VERSION ""

NS_ :

BS_:

BU_: WCM VPM VLM VKM UVM TIM TEST_TOOL_2 TEST_TOOL_1 TCP TCM TCCM3 TCCM STC SRR_SRR SRR_SLR SRR_RR SRR_RF SRR_LR_CR SRR_LF SIB SDM SCL SBZA_R SBZA_L SBM SADS RadioLow RSC RDCM PTM PDR PA NVM MTCM_R MTCM_L MSM_RR MSM_P MSM_LR MSM_D MSB2 MSB1 MRCM_R MRCM_L MFC LRR_HC LRR LIB1 IPC ICS_Info ICCM HVAC_FP_R HVAC_FP_F HUD_CAN HDLM FCM_LC FCM EPS EOCM_HCP2 EOCM_HCP1 EOCM ELM ECP_X1 ECP_MC ECP_E ECM EBCM DMS DEFC DCM CSM CMMb CMMa CGM BSM_MH BSM BCM ARS ARB APA AOS AMP ALC AHS AHL_AFL AGC

BO_ 1242 CGM_CAN5_PDU34: 8 CGM
 SG_ RRSCDS_Massg : 0|2@0+ (1,0) [0|2] "" CSM,RadioLow
 SG_ RRSCDS_LmbrUDnFdRr : 3|3@0+ (1,0) [0|5] "" CSM,RadioLow
 SG_ RRSCDS_MassgTyp : 7|4@0+ (1,0) [0|15] "" CSM,RadioLow
 SG_ RRSCDS_BkCshBlstInOt : 10|3@0+ (1,0) [0|5] "" CSM,RadioLow
 SG_ RRSCDS_HdrstFwdRrwd : 12|2@0+ (1,0) [0|3] "" CSM,RadioLow
 SG_ RRSCDS_LmbrFwdRr : 14|2@0+ (1,0) [0|3] "" CSM,RadioLow
 SG_ RRSCDS_HdrstFdRrUDn : 17|3@0+ (1,0) [0|5] "" CSM,RadioLow
 SG_ RRSCDS_UprShldrFdRr : 19|2@0+ (1,0) [0|3] "" CSM,RadioLow
 SG_ RRSCDS_CshBlstrInOut : 21|2@0+ (1,0) [0|3] "" CSM,RadioLow
 SG_ RRSCDS_HdrstWngInOt : 23|2@0+ (1,0) [0|3] "" CSM,RadioLow
 SG_ RRSCDS_HdrstUpDn : 25|2@0+ (1,0) [0|3] "" CSM,RadioLow
 SG_ RRSCDS_LmbrUpDwn : 27|2@0+ (1,0) [0|3] "" CSM,RadioLow
 SG_ RRSCDS_MassgIntsty : 30|3@0+ (1,0) [0|7] "" CSM,RadioLow
 SG_ EDADS_ShftIndSt : 32|2@0+ (1,0) [0|2] "" CSM,IPC
 SG_ RRSCDS_CshLgAdjFdRr : 34|2@0+ (1,0) [0|3] "" CSM,RadioLow
 SG_ RRSCDS_HdrstTltFwdRr : 36|2@0+ (1,0) [0|3] "" CSM,RadioLow
 SG_ RRSCDS_BkBlstrInOut : 38|2@0+ (1,0) [0|3] "" CSM,RadioLow
 SG_ RRSCDS_DispReq : 39|1@0+ (1,0) [0|1] "" CSM,RadioLow
 SG_ EDADS_RcmndtFwdGr : 42|4@0+ (1,0) [0|15] "" CSM,IPC
 SG_ EDADS_CrntFwdMsdGr : 46|4@0+ (1,0) [0|15] "" CSM,IPC
 SG_ CnvtblTpWndMtnReq : 50|3@0+ (1,0) [0|4] "" CSM
 SG_ CnvtblTpStat : 53|3@0+ (1,0) [0|5] "" AMP,CSM,IPC,RadioLow,VKM
 SG_ EDADS_EcoDrvShftIO : 54|1@0+ (1,0) [0|1] "" CSM,IPC
 SG_ DrvDrAjrStat : 56|1@0+ (1,0) [0|1] "" AMP,CSM,IPC,RadioLow,TCP,VKM
 SG_ DrvDrAjrStat_Inv : 57|1@0+ (1,0) [0|1] "" CSM,IPC,TCP,VKM
 SG_ FCAACCGapSeltn : 60|3@0+ (1,0) [0|4] "" CSM,IPC
 SG_ EsyExtCstCurSetVal : 63|3@0+ (1,0) [0|7] "" CSM,RadioLow

BO_ 1243 CGM_CAN5_PDU35: 8 CGM
 SG_ RFSCDS_LmbrUDnFdRr : 1|3@0+ (1,0) [0|5] "" CSM,RadioLow
 SG_ RFSCDS_UprShldrFdRr : 3|2@0+ (1,0) [0|3] "" CSM,RadioLow
 SG_ RFSCDS_MassgTyp : 7|4@0+ (1,0) [0|15] "" CSM,RadioLow
 SG_ RFSCDS_HdrstWngInOt : 9|2@0+ (1,0) [0|3] "" CSM,RadioLow
 SG_ RFSCDS_DispReq : 10|1@0+ (1,0) [0|1] "" CSM,RadioLow
 SG_ RFSCDS_BkBlstrInOut : 12|2@0+ (1,0) [0|3] "" CSM,RadioLow
 SG_ RFSCDS_HdrstFwdRrwd : 14|2@0+ (1,0) [0|3] "" CSM,RadioLow
 SG_ RFSCDS_LmbrFwdRr : 17|2@0+ (1,0) [0|3] "" CSM,RadioLow
 SG_ RFSCDS_HdrstTltFwdRr : 19|2@0+ (1,0) [0|3] "" CSM,RadioLow
 SG_ RFSCDS_HdrstUpDn : 21|2@0+ (1,0) [0|3] "" CSM,RadioLow
 SG_ RFSCDS_Massg : 23|2@0+ (1,0) [0|2] "" CSM,RadioLow
 SG_ RFSCDS_MassgIntsty : 26|3@0+ (1,0) [0|7] "" CSM,RadioLow
 SG_ RFSCDS_CshLgAdjFdRr : 28|2@0+ (1,0) [0|3] "" CSM,RadioLow
 SG_ RFSCDS_BkCshBlstInOt : 31|3@0+ (1,0) [0|5] "" CSM,RadioLow
 SG_ RPARS_LtCntr : 32|4@0+ (1,0) [0|14] "" CSM,IPC,RadioLow
 SG_ RFSCDS_LmbrUpDwn : 34|2@0+ (1,0) [0|3] "" CSM,RadioLow
 SG_ RFSCDS_HdrstFdRrUDn : 37|3@0+ (1,0) [0|5] "" CSM,RadioLow
 SG_ RFSCDS_CshBlstrInOut : 39|2@0+ (1,0) [0|3] "" CSM,RadioLow
 SG_ RPARS_RtCntr : 40|4@0+ (1,0) [0|14] "" CSM,IPC,RadioLow
 SG_ RPARS_Rt : 44|4@0+ (1,0) [0|14] "" CSM,IPC,RadioLow
 SG_ MemCmd : 48|4@0+ (1,0) [0|15] "" CSM,IPC
 SG_ RPARS_Lt : 52|4@0+ (1,0) [0|14] "" CSM,IPC,RadioLow
 SG_ CoDrvDrAjrStat : 56|1@0+ (1,0) [0|1] "" AMP,CSM,IPC,RadioLow,TCP,VKM
 SG_ CoDrvDrAjrStat_Inv : 57|1@0+ (1,0) [0|1] "" CSM,TCP,VKM
 SG_ AutMemRclCstCurSetVal : 60|3@0+ (1,0) [0|6] "" CSM,RadioLow

BO_ 1244 CGM_CAN5_PDU36: 8 CGM
 SG_ LRSCDS_BkBlstrInOut : 0|2@0+ (1,0) [0|3] "" CSM,RadioLow
 SG_ LRSCDS_UprShldrFdRr : 2|2@0+ (1,0) [0|3] "" CSM,RadioLow
 SG_ LRSCDS_CshBlstrInOut : 4|2@0+ (1,0) [0|3] "" CSM,RadioLow
 SG_ LRSCDS_HdrstFdRrUDn : 7|3@0+ (1,0) [0|5] "" CSM,RadioLow
 SG_ LRSCDS_HdrstTltFwdRr : 9|2@0+ (1,0) [0|3] "" CSM,RadioLow
 SG_ LRSCDS_HdrstUpDn : 11|2@0+ (1,0) [0|3] "" CSM,RadioLow
 SG_ LRSCDS_LmbrUpDwn : 13|2@0+ (1,0) [0|3] "" CSM,RadioLow
 SG_ LRSCDS_DispReq : 14|1@0+ (1,0) [0|1] "" CSM,RadioLow
 SG_ LRSCDS_MassgIntsty : 18|3@0+ (1,0) [0|7] "" CSM,RadioLow
 SG_ LRSCDS_HdrstWngInOt : 20|2@0+ (1,0) [0|3] "" CSM,RadioLow
 SG_ LRSCDS_LmbrUDnFdRr : 23|3@0+ (1,0) [0|5] "" CSM,RadioLow
 SG_ LRSCDS_CshLgAdjFdRr : 25|2@0+ (1,0) [0|3] "" CSM,RadioLow
 SG_ LRSCDS_HdrstFwdRrwd : 27|2@0+ (1,0) [0|3] "" CSM,RadioLow
 SG_ LRSCDS_LmbrFwdRr : 29|2@0+ (1,0) [0|3] "" CSM,RadioLow
 SG_ LRSCDS_Massg : 31|2@0+ (1,0) [0|2] "" CSM,RadioLow
 SG_ SAP_SecAxlOpMdAuth : 32|4@0+ (1,0) [0|9] "" CSM,IPC,TCP
 SG_ LRSCDS_BkCshBlstInOt : 35|3@0+ (1,0) [0|5] "" CSM,RadioLow
 SG_ LRSCDS_MassgTyp : 39|4@0+ (1,0) [0|15] "" CSM,RadioLow
 SG_ SAP_SecAxl4WDAWDEstTrqAuth : 40|10@0+ (10,0) [0|10230] "Nm" CSM
 SG_ SAP_SecAxl4WDAWDStatAuth : 42|2@0+ (1,0) [0|3] "" CSM
 SG_ SAP_SecAxlOpMdAuth_Inv : 43|1@0+ (1,0) [0|1] "" CSM
 SG_ SAP_SecAxl4WDAWDEstTrqAuth_Inv : 44|1@0+ (1,0) [0|1] "" CSM
 SG_ AdpLghtRspTypCstCurSetVal : 58|3@0+ (1,0) [0|7] "" CSM,RadioLow
 SG_ HSP_HptcStPrsntAuth : 59|1@0+ (1,0) [0|1] "" CSM
 SG_ HSP_DrvAlrtTypCstCurrSetValAuth : 62|3@0+ (1,0) [0|2] "" CSM,RadioLow

BO_ 1245 CGM_CAN5_PDU37: 8 CGM
 SG_ LFSCDS_LmbrUDnFdRr : 0|3@0+ (1,0) [0|5] "" CSM,RadioLow
 SG_ LFSCDS_DispReq : 1|1@0+ (1,0) [0|1] "" CSM,RadioLow
 SG_ LFSCDS_UprShldrFdRr : 3|2@0+ (1,0) [0|3] "" CSM,RadioLow
 SG_ LFSCDS_LmbrUpDwn : 5|2@0+ (1,0) [0|3] "" CSM,RadioLow
 SG_ LFSCDS_Massg : 7|2@0+ (1,0) [0|2] "" CSM,RadioLow
 SG_ LFSCDS_BkBlstrInOut : 9|2@0+ (1,0) [0|3] "" CSM,RadioLow
 SG_ LFSCDS_HdrstTltFwdRr : 11|2@0+ (1,0) [0|3] "" CSM,RadioLow
 SG_ LFSCDS_LmbrFwdRr : 13|2@0+ (1,0) [0|3] "" CSM,RadioLow
 SG_ LFSCDS_MassgTyp : 18|4@0+ (1,0) [0|15] "" CSM,RadioLow
 SG_ LFSCDS_HdrstFdRrUDn : 21|3@0+ (1,0) [0|5] "" CSM,RadioLow
 SG_ LFSCDS_CshBlstrInOut : 23|2@0+ (1,0) [0|3] "" CSM,RadioLow
 SG_ LFSCDS_HdrstUpDn : 25|2@0+ (1,0) [0|3] "" CSM,RadioLow
 SG_ LFSCDS_HdrstWngInOt : 27|2@0+ (1,0) [0|3] "" CSM,RadioLow
 SG_ LFSCDS_BkCshBlstInOt : 30|3@0+ (1,0) [0|5] "" CSM,RadioLow
 SG_ SDGPARS_CntrLtSd : 32|4@0+ (1,0) [0|14] "" IPC
 SG_ LFSCDS_MassgIntsty : 35|3@0+ (1,0) [0|7] "" CSM,RadioLow
 SG_ LFSCDS_CshLgAdjFdRr : 37|2@0+ (1,0) [0|3] "" CSM,RadioLow
 SG_ LFSCDS_HdrstFwdRrwd : 39|2@0+ (1,0) [0|3] "" CSM,RadioLow
 SG_ SDGPARS_FrtLtSd : 40|4@0+ (1,0) [0|14] "" IPC
 SG_ SDGPARS_RrRtSd : 44|4@0+ (1,0) [0|14] "" IPC
 SG_ SDGPARS_RrLtSd : 48|4@0+ (1,0) [0|14] "" IPC
 SG_ SDGPARS_CntrRtSd : 52|4@0+ (1,0) [0|14] "" IPC
 SG_ AutoHldEnbld : 56|1@0+ (1,0) [0|1] "" IPC
 SG_ SDGPARS_FrtRtSd : 60|4@0+ (1,0) [0|14] "" IPC

BO_ 1246 CGM_CAN5_PDU38: 8 CGM
 SG_ PCOSN_NtfnSecRowCntrStBltSts : 1|2@0+ (1,0) [0|3] "" TCP
 SG_ PCOSN_NtfnSecRowLtStBltSts : 3|2@0+ (1,0) [0|3] "" TCP
 SG_ PCOSN_NtfnThrdRowCntrStBltSts : 5|2@0+ (1,0) [0|3] "" TCP
 SG_ PCOSN_NtfnImpDeltVelTxSts : 7|2@0+ (1,0) [0|2] "" TCP
 SG_ PCOSN_NtfnImpMaxLongDeltVel : 9|8@0- (1,0) [-128|127] "kph" TCP
 SG_ PCOSN_NtfnSecRowCntrStOccpSts : 11|2@0+ (1,0) [0|3] "" TCP
 SG_ PCOSN_NtfnSecRowLtStOccpSts : 13|2@0+ (1,0) [0|3] "" TCP
 SG_ PCOSN_NtfnSecRowRtStBltSts : 15|2@0+ (1,0) [0|3] "" TCP
 SG_ PCOSN_NtfnThrdRowCntrStOccpSts : 17|2@0+ (1,0) [0|3] "" TCP
 SG_ PCOSN_NtfnImpMaxLatDeltVel : 31|8@0- (1,0) [-128|127] "kph" TCP
 SG_ PCOSN_NtfnEvntSyncCnt : 39|8@0+ (1,0) [0|255] "" TCP
 SG_ PCOSN_NtfnThrdRowRtStOccpSts : 40|2@0+ (1,0) [0|3] "" TCP
 SG_ PCOSN_NtfnFrstPsngrStBltSts : 42|2@0+ (1,0) [0|3] "" TCP
 SG_ PCOSN_NtfnFrstPsngrStOccpSts : 45|3@0+ (1,0) [0|3] "" TCP
 SG_ PCOSN_NtfnSecRowRtStOccpSts : 47|2@0+ (1,0) [0|3] "" TCP
 SG_ PCOSN_NtfnThrdRowLtStOccpSts : 48|2@0+ (1,0) [0|3] "" TCP
 SG_ PCOSN_NtfnThrdRowRtStBltSts : 50|2@0+ (1,0) [0|3] "" TCP
 SG_ PCOSN_NtfnDrvrStBltSts : 52|2@0+ (1,0) [0|3] "" TCP
 SG_ PCOSN_NtfnThrdRowLtStBltSts : 54|2@0+ (1,0) [0|3] "" TCP
 SG_ TDAP_DrvrStMemIdfrAuth : 58|3@0+ (1,0) [0|7] "" CSM,IPC
 SG_ TDAP_DrvrIdfrAuth : 61|3@0+ (1,0) [0|7] "" CSM,IPC,TCP,WCM
 SG_ TDAP_TeenDrvrActvAuth : 62|1@0+ (1,0) [0|1] "" CSM,IPC,PDR,RadioLow

BO_ 1247 CGM_CAN5_PDU39: 8 CGM
 SG_ RRSMP_Type5 : 3|4@0+ (1,0) [0|15] "" CSM,RadioLow
 SG_ RRSMP_Type14 : 7|4@0+ (1,0) [0|15] "" CSM,RadioLow
 SG_ RRSMP_Type2 : 8|4@0+ (1,0) [0|15] "" CSM,RadioLow
 SG_ RRSMP_Type10 : 12|4@0+ (1,0) [0|15] "" CSM,RadioLow
 SG_ RRSMP_MaxDispVal : 15|3@0+ (1,0) [0|7] "" CSM,RadioLow
 SG_ RRSMP_Type3 : 16|4@0+ (1,0) [0|15] "" CSM,RadioLow
 SG_ RRSMP_Type1 : 20|4@0+ (1,0) [0|15] "" CSM,RadioLow
 SG_ RRSMP_Type11 : 24|4@0+ (1,0) [0|15] "" CSM,RadioLow
 SG_ RRSMP_Type9 : 28|4@0+ (1,0) [0|15] "" CSM,RadioLow
 SG_ RRSMP_Type7 : 32|4@0+ (1,0) [0|15] "" CSM,RadioLow
 SG_ RRSMP_Type15 : 36|4@0+ (1,0) [0|15] "" CSM,RadioLow
 SG_ RRSMP_Type13 : 40|4@0+ (1,0) [0|15] "" CSM,RadioLow
 SG_ RRSMP_Type8 : 44|4@0+ (1,0) [0|15] "" CSM,RadioLow
 SG_ RRSMP_Type12 : 48|4@0+ (1,0) [0|15] "" CSM,RadioLow
 SG_ RRSMP_Type4 : 52|4@0+ (1,0) [0|15] "" CSM,RadioLow
 SG_ AutoHgBmActReq : 56|1@0+ (1,0) [0|1] "" CSM
 SG_ RRSMP_Type6 : 60|4@0+ (1,0) [0|15] "" CSM,RadioLow

BO_ 1248 CGM_CAN5_PDU40: 8 CGM
 SG_ RFSMP_Type7 : 3|4@0+ (1,0) [0|15] "" CSM,RadioLow
 SG_ RFSMP_Type12 : 7|4@0+ (1,0) [0|15] "" CSM,RadioLow
 SG_ RFSMP_Type14 : 11|4@0+ (1,0) [0|15] "" CSM,RadioLow
 SG_ RFSMP_Type3 : 15|4@0+ (1,0) [0|15] "" CSM,RadioLow
 SG_ RFSMP_Type13 : 19|4@0+ (1,0) [0|15] "" CSM,RadioLow
 SG_ RFSMP_Type4 : 23|4@0+ (1,0) [0|15] "" CSM,RadioLow
 SG_ RFSMP_Type5 : 24|4@0+ (1,0) [0|15] "" CSM,RadioLow
 SG_ RFSMP_MaxDispVal : 27|3@0+ (1,0) [0|7] "" CSM,RadioLow
 SG_ RFSMP_Type6 : 31|4@0+ (1,0) [0|15] "" CSM,RadioLow
 SG_ RFSMP_Type10 : 32|4@0+ (1,0) [0|15] "" CSM,RadioLow
 SG_ RFSMP_Type11 : 36|4@0+ (1,0) [0|15] "" CSM,RadioLow
 SG_ RFSMP_Type9 : 40|4@0+ (1,0) [0|15] "" CSM,RadioLow
 SG_ RFSMP_Type15 : 44|4@0+ (1,0) [0|15] "" CSM,RadioLow
 SG_ RFSMP_Type1 : 48|4@0+ (1,0) [0|15] "" CSM,RadioLow
 SG_ RFSMP_Type8 : 52|4@0+ (1,0) [0|15] "" CSM,RadioLow
 SG_ AutMemRclCstStAvl : 56|1@0+ (1,0) [0|1] "" CSM,RadioLow
 SG_ RFSMP_Type2 : 60|4@0+ (1,0) [0|15] "" CSM,RadioLow

BO_ 1249 CGM_CAN5_PDU41: 8 CGM
 SG_ LRSMP_Type6 : 3|4@0+ (1,0) [0|15] "" CSM,RadioLow
 SG_ LRSMP_Type15 : 7|4@0+ (1,0) [0|15] "" CSM,RadioLow
 SG_ LRSMP_Type13 : 11|4@0+ (1,0) [0|15] "" CSM,RadioLow
 SG_ LRSMP_Type2 : 15|4@0+ (1,0) [0|15] "" CSM,RadioLow
 SG_ LRSMP_Type5 : 16|4@0+ (1,0) [0|15] "" CSM,RadioLow
 SG_ LRSMP_MaxDispVal : 19|3@0+ (1,0) [0|7] "" CSM,RadioLow
 SG_ LRSMP_Type11 : 23|4@0+ (1,0) [0|15] "" CSM,RadioLow
 SG_ LRSMP_Type10 : 24|4@0+ (1,0) [0|15] "" CSM,RadioLow
 SG_ LRSMP_Type3 : 28|4@0+ (1,0) [0|15] "" CSM,RadioLow
 SG_ LRSMP_Type7 : 32|4@0+ (1,0) [0|15] "" CSM,RadioLow
 SG_ LRSMP_Type9 : 36|4@0+ (1,0) [0|15] "" CSM,RadioLow
 SG_ LRSMP_Type12 : 40|4@0+ (1,0) [0|15] "" CSM,RadioLow
 SG_ LRSMP_Type14 : 44|4@0+ (1,0) [0|15] "" CSM,RadioLow
 SG_ LRSMP_Type8 : 48|4@0+ (1,0) [0|15] "" CSM,RadioLow
 SG_ LRSMP_Type4 : 52|4@0+ (1,0) [0|15] "" CSM,RadioLow
 SG_ AdpLghtRspTypCstStAvl : 56|1@0+ (1,0) [0|1] "" CSM,RadioLow
 SG_ LRSMP_Type1 : 60|4@0+ (1,0) [0|15] "" CSM,RadioLow

BO_ 1250 CGM_CAN5_PDU42: 8 CGM
 SG_ LFSMP_Type1 : 3|4@0+ (1,0) [0|15] "" CSM,RadioLow
 SG_ LFSMP_Type10 : 7|4@0+ (1,0) [0|15] "" CSM,RadioLow
 SG_ LFSMP_Type2 : 11|4@0+ (1,0) [0|15] "" CSM,RadioLow
 SG_ LFSMP_Type9 : 15|4@0+ (1,0) [0|15] "" CSM,RadioLow
 SG_ LFSMP_Type11 : 19|4@0+ (1,0) [0|15] "" CSM,RadioLow
 SG_ LFSMP_Type13 : 23|4@0+ (1,0) [0|15] "" CSM,RadioLow
 SG_ LFSMP_Type4 : 27|4@0+ (1,0) [0|15] "" CSM,RadioLow
 SG_ LFSMP_Type12 : 31|4@0+ (1,0) [0|15] "" CSM,RadioLow
 SG_ LFSMP_Type14 : 35|4@0+ (1,0) [0|15] "" CSM,RadioLow
 SG_ LFSMP_Type5 : 39|4@0+ (1,0) [0|15] "" CSM,RadioLow
 SG_ LFSMP_Type6 : 43|4@0+ (1,0) [0|15] "" CSM,RadioLow
 SG_ LFSMP_Type3 : 47|4@0+ (1,0) [0|15] "" CSM,RadioLow
 SG_ LFSMP_Type8 : 51|4@0+ (1,0) [0|15] "" CSM,RadioLow
 SG_ LFSMP_Type7 : 55|4@0+ (1,0) [0|15] "" CSM,RadioLow
 SG_ ACCBRP_ACCActvAuth : 56|1@0+ (1,0) [0|1] "" IPC
 SG_ LFSMP_Type15 : 60|4@0+ (1,0) [0|15] "" CSM,RadioLow
 SG_ LFSMP_MaxDispVal : 63|3@0+ (1,0) [0|7] "" CSM,RadioLow

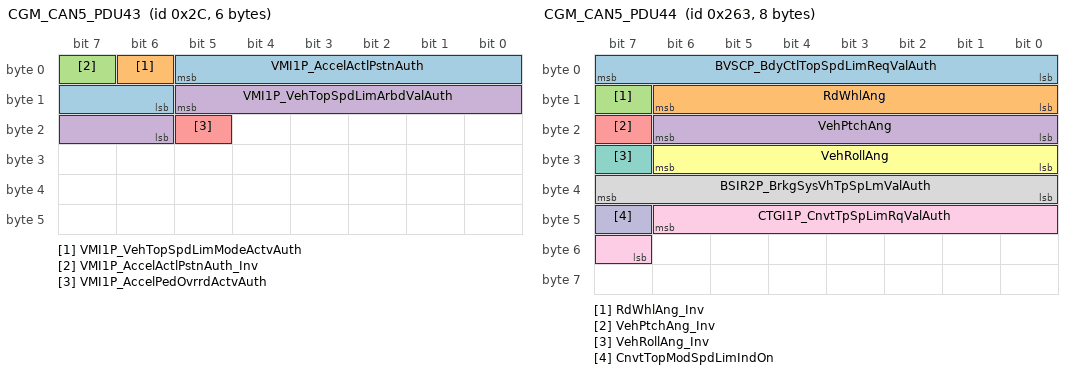
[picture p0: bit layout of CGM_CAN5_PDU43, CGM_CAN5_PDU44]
BO_ 44 CGM_CAN5_PDU43: 6 CGM
 SG_ VMI1P_AccelActlPstnAuth : 5|8@0+ (0.392157,0) [0|100] "%" AMP,CSM,PDR,TCP
 SG_ VMI1P_VehTopSpdLimModeActvAuth : 6|1@0+ (1,0) [0|1] "" CSM,IPC
 SG_ VMI1P_AccelActlPstnAuth_Inv : 7|1@0+ (1,0) [0|1] "" AMP,CSM,PDR
 SG_ VMI1P_VehTopSpdLimArbdValAuth : 13|8@0+ (2,0) [0|510] "km / h" CSM,IPC
 SG_ VMI1P_AccelPedOvrrdActvAuth : 21|1@0+ (1,0) [0|1] "" CSM,IPC

BO_ 611 CGM_CAN5_PDU44: 8 CGM
 SG_ BVSCP_BdyCtlTopSpdLimReqValAuth : 7|8@0+ (1,0) [0|255] "kph" IPC
 SG_ RdWhlAng : 14|7@0- (0.703125,0) [-45|44.2969] "deg" CSM,IPC
 SG_ RdWhlAng_Inv : 15|1@0+ (1,0) [0|1] "" CSM,IPC
 SG_ VehPtchAng : 22|7@0- (0.703125,0) [-45|44.2969] "deg" CSM,IPC
 SG_ VehPtchAng_Inv : 23|1@0+ (1,0) [0|1] "" IPC
 SG_ VehRollAng : 30|7@0- (0.703125,0) [-45|44.2969] "deg" CSM,IPC
 SG_ VehRollAng_Inv : 31|1@0+ (1,0) [0|1] "" IPC
 SG_ BSIR2P_BrkgSysVhTpSpLmValAuth : 39|8@0+ (2,0) [0|510] "kph" IPC
 SG_ CTGI1P_CnvtTpSpLimRqValAuth : 46|8@0+ (2,0) [0|510] "kph" IPC
 SG_ CnvtTopModSpdLimIndOn : 47|1@0+ (1,0) [0|1] "" IPC

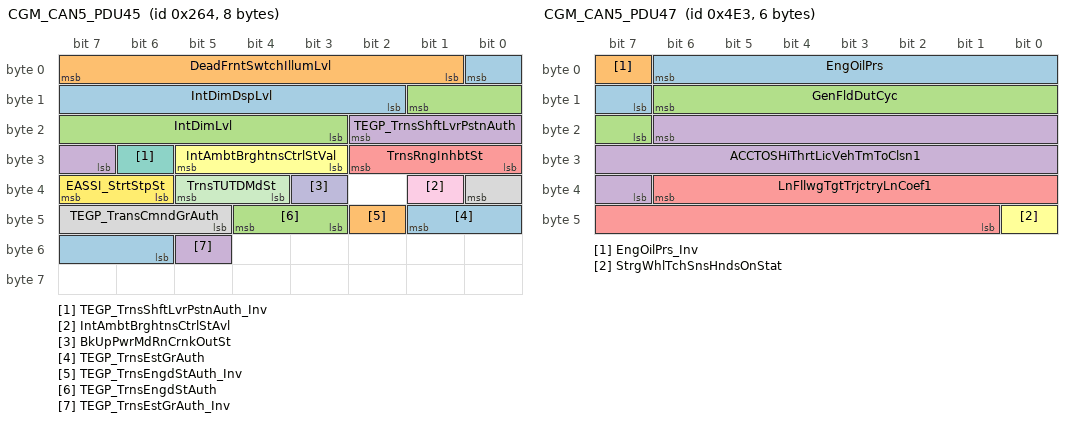
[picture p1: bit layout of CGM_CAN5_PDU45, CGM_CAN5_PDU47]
BO_ 612 CGM_CAN5_PDU45: 8 CGM
 SG_ IntDimDspLvl : 0|7@0+ (1,0) [0|127] "%" CSM,HUD_CAN,HVAC_FP_F,HVAC_FP_R,IPC,MFC,RadioLow
 SG_ DeadFrntSwtchIllumLvl : 7|7@0+ (1,0) [0|127] "%" CSM,HVAC_FP_F,HVAC_FP_R,MFC,RadioLow
 SG_ IntDimLvl : 9|7@0+ (1,0) [0|127] "%" CSM,HVAC_FP_F,HVAC_FP_R,IPC,MFC,RadioLow
 SG_ TEGP_TrnsShftLvrPstnAuth : 18|4@0+ (1,0) [0|14] "" CSM,IPC,RadioLow,TCP
 SG_ TrnsRngInhbtSt : 26|3@0+ (1,0) [0|4] "" CSM
 SG_ IntAmbtBrghtnsCtrlStVal : 29|3@0+ (1,0) [0|7] "" CSM,RadioLow
 SG_ TEGP_TrnsShftLvrPstnAuth_Inv : 30|1@0+ (1,0) [0|1] "" CSM,IPC,RadioLow,TCP
 SG_ TEGP_TransCmndGrAuth : 32|4@0+ (1,0) [0|15] "" AMP,CSM,IPC,TCP
 SG_ IntAmbtBrghtnsCtrlStAvl : 33|1@0+ (1,0) [0|1] "" CSM,RadioLow
 SG_ BkUpPwrMdRnCrnkOutSt : 35|1@0+ (1,0) [0|1] "" AGC,AMP,CSM,HVAC_FP_F,HVAC_FP_R,ICS_Info,IPC,PDR,MFC,RSC,RadioLow,TCP,WCM
 SG_ TrnsTUTDMdSt : 37|2@0+ (1,0) [0|2] "" CSM,IPC
 SG_ EASSI_StrtStpSt : 39|2@0+ (1,0) [0|3] "" AMP,IPC,PDR,RadioLow
 SG_ TEGP_TrnsEstGrAuth : 41|4@0+ (1,0) [0|15] "" AMP,CSM,ICS_Info,IPC,PDR,TCP
 SG_ TEGP_TrnsEngdStAuth_Inv : 42|1@0+ (1,0) [0|1] "" AMP,CSM,IPC,TCP
 SG_ TEGP_TrnsEngdStAuth : 44|2@0+ (1,0) [0|3] "" AMP,CSM,IPC,TCP
 SG_ TEGP_TrnsEstGrAuth_Inv : 53|1@0+ (1,0) [0|1] "" AMP,CSM,IPC,PDR,TCP

BO_ 181 CGM_CAN5_PDU46: 8 CGM
 SG_ FWDECP_LFAuth : 4|11@0+ (1,0) [0|2047] "" CSM,PDR,TCP
 SG_ FWDECP_RFAuth_Inv : 5|1@0+ (1,0) [0|1] "" PDR
 SG_ FWDECP_RstOccAuth : 6|1@0+ (1,0) [0|1] "" CSM,PDR,TCP
 SG_ FWDECP_LFAuth_Inv : 7|1@0+ (1,0) [0|1] "" PDR
 SG_ FWDECP_RFAuth : 9|11@0+ (1,0) [0|2047] "" CSM,PDR,TCP
 SG_ RWDECP_LRAuth : 27|11@0+ (1,0) [0|2047] "" CSM,PDR,TCP
 SG_ RWDECP_RRAuth_Inv : 28|1@0+ (1,0) [0|1] "" PDR
 SG_ RWDECP_RstOccAuth : 29|1@0+ (1,0) [0|1] "" CSM,PDR,TCP
 SG_ RWDECP_LRAuth_Inv : 30|1@0+ (1,0) [0|1] "" PDR
 SG_ RWDECP_RRAuth : 32|11@0+ (1,0) [0|2047] "" CSM,PDR,TCP
 SG_ ASPATR_ClsnImntBrkgAxlTrqRqActv : 48|1@0+ (1,0) [0|1] "" TCP
 SG_ CIBAutoBrkReqActv : 49|1@0+ (1,0) [0|1] "" TCP
 SG_ DMSIP_DrvrAttnStatAuth_Inv : 50|1@0+ (1,0) [0|1] "" TCP
 SG_ DMSIP_DrvrAttnStatAuth : 53|3@0+ (1,0) [0|6] "" TCP
 SG_ ACCBRP_ReqActvAuth : 61|1@0+ (1,0) [0|1] "" TCP
 SG_ ACCATRIP_TrqActvAuth : 62|1@0+ (1,0) [0|1] "" TCP
 SG_ LCCPIP_LnCntrCtlAclPedLimRqAuth : 63|1@0+ (1,0) [0|1] "" TCP

BO_ 1251 CGM_CAN5_PDU47: 6 CGM
 SG_ EngOilPrs : 6|8@0+ (4,0) [0|1020] "kPa" CSM,IPC,PDR,TCP
 SG_ EngOilPrs_Inv : 7|1@0+ (1,0) [0|1] "" CSM,IPC,PDR,TCP
 SG_ GenFldDutCyc : 14|8@0+ (0.392157,0) [0|100] "%" CSM
 SG_ ACCTOSHiThrtLicVehTmToClsn1 : 22|16@0+ (0.001,0) [0|65.535] "s" TCP
 SG_ LnFllwgTgtTrjctryLnCoef1 : 38|14@0- (0.00125,0) [-10.24|10.2388] "m/m" TCP
 SG_ StrgWhlTchSnsHndsOnStat : 40|1@0+ (1,0) [0|1] "" TCP

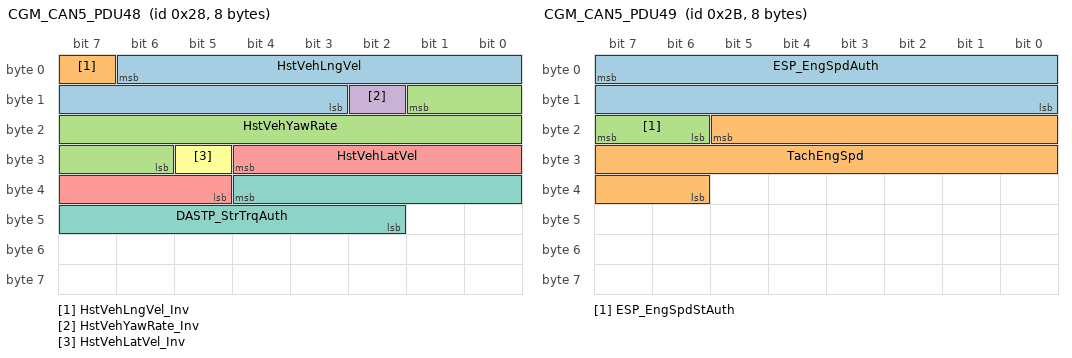
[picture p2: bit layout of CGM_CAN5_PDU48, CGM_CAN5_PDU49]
BO_ 40 CGM_CAN5_PDU48: 8 CGM
 SG_ HstVehLngVel : 6|12@0- (0.0625,0) [-128|127.938] "m/s" CSM
 SG_ HstVehLngVel_Inv : 7|1@0+ (1,0) [0|1] "" CSM
 SG_ HstVehYawRate : 9|12@0- (0.0625,0) [-128|127.938] "deg/s" CSM
 SG_ HstVehYawRate_Inv : 10|1@0+ (1,0) [0|1] "" CSM
 SG_ HstVehLatVel : 28|8@0- (0.05,0) [-6.4|6.35] "m/s" CSM
 SG_ HstVehLatVel_Inv : 29|1@0+ (1,0) [0|1] "" CSM
 SG_ DASTP_StrTrqAuth : 36|11@0- (0.01,0) [-10.24|10.23] "Nm" TCP

BO_ 43 CGM_CAN5_PDU49: 8 CGM
 SG_ ESP_EngSpdAuth : 7|16@0+ (0.25,0) [0|16383.8] "rpm" AMP,CSM,IPC,PDR,RadioLow,TCP
 SG_ TachEngSpd : 21|16@0+ (0.25,0) [0|16383.8] "RPM" IPC
 SG_ ESP_EngSpdStAuth : 23|2@0+ (1,0) [0|2] "" AMP,CSM,IPC,RadioLow

BO_ 1172 CGM_CAN5_PDU50: 8 CGM
 SG_ TrlrTirePresProfXferSts : 0|2@0+ (1,0) [0|3] "" CSM
 SG_ FrwdVehAhdIndReq : 3|3@0+ (1,0) [0|5] "" CSM,IPC,TCP
 SG_ LnchCtlLineLckTmrVal : 7|4@0+ (1,0) [0|15] "sec" IPC
 SG_ ServPedtrnFrndlyAlrtIndOn : 8|1@0+ (1,0) [0|1] "" IPC
 SG_ RrAxlTmpInhIO : 9|1@0+ (1,0) [0|1] "" CSM,IPC
 SG_ RrAxlMlfIO : 10|1@0+ (1,0) [0|1] "" CSM,IPC
 SG_ RegVltgCtlEngyRcvryActv : 11|1@0+ (1,0) [0|1] "" IPC
 SG_ HillDscntCtlDispActvIndOn : 12|1@0+ (1,0) [0|1] "" IPC
 SG_ Deg360VidFtrPrsnt : 13|1@0+ (1,0) [0|1] "" CSM
 SG_ BrkgSysVehTopSpdLimIndOn : 14|1@0+ (1,0) [0|1] "" IPC
 SG_ PrplDispTotPwr : 18|13@0+ (0.5,-325) [-325|3770.5] "" CSM,IPC,PDR
 SG_ TrgrdVidRcrdrFtrPrsnt : 19|1@0+ (1,0) [0|1] "" CSM
 SG_ TireRRLoTracIndOn : 20|1@0+ (1,0) [0|1] "" CSM,IPC
 SG_ TireRFLoTracIndOn : 21|1@0+ (1,0) [0|1] "" CSM,IPC
 SG_ TireLRLoTracIndOn : 22|1@0+ (1,0) [0|1] "" CSM,IPC
 SG_ TireLFLoTracIndOn : 23|1@0+ (1,0) [0|1] "" CSM,IPC
 SG_ TDRevClnMtgnBrEvRpt : 37|10@0+ (1,0) [0|1023] "Counts" CSM,RadioLow,TCP
 SG_ MemIdfrIgnOnIndReq : 43|4@0+ (1,0) [0|8] "" IPC
 SG_ HybStatElecVehModeOvrrd : 50|3@0+ (1,0) [0|7] "" IPC
 SG_ ROSP_FrntPsRestOcpStatAuth : 55|2@0+ (1,0) [0|3] "" CSM
 SG_ HiVltgBatAvgTemp : 62|7@0+ (1,-40) [-40|87] "deg C" CSM,IPC,PDR
 SG_ HiVltgBatAvgTemp_Inv : 63|1@0+ (1,0) [0|1] "" CSM,IPC,PDR

BO_ 1253 CGM_CAN5_PDU52: 6 CGM
 SG_ SLVFSP_SpdLimVsnFsdSpdAuth : 7|8@0+ (1,0) [0|255] "" IPC
 SG_ SLVFSP_SpdLimVsnFsdSpdUntAuth : 15|1@0+ (1,0) [0|1] "" IPC

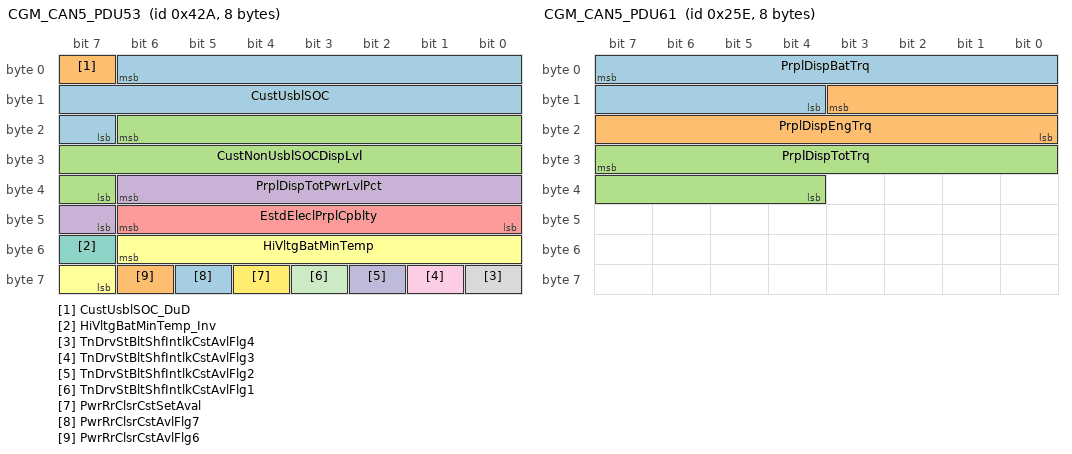
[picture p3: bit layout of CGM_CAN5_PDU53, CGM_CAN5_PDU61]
BO_ 1066 CGM_CAN5_PDU53: 8 CGM
 SG_ CustUsblSOC : 6|16@0+ (0.00152588,0) [0|99.9985] "%" CSM,IPC,PDR
 SG_ CustUsblSOC_DuD : 7|1@0+ (1,0) [0|1] "" CSM,IPC,PDR
 SG_ CustNonUsblSOCDispLvl : 22|16@0+ (0.00152588,0) [0|99.9985] "%" IPC
 SG_ PrplDispTotPwrLvlPct : 38|8@0- (1,0) [-128|127] "%" CSM,IPC,PDR
 SG_ EstdEleclPrplCpblty : 46|7@0+ (1,0) [0|127] "%" CSM,IPC
 SG_ HiVltgBatMinTemp : 54|8@0+ (0.5,-40) [-40|87.5] "Deg C" PDR
 SG_ HiVltgBatMinTemp_Inv : 55|1@0+ (1,0) [0|1] "" PDR
 SG_ TnDrvStBltShfIntlkCstAvlFlg4 : 56|1@0+ (1,0) [0|1] "" CSM,RadioLow
 SG_ TnDrvStBltShfIntlkCstAvlFlg3 : 57|1@0+ (1,0) [0|1] "" CSM,RadioLow
 SG_ TnDrvStBltShfIntlkCstAvlFlg2 : 58|1@0+ (1,0) [0|1] "" CSM,RadioLow
 SG_ TnDrvStBltShfIntlkCstAvlFlg1 : 59|1@0+ (1,0) [0|1] "" CSM,RadioLow
 SG_ PwrRrClsrCstSetAval : 60|1@0+ (1,0) [0|1] "" CSM,RadioLow
 SG_ PwrRrClsrCstAvlFlg7 : 61|1@0+ (1,0) [0|1] "" CSM,RadioLow
 SG_ PwrRrClsrCstAvlFlg6 : 62|1@0+ (1,0) [0|1] "" CSM,RadioLow

BO_ 1107 CGM_CAN5_PDU57: 8 CGM
 SG_ BatPrplDispPwrLvlPct : 7|8@0- (1,0) [-128|127] "%" CSM,IPC,PDR
 SG_ RegenPwrLimdDispPct : 15|8@0- (1,0) [-128|127] "%" IPC,PDR
 SG_ PrplCpbltyDispOprtgPstn : 16|7@0+ (1,0) [0|127] "%" CSM,IPC
 SG_ EngPrplDispPwrLvlPct : 23|7@0+ (1,0) [0|127] "%" CSM,IPC,PDR
 SG_ MemIdfrMemStorIndReq : 25|4@0+ (1,0) [0|8] "" IPC
 SG_ ServHiVltgBatIndReq : 33|2@0+ (1,0) [0|2] "" IPC
 SG_ HtdStrgWhlInd_HVAC_FP_F : 35|2@0+ (1,0) [0|3] "" HVAC_FP_F
 SG_ HiVltgBatLmtnDueToTempInd : 37|2@0+ (1,0) [0|2] "" IPC
 SG_ ServHybSysIndOn : 40|1@0+ (1,0) [0|1] "" IPC
 SG_ ReqFrtPsgrRstntOccFltInd : 41|1@0+ (1,0) [0|1] "" CSM,RadioLow
 SG_ RegenPwrLimdIndOn : 42|1@0+ (1,0) [0|1] "" IPC,PDR
 SG_ RegenPwrLimdDispPctVsbl : 43|1@0+ (1,0) [0|1] "" IPC,PDR
 SG_ PrplDispTotPwrUntDisp : 44|1@0+ (1,0) [0|1] "" CSM,IPC,PDR
 SG_ LossOfPrplIndOn : 45|1@0+ (1,0) [0|1] "" IPC
 SG_ HybShfToPrkIndOn : 46|1@0+ (1,0) [0|1] "" IPC
 SG_ EngRnngDueToVehSpdIndOn : 47|1@0+ (1,0) [0|1] "" IPC
 SG_ InstnsFuelEconHybOvrrdReq : 49|3@0+ (1,0) [0|4] "" IPC
 SG_ HybStatShtlModeOvrrd : 55|3@0+ (1,0) [0|7] "" IPC
 SG_ DM6Denied : 56|1@0+ (1,0) [0|1] "" IPC
 SG_ DM5Denied : 57|1@0+ (1,0) [0|1] "" IPC
 SG_ DM4Denied : 58|1@0+ (1,0) [0|1] "" IPC
 SG_ DM3Denied : 59|1@0+ (1,0) [0|1] "" IPC
 SG_ JmpStrtSts : 62|3@0+ (1,0) [0|4] "" IPC

BO_ 521 CGM_CAN5_PDU59: 4 CGM
 SG_ TSP_TmpDrvrShfCtlActvAuth : 6|1@0+ (1,0) [0|1] "" IPC
 SG_ TSP_ElecRngSeltnInDrvActvAuth : 7|1@0+ (1,0) [0|1] "" IPC

BO_ 45 CGM_CAN5_PDU60: 8 CGM
 SG_ VCBA_FrtJnctnActv : 0|1@0+ (1,0) [0|1] "" CSM
 SG_ VCBA_DynGdlnsActv : 1|1@0+ (1,0) [0|1] "" CSM
 SG_ VCBA_CurbVwGdlnsActv : 2|1@0+ (1,0) [0|1] "" CSM
 SG_ VCBA_CurbOvrhdActv : 3|1@0+ (1,0) [0|1] "" CSM
 SG_ VCBA_CurbActv : 4|1@0+ (1,0) [0|1] "" CSM
 SG_ VCBA_CrgBedActv : 5|1@0+ (1,0) [0|1] "" CSM
 SG_ VCBA_BowlActv : 6|1@0+ (1,0) [0|1] "" CSM
 SG_ VCBA_BedHtchActv : 7|1@0+ (1,0) [0|1] "" CSM
 SG_ VCBA_RrOvrhdActv : 8|1@0+ (1,0) [0|1] "" CSM
 SG_ VCBA_RrJnctnActv : 9|1@0+ (1,0) [0|1] "" CSM
 SG_ VCBA_RrHtchActv : 10|1@0+ (1,0) [0|1] "" CSM
 SG_ VCBA_LRTrlrTowMirActv : 11|1@0+ (1,0) [0|1] "" CSM
 SG_ VCBA_JPActv : 12|1@0+ (1,0) [0|1] "" CSM
 SG_ VCBA_InvsblTrlrActv : 13|1@0+ (1,0) [0|1] "" CSM
 SG_ VCBA_FrtPrspctvActv : 14|1@0+ (1,0) [0|1] "" CSM
 SG_ VCBA_FrtOvrhdActv : 15|1@0+ (1,0) [0|1] "" CSM
 SG_ VCBA_TrlrTowMirActv : 16|1@0+ (1,0) [0|1] "" CSM
 SG_ VCBA_TrlrGdlnsActv : 17|1@0+ (1,0) [0|1] "" CSM
 SG_ VCBA_TrlrAux2Actv : 18|1@0+ (1,0) [0|1] "" CSM
 SG_ VCBA_TrlrAux1CmbdActv : 19|1@0+ (1,0) [0|1] "" CSM
 SG_ VCBA_TrlrAux1Actv : 20|1@0+ (1,0) [0|1] "" CSM
 SG_ VCBA_SdRrwdActv : 21|1@0+ (1,0) [0|1] "" CSM
 SG_ VCBA_SdFrwdActv : 22|1@0+ (1,0) [0|1] "" CSM
 SG_ VCBA_RrPrspctvActv : 23|1@0+ (1,0) [0|1] "" CSM
 SG_ VwgBowlVwAngSts : 30|9@0+ (1,0) [0|511] "degrees" CSM
 SG_ VCBA_ZmdBowlActv : 31|1@0+ (1,0) [0|1] "" CSM
 SG_ SrrndVsnRcrdrNumDispdFiles : 34|3@0+ (1,0) [0|7] "" CSM
 SG_ SrrndVsnRcrdrDelFileReqSts : 37|3@0+ (1,0) [0|7] "" CSM
 SG_ SrrndVsnRcrdrVwprtSts : 41|3@0+ (1,0) [0|7] "" CSM
 SG_ SrrndVsnRcrdrVwprtReq : 44|3@0+ (1,0) [0|7] "" CSM
 SG_ SrrndVsnRcrdrPlybkSts : 47|3@0+ (1,0) [0|5] "" CSM
 SG_ SrrndVsnRcrdrRcrdSts : 49|2@0+ (1,0) [0|2] "" CSM
 SG_ SrrndVsnRcrdrListPgSts : 51|2@0+ (1,0) [0|3] "" CSM
 SG_ VGVS_TrlrActv : 52|1@0+ (1,0) [0|1] "" CSM
 SG_ VGVS_DynActv : 53|1@0+ (1,0) [0|1] "" CSM
 SG_ VGVS_CurbVwActv : 54|1@0+ (1,0) [0|1] "" CSM
 SG_ VCBA_TrnspHdActv : 60|1@0+ (1,0) [0|1] "" CSM
 SG_ SrrndVsnRcrdrRcrdgActv : 61|1@0+ (1,0) [0|1] "" CSM
 SG_ SVRCBA_PgUpActv : 62|1@0+ (1,0) [0|1] "" CSM
 SG_ SVRCBA_PgDnActv : 63|1@0+ (1,0) [0|1] "" CSM

BO_ 606 CGM_CAN5_PDU61: 8 CGM
 SG_ PrplDispBatTrq : 7|12@0+ (0.5,-848) [-848|1199.5] "Nm" CSM,PDR
 SG_ PrplDispEngTrq : 11|12@0+ (0.5,-848) [-848|1199.5] "Nm" CSM,PDR
 SG_ PrplDispTotTrq : 31|12@0+ (0.5,-848) [-848|1199.5] "Nm" CSM,PDR

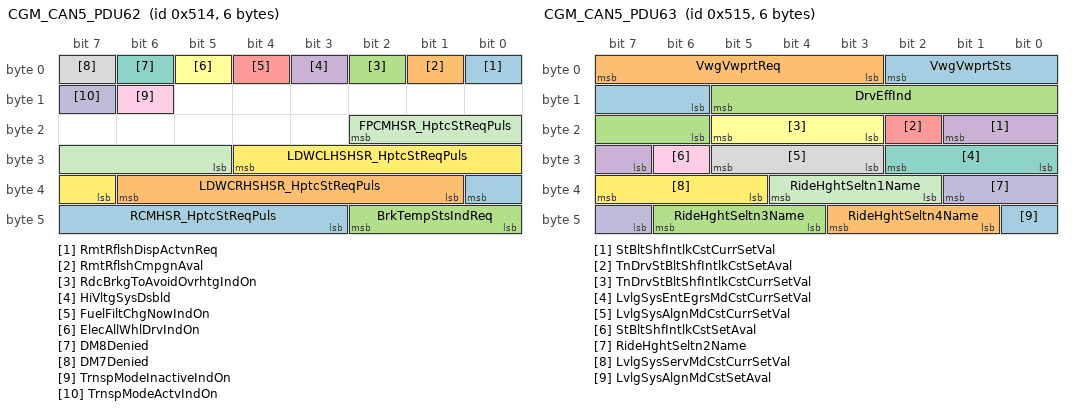
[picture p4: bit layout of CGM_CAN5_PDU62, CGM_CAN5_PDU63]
BO_ 1300 CGM_CAN5_PDU62: 6 CGM
 SG_ RmtRflshDispActvnReq : 0|1@0+ (1,0) [0|1] "" CSM,RadioLow
 SG_ RmtRflshCmpgnAval : 1|1@0+ (1,0) [0|1] "" CSM,RadioLow
 SG_ RdcBrkgToAvoidOvrhtgIndOn : 2|1@0+ (1,0) [0|1] "" IPC
 SG_ HiVltgSysDsbld : 3|1@0+ (1,0) [0|1] "" TCP
 SG_ FuelFiltChgNowIndOn : 4|1@0+ (1,0) [0|1] "" IPC
 SG_ ElecAllWhlDrvIndOn : 5|1@0+ (1,0) [0|1] "" IPC,PDR
 SG_ DM8Denied : 6|1@0+ (1,0) [0|1] "" IPC
 SG_ DM7Denied : 7|1@0+ (1,0) [0|1] "" IPC
 SG_ TrnspModeInactiveIndOn : 14|1@0+ (1,0) [0|1] "" IPC
 SG_ TrnspModeActvIndOn : 15|1@0+ (1,0) [0|1] "" IPC
 SG_ FPCMHSR_HptcStReqPuls : 18|6@0+ (1,0) [0|63] "pulses" CSM
 SG_ LDWCLHSHSR_HptcStReqPuls : 28|6@0+ (1,0) [0|63] "pulses" CSM
 SG_ RCMHSR_HptcStReqPuls : 32|6@0+ (1,0) [0|63] "pulses" CSM
 SG_ LDWCRHSHSR_HptcStReqPuls : 38|6@0+ (1,0) [0|63] "pulses" CSM
 SG_ BrkTempStsIndReq : 42|3@0+ (1,0) [0|4] "" IPC

BO_ 1301 CGM_CAN5_PDU63: 6 CGM
 SG_ VwgVwprtSts : 2|5@0+ (1,0) [0|24] "" CSM
 SG_ VwgVwprtReq : 7|5@0+ (1,0) [0|24] "" CSM
 SG_ DrvEffInd : 13|8@0- (0.78125,0) [-100|99.2188] "%" CSM,IPC
 SG_ StBltShfIntlkCstCurrSetVal : 17|3@0+ (1,0) [0|7] "" CSM,RadioLow
 SG_ TnDrvStBltShfIntlkCstSetAval : 18|1@0+ (1,0) [0|1] "" CSM,RadioLow
 SG_ TnDrvStBltShfIntlkCstCurrSetVal : 21|3@0+ (1,0) [0|7] "" CSM,RadioLow
 SG_ LvlgSysEntEgrsMdCstCurrSetVal : 26|3@0+ (1,0) [0|7] "" CSM,RadioLow
 SG_ LvlgSysAlgnMdCstCurrSetVal : 29|3@0+ (1,0) [0|7] "" CSM,RadioLow
 SG_ StBltShfIntlkCstSetAval : 30|1@0+ (1,0) [0|1] "" CSM,RadioLow
 SG_ RideHghtSeltn2Name : 33|3@0+ (1,0) [0|7] "" IPC
 SG_ RideHghtSeltn1Name : 36|3@0+ (1,0) [0|7] "" IPC
 SG_ LvlgSysServMdCstCurrSetVal : 39|3@0+ (1,0) [0|7] "" CSM,RadioLow
 SG_ LvlgSysAlgnMdCstSetAval : 40|1@0+ (1,0) [0|1] "" CSM,RadioLow
 SG_ RideHghtSeltn4Name : 43|3@0+ (1,0) [0|7] "" IPC
 SG_ RideHghtSeltn3Name : 46|3@0+ (1,0) [0|7] "" IPC

BO_ 140 CGM_CAN5_PDU64: 6 CGM
 SG_ RdLdNomAxlTrq : 7|19@0+ (0.125,-22534) [-22534|43001.9] "Nm" CSM

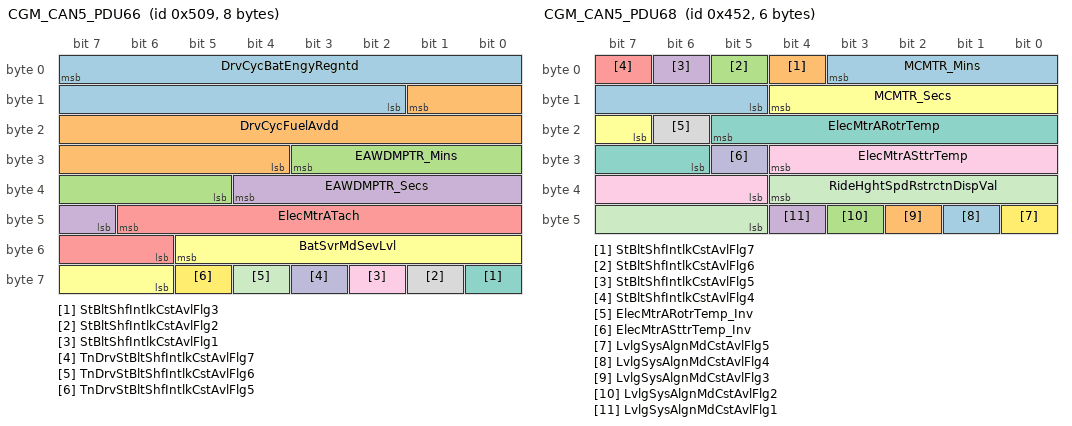
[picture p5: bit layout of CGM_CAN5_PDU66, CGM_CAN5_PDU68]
BO_ 1289 CGM_CAN5_PDU66: 8 CGM
 SG_ DrvCycBatEngyRegntd : 7|14@0+ (0.36,0) [0|5897.88] "MJ" CSM
 SG_ DrvCycFuelAvdd : 9|14@0+ (0.0378541,0) [0|620.164] "liters" CSM
 SG_ EAWDMPTR_Mins : 27|7@0+ (1,0) [0|127] "minutes" CSM
 SG_ EAWDMPTR_Secs : 36|6@0+ (1,0) [0|63] "seconds" CSM
 SG_ ElecMtrATach : 46|9@0- (100,0) [-25600|25500] "rpm" CSM
 SG_ BatSvrMdSevLvl : 53|8@0+ (1,0) [0|255] "" TCP
 SG_ StBltShfIntlkCstAvlFlg3 : 56|1@0+ (1,0) [0|1] "" CSM,RadioLow
 SG_ StBltShfIntlkCstAvlFlg2 : 57|1@0+ (1,0) [0|1] "" CSM,RadioLow
 SG_ StBltShfIntlkCstAvlFlg1 : 58|1@0+ (1,0) [0|1] "" CSM,RadioLow
 SG_ TnDrvStBltShfIntlkCstAvlFlg7 : 59|1@0+ (1,0) [0|1] "" CSM,RadioLow
 SG_ TnDrvStBltShfIntlkCstAvlFlg6 : 60|1@0+ (1,0) [0|1] "" CSM,RadioLow
 SG_ TnDrvStBltShfIntlkCstAvlFlg5 : 61|1@0+ (1,0) [0|1] "" CSM,RadioLow

BO_ 1298 CGM_CAN5_PDU67: 8 CGM
 SG_ RPCMHSR_HptcStReqPuls : 1|6@0+ (1,0) [0|63] "pulses" CSM
 SG_ RCTALSHSR_HptcStReqPuls : 7|6@0+ (1,0) [0|63] "pulses" CSM
 SG_ HybModeDisp : 11|5@0+ (1,0) [0|16] "" CSM
 SG_ RrClsrLckSts : 16|2@0+ (1,0) [0|2] "" TCP
 SG_ RdHgtActvnIndReq : 19|3@0+ (1,0) [0|5] "" IPC
 SG_ HybModeDispVehCfg : 22|3@0+ (1,0) [0|4] "" CSM
 SG_ RCTARSHSR_HptcStReqPuls : 24|2@0+ (1,0) [0|3] "pulses" CSM
 SG_ WhlSlpSt : 26|2@0+ (1,0) [0|3] "" CSM
 SG_ SBZALCAVisIndStatRt : 28|2@0+ (1,0) [0|2] "" CSM
 SG_ SBZALCAVisIndStatLt : 30|2@0+ (1,0) [0|2] "" CSM
 SG_ FrFgLmpIO : 32|1@0+ (1,0) [0|1] "" CSM,IPC
 SG_ ShftrUnlckdBrktoShfIndOn : 33|1@0+ (1,0) [0|1] "" IPC
 SG_ ShftrLckdBcklPsngrStBltIndOn : 34|1@0+ (1,0) [0|1] "" IPC
 SG_ ShftrLckdBcklDrvrStBltIndOn : 35|1@0+ (1,0) [0|1] "" IPC
 SG_ FuelSysNEmsRltMlfActv : 37|1@0+ (1,0) [0|1] "" IPC
 SG_ DCCnvStblznErrIndOn : 38|1@0+ (1,0) [0|1] "" IPC
 SG_ ACCSpdLimSgnVal : 41|8@0+ (1,0) [0|255] "" IPC
 SG_ NtVsnVidBrghtnsSts : 44|3@0+ (1,0) [0|7] "" IPC
 SG_ AnmlWrnIndReq : 46|2@0+ (1,0) [0|2] "" IPC
 SG_ RrFgLmpIO : 47|1@0+ (1,0) [0|1] "" CSM,IPC
 SG_ SpdLmtrSpdLimSgnVal : 49|8@0+ (1,0) [0|255] "" IPC
 SG_ IdlRecmndToClEngIO : 56|1@0+ (1,0) [0|1] "" IPC
 SG_ ACCSpdLimSgnUnt : 57|1@0+ (1,0) [0|1] "" IPC

BO_ 1106 CGM_CAN5_PDU68: 6 CGM
 SG_ MCMTR_Mins : 3|7@0+ (1,0) [0|127] "minutes" CSM
 SG_ StBltShfIntlkCstAvlFlg7 : 4|1@0+ (1,0) [0|1] "" CSM,RadioLow
 SG_ StBltShfIntlkCstAvlFlg6 : 5|1@0+ (1,0) [0|1] "" CSM,RadioLow
 SG_ StBltShfIntlkCstAvlFlg5 : 6|1@0+ (1,0) [0|1] "" CSM,RadioLow
 SG_ StBltShfIntlkCstAvlFlg4 : 7|1@0+ (1,0) [0|1] "" CSM,RadioLow
 SG_ MCMTR_Secs : 12|6@0+ (1,0) [0|63] "seconds" CSM
 SG_ ElecMtrARotrTemp : 21|8@0+ (1,-40) [-40|215] "deg C" IPC
 SG_ ElecMtrARotrTemp_Inv : 22|1@0+ (1,0) [0|1] "" IPC
 SG_ ElecMtrASttrTemp : 28|8@0+ (1,-40) [-40|215] "deg C" IPC
 SG_ ElecMtrASttrTemp_Inv : 29|1@0+ (1,0) [0|1] "" IPC
 SG_ RideHghtSpdRstrctnDispVal : 36|8@0+ (1,0) [0|255] "km/h" IPC
 SG_ LvlgSysAlgnMdCstAvlFlg5 : 40|1@0+ (1,0) [0|1] "" CSM,RadioLow
 SG_ LvlgSysAlgnMdCstAvlFlg4 : 41|1@0+ (1,0) [0|1] "" CSM,RadioLow
 SG_ LvlgSysAlgnMdCstAvlFlg3 : 42|1@0+ (1,0) [0|1] "" CSM,RadioLow
 SG_ LvlgSysAlgnMdCstAvlFlg2 : 43|1@0+ (1,0) [0|1] "" CSM,RadioLow
 SG_ LvlgSysAlgnMdCstAvlFlg1 : 44|1@0+ (1,0) [0|1] "" CSM,RadioLow

BO_ 1386 CGM_CAN5_PDU70: 8 CGM
 SG_ SecAxlTransStatAchvd_Inv : 0|1@0+ (1,0) [0|1] "" AMP
 SG_ NtVsnVidCntrstSts : 3|3@0+ (1,0) [0|7] "" IPC
 SG_ NtVsnFncSts : 5|2@0+ (1,0) [0|3] "" IPC
 SG_ HzrdReqActv : 6|1@0+ (1,0) [0|1] "" TCP
 SG_ AllWhlDrvRcmndIndOn : 7|1@0+ (1,0) [0|1] "" IPC
 SG_ ElecShfLckdBcklPsngrStBltIndOn : 8|1@0+ (1,0) [0|1] "" IPC
 SG_ ElecShfLckdBcklDrvrStBltIndOn : 9|1@0+ (1,0) [0|1] "" IPC
 SG_ TrlrBrkgSysProfSts : 12|3@0+ (1,0) [0|5] "" CSM
 SG_ TrlrBrkCnctdIndOn : 13|1@0+ (1,0) [0|1] "" IPC
 SG_ SecAxlTransStatAchvd : 15|2@0+ (1,0) [0|2] "" AMP
 SG_ RmtPRNDLDispFltIndOn : 16|1@0+ (1,0) [0|1] "" IPC
 SG_ NoKeyFndTryAgnIndOn : 17|1@0+ (1,0) [0|1] "" IPC
 SG_ NoKeyDtdElecShfDndIndOn : 18|1@0+ (1,0) [0|1] "" IPC
 SG_ KeyMisgCkForKeyIndOn : 19|1@0+ (1,0) [0|1] "" IPC
 SG_ PrtctdIdlUnvIndOn : 20|1@0+ (1,0) [0|1] "" IPC
 SG_ PrtctdIdlIndOn : 21|1@0+ (1,0) [0|1] "" IPC
 SG_ NoKeyDtdMechShfDndIndOn : 22|1@0+ (1,0) [0|1] "" IPC
 SG_ ElecShfUnlckdBrkToShfIndOn : 23|1@0+ (1,0) [0|1] "" IPC
 SG_ KMORAI_AllwdTm : 30|8@0+ (1,0) [0|255] "Min" IPC
 SG_ SpdLmtrSpdLimSgnUnt : 31|1@0+ (1,0) [0|1] "" IPC
 SG_ InstDrvEff : 37|8@0- (0.78125,0) [-100|99.2188] "%" CSM,IPC
 SG_ KMORAI_IndOn : 38|1@0+ (1,0) [0|1] "" IPC
 SG_ EngRcmndDwnsftIndOn : 40|1@0+ (1,0) [0|1] "" IPC
 SG_ ElecShfVehInPrkNeutGrMisusdIO : 41|1@0+ (1,0) [0|1] "" IPC
 SG_ ElecShfShfgToPrkNeutGrMisusdIO : 42|1@0+ (1,0) [0|1] "" IPC
 SG_ ElecShfSelNeutAgnForCarWshMdIO : 43|1@0+ (1,0) [0|1] "" IPC
 SG_ ElecShfPrssNeutAgnForNeutIndOn : 44|1@0+ (1,0) [0|1] "" IPC
 SG_ ElecShfCarWshModeOnDoNTowIndOn : 45|1@0+ (1,0) [0|1] "" IPC
 SG_ SGI2P_AirSpnsnRdHghtActlStsAuth : 49|4@0+ (1,0) [0|9] "" CSM
 SG_ ESCSpdLtdCntdwnVal : 55|6@0+ (1,0) [0|63] "Trips" IPC
 SG_ InvsblTrlrAux2CamConctSts : 57|2@0+ (1,0) [0|2] "" CSM
 SG_ InvsblTrlrAux1CamConctSts : 59|2@0+ (1,0) [0|2] "" CGM,CSM
 SG_ ESCSpdLtdIndReq : 61|2@0+ (1,0) [0|2] "" IPC

BO_ 1387 CGM_CAN5_PDU71: 6 CGM
 SG_ RideHghtSeltn7Name : 1|3@0+ (1,0) [0|7] "" IPC
 SG_ RideHghtSeltn6Name : 4|3@0+ (1,0) [0|7] "" IPC
 SG_ RideHghtSeltn5Name : 7|3@0+ (1,0) [0|7] "" IPC
 SG_ LvlgSysServMdCstSetSelable : 8|1@0+ (1,0) [0|1] "" CSM,RadioLow
 SG_ LvlgSysServMdCstSetAval : 9|1@0+ (1,0) [0|1] "" CSM,RadioLow
 SG_ LvlgSysEntEgrsMdCstSetAval : 10|1@0+ (1,0) [0|1] "" CSM,RadioLow
 SG_ LvlgSysAlgnMdCstSetSelable : 11|1@0+ (1,0) [0|1] "" CSM,RadioLow
 SG_ RideHghtSeltn8Name : 14|3@0+ (1,0) [0|7] "" IPC
 SG_ RideHghtSeltn4Unv : 16|1@0+ (1,0) [0|1] "" IPC
 SG_ RideHghtSeltn4Pndg : 17|1@0+ (1,0) [0|1] "" IPC
 SG_ RideHghtSeltn3Unv : 18|1@0+ (1,0) [0|1] "" IPC
 SG_ RideHghtSeltn3Pndg : 19|1@0+ (1,0) [0|1] "" IPC
 SG_ RideHghtSeltn2Unv : 20|1@0+ (1,0) [0|1] "" IPC
 SG_ RideHghtSeltn2Pndg : 21|1@0+ (1,0) [0|1] "" IPC
 SG_ RideHghtSeltn1Unv : 22|1@0+ (1,0) [0|1] "" IPC
 SG_ RideHghtSeltn1Pndg : 23|1@0+ (1,0) [0|1] "" IPC
 SG_ RideHghtSeltn8Unv : 24|1@0+ (1,0) [0|1] "" IPC
 SG_ RideHghtSeltn8Pndg : 25|1@0+ (1,0) [0|1] "" IPC
 SG_ RideHghtSeltn7Unv : 26|1@0+ (1,0) [0|1] "" IPC
 SG_ RideHghtSeltn7Pndg : 27|1@0+ (1,0) [0|1] "" IPC
 SG_ RideHghtSeltn6Unv : 28|1@0+ (1,0) [0|1] "" IPC
 SG_ RideHghtSeltn6Pndg : 29|1@0+ (1,0) [0|1] "" IPC
 SG_ RideHghtSeltn5Unv : 30|1@0+ (1,0) [0|1] "" IPC
 SG_ RideHghtSeltn5Pndg : 31|1@0+ (1,0) [0|1] "" IPC
 SG_ IHVSLR_HtdCushBckLvl2 : 32|1@0+ (1,0) [0|1] "" HVAC_FP_R
 SG_ IHVSLR_HtdCushBckLvl1 : 33|1@0+ (1,0) [0|1] "" HVAC_FP_R
 SG_ IHVSLR_HtdCushBckAuto : 34|1@0+ (1,0) [0|1] "" HVAC_FP_R
 SG_ IHVSLR_HtdBckMd : 35|1@0+ (1,0) [0|1] "" HVAC_FP_R
 SG_ IHVSLR_HtdBckLvl3 : 36|1@0+ (1,0) [0|1] "" HVAC_FP_R
 SG_ IHVSLR_HtdBckLvl2 : 37|1@0+ (1,0) [0|1] "" HVAC_FP_R
 SG_ IHVSLR_HtdBckLvl1 : 38|1@0+ (1,0) [0|1] "" HVAC_FP_R
 SG_ IHVSLR_HtdBckAuto : 39|1@0+ (1,0) [0|1] "" HVAC_FP_R
 SG_ DispSmrtTowVidOn : 40|1@0+ (1,0) [0|1] "" CSM
 SG_ IHVSLR_VntMd : 41|1@0+ (1,0) [0|1] "" HVAC_FP_R
 SG_ IHVSLR_VntLvl3 : 42|1@0+ (1,0) [0|1] "" HVAC_FP_R
 SG_ IHVSLR_VntLvl2 : 43|1@0+ (1,0) [0|1] "" HVAC_FP_R
 SG_ IHVSLR_VntLvl1 : 44|1@0+ (1,0) [0|1] "" HVAC_FP_R
 SG_ IHVSLR_VntAuto : 45|1@0+ (1,0) [0|1] "" HVAC_FP_R
 SG_ IHVSLR_HtdCushBckMd : 46|1@0+ (1,0) [0|1] "" HVAC_FP_R
 SG_ IHVSLR_HtdCushBckLvl3 : 47|1@0+ (1,0) [0|1] "" HVAC_FP_R

BO_ 1401 CGM_CAN5_PDU73: 6 CGM
 SG_ LvlgSysEntEgrsMdCstAvlFlg6 : 0|1@0+ (1,0) [0|1] "" CSM,RadioLow
 SG_ LvlgSysEntEgrsMdCstAvlFlg5 : 1|1@0+ (1,0) [0|1] "" CSM,RadioLow
 SG_ LvlgSysEntEgrsMdCstAvlFlg4 : 2|1@0+ (1,0) [0|1] "" CSM,RadioLow
 SG_ LvlgSysEntEgrsMdCstAvlFlg3 : 3|1@0+ (1,0) [0|1] "" CSM,RadioLow
 SG_ LvlgSysEntEgrsMdCstAvlFlg2 : 4|1@0+ (1,0) [0|1] "" CSM,RadioLow
 SG_ LvlgSysEntEgrsMdCstAvlFlg1 : 5|1@0+ (1,0) [0|1] "" CSM,RadioLow
 SG_ LvlgSysAlgnMdCstAvlFlg7 : 6|1@0+ (1,0) [0|1] "" CSM,RadioLow
 SG_ LvlgSysAlgnMdCstAvlFlg6 : 7|1@0+ (1,0) [0|1] "" CSM,RadioLow
 SG_ LvlgSysServMdCstAvlFlg7 : 8|1@0+ (1,0) [0|1] "" CSM,RadioLow
 SG_ LvlgSysServMdCstAvlFlg6 : 9|1@0+ (1,0) [0|1] "" CSM,RadioLow
 SG_ LvlgSysServMdCstAvlFlg5 : 10|1@0+ (1,0) [0|1] "" CSM,RadioLow
 SG_ LvlgSysServMdCstAvlFlg4 : 11|1@0+ (1,0) [0|1] "" CSM,RadioLow
 SG_ LvlgSysServMdCstAvlFlg3 : 12|1@0+ (1,0) [0|1] "" CSM,RadioLow
 SG_ LvlgSysServMdCstAvlFlg2 : 13|1@0+ (1,0) [0|1] "" CSM,RadioLow
 SG_ LvlgSysServMdCstAvlFlg1 : 14|1@0+ (1,0) [0|1] "" CSM,RadioLow
 SG_ LvlgSysEntEgrsMdCstAvlFlg7 : 15|1@0+ (1,0) [0|1] "" CSM,RadioLow
 SG_ BattCrntFltrd : 23|22@0- (0.001,0) [-2097.15|2097.15] "Amps" CSM,TCP
 SG_ VehMassEstSts : 33|2@0+ (1,0) [0|2] "" CSM
 SG_ TmngBltChgIndOn : 45|1@0+ (1,0) [0|1] "" IPC
 SG_ FuelConsmpHvyIndReq : 47|2@0+ (1,0) [0|2] "" IPC

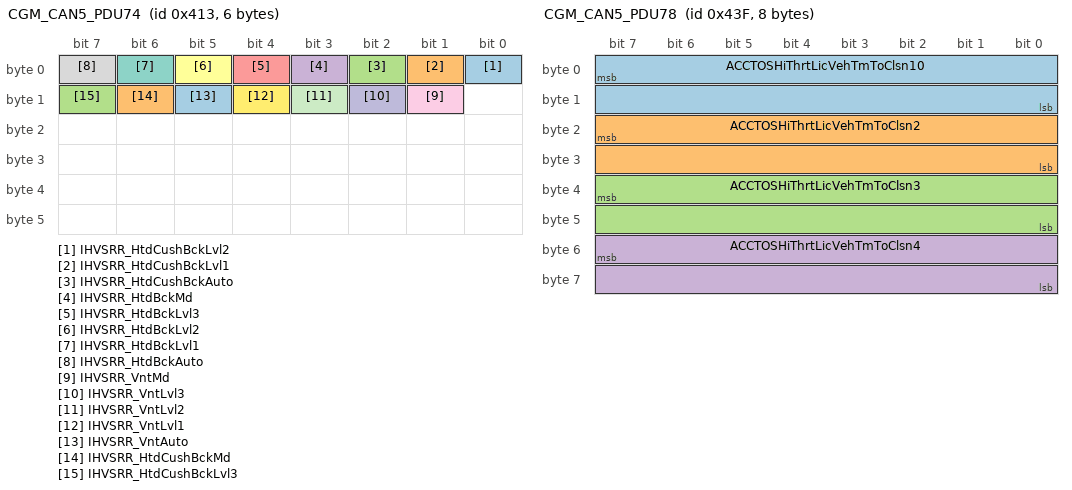
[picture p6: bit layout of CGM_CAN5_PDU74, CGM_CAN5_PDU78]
BO_ 1043 CGM_CAN5_PDU74: 6 CGM
 SG_ IHVSRR_HtdCushBckLvl2 : 0|1@0+ (1,0) [0|1] "" HVAC_FP_R
 SG_ IHVSRR_HtdCushBckLvl1 : 1|1@0+ (1,0) [0|1] "" HVAC_FP_R
 SG_ IHVSRR_HtdCushBckAuto : 2|1@0+ (1,0) [0|1] "" HVAC_FP_R
 SG_ IHVSRR_HtdBckMd : 3|1@0+ (1,0) [0|1] "" HVAC_FP_R
 SG_ IHVSRR_HtdBckLvl3 : 4|1@0+ (1,0) [0|1] "" HVAC_FP_R
 SG_ IHVSRR_HtdBckLvl2 : 5|1@0+ (1,0) [0|1] "" HVAC_FP_R
 SG_ IHVSRR_HtdBckLvl1 : 6|1@0+ (1,0) [0|1] "" HVAC_FP_R
 SG_ IHVSRR_HtdBckAuto : 7|1@0+ (1,0) [0|1] "" HVAC_FP_R
 SG_ IHVSRR_VntMd : 9|1@0+ (1,0) [0|1] "" HVAC_FP_R
 SG_ IHVSRR_VntLvl3 : 10|1@0+ (1,0) [0|1] "" HVAC_FP_R
 SG_ IHVSRR_VntLvl2 : 11|1@0+ (1,0) [0|1] "" HVAC_FP_R
 SG_ IHVSRR_VntLvl1 : 12|1@0+ (1,0) [0|1] "" HVAC_FP_R
 SG_ IHVSRR_VntAuto : 13|1@0+ (1,0) [0|1] "" HVAC_FP_R
 SG_ IHVSRR_HtdCushBckMd : 14|1@0+ (1,0) [0|1] "" HVAC_FP_R
 SG_ IHVSRR_HtdCushBckLvl3 : 15|1@0+ (1,0) [0|1] "" HVAC_FP_R

BO_ 1125 CGM_CAN5_PDU75: 6 CGM
 SG_ VehMassEst : 7|15@0+ (1,0) [0|32767] "kg" CSM

BO_ 1414 CGM_CAN5_PDU76: 6 CGM
 SG_ MemStorCmpltdIndReq : 2|3@0+ (1,0) [0|4] "" IPC
 SG_ MemRclHldUntilCmpltIndReq : 5|3@0+ (1,0) [0|4] "" IPC
 SG_ TrlrArtclnAngCalSts : 7|2@0+ (1,0) [0|3] "" CSM
 SG_ PrkAsstActIndCmnd : 8|1@0+ (1,0) [0|1] "" CSM
 SG_ InrTlgtOpnIndOn : 9|1@0+ (1,0) [0|1] "" IPC
 SG_ PPVehRadioMutReq : 11|2@0+ (1,0) [0|2] "" CSM,RadioLow
 SG_ RrStrgFlrIndOn : 12|1@0+ (1,0) [0|1] "" IPC
 SG_ MemStorTmdOutIndOn : 13|1@0+ (1,0) [0|1] "" IPC
 SG_ MemStorPrssSetFrstIndOn : 14|1@0+ (1,0) [0|1] "" IPC
 SG_ MemSeeAutoRclSetsIndOn : 15|1@0+ (1,0) [0|1] "" IPC
 SG_ OffRdMdDrvlnVisDispVal : 17|3@0+ (1,0) [0|7] "" CSM,RadioLow
 SG_ OffRdMdBrkPedVisDispVal : 20|3@0+ (1,0) [0|7] "" CSM,RadioLow
 SG_ OffRdMdActvAerodynsVisDispVal : 23|3@0+ (1,0) [0|7] "" CSM,RadioLow
 SG_ OffRdMdSpnsnVisDispVal : 24|3@0+ (1,0) [0|7] "" CSM,RadioLow
 SG_ OffRdMdPwrtrnVisDispVal : 27|3@0+ (1,0) [0|7] "" CSM,RadioLow
 SG_ OffRdMdESCVisDispVal : 30|3@0+ (1,0) [0|7] "" CSM,RadioLow
 SG_ OffRdMdRideHghtVisDispVal : 34|3@0+ (1,0) [0|7] "" CSM,RadioLow
 SG_ OffRdMdStrgVisDispVal : 37|3@0+ (1,0) [0|7] "" CSM,RadioLow
 SG_ PTOEngRunTmrCstAvlFlg11 : 40|1@0+ (1,0) [0|1] "" CSM,RadioLow
 SG_ PTOEngRunTmrCstAvlFlg10 : 41|1@0+ (1,0) [0|1] "" CSM,RadioLow
 SG_ BrkSysTwoFtdDrvDtdIndOn : 42|1@0+ (1,0) [0|1] "" IPC
 SG_ RrCrsTrfcAutoBrkgOffIndOn : 43|1@0+ (1,0) [0|1] "" IPC
 SG_ ACCTrlrGapSetIndOn : 44|1@0+ (1,0) [0|1] "" IPC
 SG_ OffRdMdSndVisDispVal : 47|3@0+ (1,0) [0|7] "" CSM,RadioLow

BO_ 1061 CGM_CAN5_PDU77: 6 CGM
 SG_ TowHaulMdPwrtrnVisDispVal : 1|3@0+ (1,0) [0|7] "" CSM,RadioLow
 SG_ TowHaulMdESCVisDispVal : 4|3@0+ (1,0) [0|7] "" CSM,RadioLow
 SG_ TowHaulMdBrkPedVisDispVal : 7|3@0+ (1,0) [0|7] "" CSM,RadioLow
 SG_ TowHaulMdActvAerodynsVisDispVal : 8|3@0+ (1,0) [0|7] "" CSM,RadioLow
 SG_ TowHaulMdStrgVisDispVal : 11|3@0+ (1,0) [0|7] "" CSM,RadioLow
 SG_ TowHaulMdSpnsnVisDispVal : 14|3@0+ (1,0) [0|7] "" CSM,RadioLow
 SG_ TowHaulMdSndVisDispVal : 18|3@0+ (1,0) [0|7] "" CSM,RadioLow
 SG_ TowHaulMdDrvlnVisDispVal : 21|3@0+ (1,0) [0|7] "" CSM,RadioLow
 SG_ RrAxlLckIO : 24|1@0+ (1,0) [0|1] "" IPC
 SG_ FrntAxlLckIO : 25|1@0+ (1,0) [0|1] "" IPC
 SG_ AxlLckUnavailIndReq : 28|3@0+ (1,0) [0|5] "" IPC
 SG_ TowHaulMdRideHghtVisDispVal : 31|3@0+ (1,0) [0|7] "" CSM,RadioLow
 SG_ TirePrsLRInr : 38|8@0+ (4,0) [0|1020] "kPaG" CSM,IPC,TCP
 SG_ TirePrsLRInr_Inv : 39|1@0+ (1,0) [0|1] "" CSM,IPC,TCP
 SG_ AutoTrnspHdActvnCstAvlFlg1 : 40|1@0+ (1,0) [0|1] "" CSM
 SG_ TirePrsStatLRInr : 43|3@0+ (1,0) [0|5] "" CSM,IPC,TCP
 SG_ AutoTrnspHdActvnCstCurrSetVal : 46|3@0+ (1,0) [0|2] "" CSM

BO_ 1087 CGM_CAN5_PDU78: 8 CGM
 SG_ ACCTOSHiThrtLicVehTmToClsn10 : 7|16@0+ (0.001,0) [0|65.535] "s" TCP
 SG_ ACCTOSHiThrtLicVehTmToClsn2 : 23|16@0+ (0.001,0) [0|65.535] "s" TCP
 SG_ ACCTOSHiThrtLicVehTmToClsn3 : 39|16@0+ (0.001,0) [0|65.535] "s" TCP
 SG_ ACCTOSHiThrtLicVehTmToClsn4 : 55|16@0+ (0.001,0) [0|65.535] "s" TCP

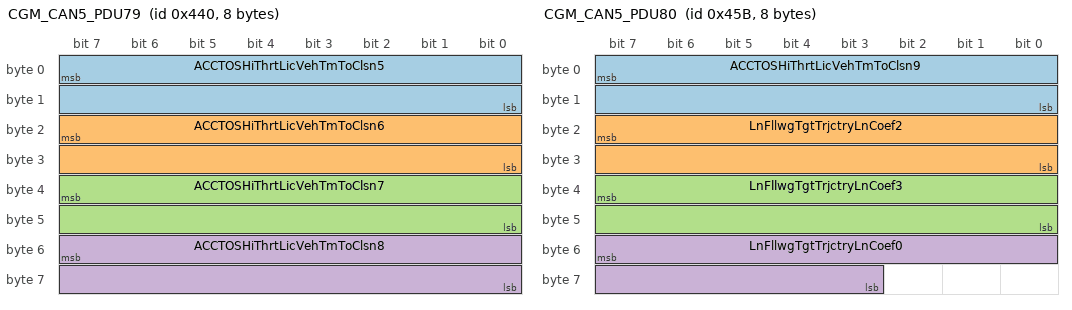
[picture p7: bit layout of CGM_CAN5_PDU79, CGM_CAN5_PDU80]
BO_ 1088 CGM_CAN5_PDU79: 8 CGM
 SG_ ACCTOSHiThrtLicVehTmToClsn5 : 7|16@0+ (0.001,0) [0|65.535] "s" TCP
 SG_ ACCTOSHiThrtLicVehTmToClsn6 : 23|16@0+ (0.001,0) [0|65.535] "s" TCP
 SG_ ACCTOSHiThrtLicVehTmToClsn7 : 39|16@0+ (0.001,0) [0|65.535] "s" TCP
 SG_ ACCTOSHiThrtLicVehTmToClsn8 : 55|16@0+ (0.001,0) [0|65.535] "s" TCP

BO_ 1115 CGM_CAN5_PDU80: 8 CGM
 SG_ ACCTOSHiThrtLicVehTmToClsn9 : 7|16@0+ (0.001,0) [0|65.535] "s" TCP
 SG_ LnFllwgTgtTrjctryLnCoef2 : 23|16@0- (9.77e-07,0) [-0.0320143|0.0320134] "1/m" TCP
 SG_ LnFllwgTgtTrjctryLnCoef3 : 39|16@0- (3.73e-09,0) [-0.000122225|0.000122221] "1/m^2" TCP
 SG_ LnFllwgTgtTrjctryLnCoef0 : 55|13@0- (0.00309,0) [-12.6566|12.6535] "m" TCP

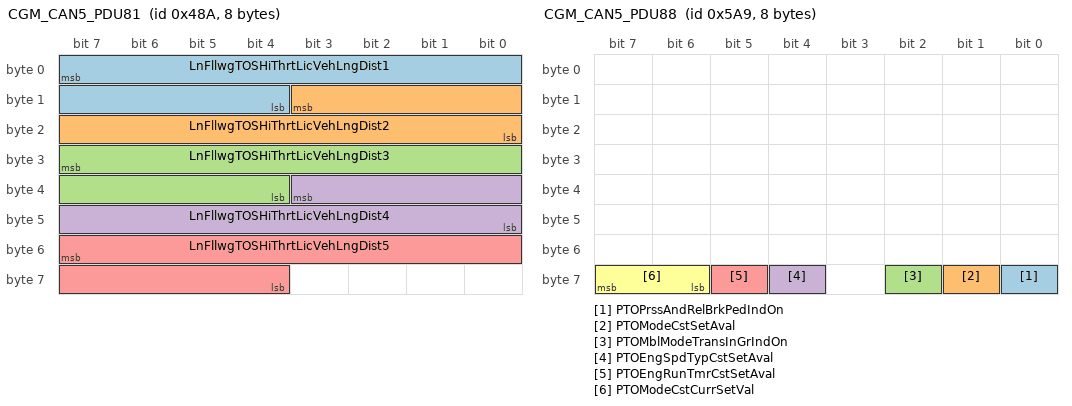
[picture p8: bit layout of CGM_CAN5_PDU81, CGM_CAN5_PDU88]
BO_ 1162 CGM_CAN5_PDU81: 8 CGM
 SG_ LnFllwgTOSHiThrtLicVehLngDist1 : 7|12@0- (0.125,0) [-256|255.875] "m" TCP
 SG_ LnFllwgTOSHiThrtLicVehLngDist2 : 11|12@0- (0.125,0) [-256|255.875] "m" TCP
 SG_ LnFllwgTOSHiThrtLicVehLngDist3 : 31|12@0- (0.125,0) [-256|255.875] "m" TCP
 SG_ LnFllwgTOSHiThrtLicVehLngDist4 : 35|12@0- (0.125,0) [-256|255.875] "m" TCP
 SG_ LnFllwgTOSHiThrtLicVehLngDist5 : 55|12@0- (0.125,0) [-256|255.875] "m" TCP

BO_ 1417 CGM_CAN5_PDU82: 6 CGM
 SG_ LnFllwgTOSHiThrtLicVehLngDist6 : 7|12@0- (0.125,0) [-256|255.875] "m" TCP

BO_ 1426 CGM_CAN5_PDU83: 6 CGM
 SG_ TirePrsRRInr : 6|8@0+ (4,0) [0|1020] "kPaG" CSM,IPC,TCP
 SG_ TirePrsRRInr_Inv : 7|1@0+ (1,0) [0|1] "" CSM,IPC,TCP
 SG_ AutoTrnspHdActvnCstAvlFlg5 : 8|1@0+ (1,0) [0|1] "" CSM
 SG_ AutoTrnspHdActvnCstAvlFlg4 : 9|1@0+ (1,0) [0|1] "" CSM
 SG_ AutoTrnspHdActvnCstAvlFlg3 : 10|1@0+ (1,0) [0|1] "" CSM
 SG_ AutoTrnspHdActvnCstAvlFlg2 : 11|1@0+ (1,0) [0|1] "" CSM
 SG_ TirePrsStatRRInr : 14|3@0+ (1,0) [0|5] "" CSM,IPC,TCP
 SG_ PTOEngRunTmrCstAvlFlg6 : 16|1@0+ (1,0) [0|1] "" CSM,RadioLow
 SG_ PTOEngRunTmrCstAvlFlg5 : 17|1@0+ (1,0) [0|1] "" CSM,RadioLow
 SG_ PTOEngRunTmrCstAvlFlg4 : 18|1@0+ (1,0) [0|1] "" CSM,RadioLow
 SG_ PTOEngRunTmrCstAvlFlg3 : 19|1@0+ (1,0) [0|1] "" CSM,RadioLow
 SG_ AxlLcksServIO : 20|1@0+ (1,0) [0|1] "" IPC
 SG_ AutoTrnspHdActvnCstSetAval : 21|1@0+ (1,0) [0|1] "" CSM
 SG_ AutoTrnspHdActvnCstAvlFlg7 : 22|1@0+ (1,0) [0|1] "" CSM
 SG_ AutoTrnspHdActvnCstAvlFlg6 : 23|1@0+ (1,0) [0|1] "" CSM
 SG_ PTOSet1SpdCstAvlFlg1 : 24|1@0+ (1,0) [0|1] "" CSM,RadioLow
 SG_ PTOModeCstAvlFlg2 : 25|1@0+ (1,0) [0|1] "" CSM,RadioLow
 SG_ PTOModeCstAvlFlg1 : 26|1@0+ (1,0) [0|1] "" CSM,RadioLow
 SG_ PTOEngSpdTypCstAvlFlg2 : 27|1@0+ (1,0) [0|1] "" CSM,RadioLow
 SG_ PTOEngSpdTypCstAvlFlg1 : 28|1@0+ (1,0) [0|1] "" CSM,RadioLow
 SG_ PTOEngRunTmrCstAvlFlg9 : 29|1@0+ (1,0) [0|1] "" CSM,RadioLow
 SG_ PTOEngRunTmrCstAvlFlg8 : 30|1@0+ (1,0) [0|1] "" CSM,RadioLow
 SG_ PTOEngRunTmrCstAvlFlg7 : 31|1@0+ (1,0) [0|1] "" CSM,RadioLow
 SG_ PTOSet1SpdCstAvlFlg3 : 32|1@0+ (1,0) [0|1] "" CSM,RadioLow
 SG_ PTOSet1SpdCstAvlFlg2 : 33|1@0+ (1,0) [0|1] "" CSM,RadioLow
 SG_ PTOSet1SpdCstAvlFlg15 : 34|1@0+ (1,0) [0|1] "" CSM,RadioLow
 SG_ PTOSet1SpdCstAvlFlg14 : 35|1@0+ (1,0) [0|1] "" CSM,RadioLow
 SG_ PTOSet1SpdCstAvlFlg13 : 36|1@0+ (1,0) [0|1] "" CSM,RadioLow
 SG_ PTOSet1SpdCstAvlFlg12 : 37|1@0+ (1,0) [0|1] "" CSM,RadioLow
 SG_ PTOSet1SpdCstAvlFlg11 : 38|1@0+ (1,0) [0|1] "" CSM,RadioLow
 SG_ PTOSet1SpdCstAvlFlg10 : 39|1@0+ (1,0) [0|1] "" CSM,RadioLow
 SG_ PTOSet2SpdCstAvlFlg10 : 40|1@0+ (1,0) [0|1] "" CSM,RadioLow
 SG_ PTOSet2SpdCstAvlFlg1 : 41|1@0+ (1,0) [0|1] "" CSM,RadioLow
 SG_ PTOSet1SpdCstAvlFlg9 : 42|1@0+ (1,0) [0|1] "" CSM,RadioLow
 SG_ PTOSet1SpdCstAvlFlg8 : 43|1@0+ (1,0) [0|1] "" CSM,RadioLow
 SG_ PTOSet1SpdCstAvlFlg7 : 44|1@0+ (1,0) [0|1] "" CSM,RadioLow
 SG_ PTOSet1SpdCstAvlFlg6 : 45|1@0+ (1,0) [0|1] "" CSM,RadioLow
 SG_ PTOSet1SpdCstAvlFlg5 : 46|1@0+ (1,0) [0|1] "" CSM,RadioLow
 SG_ PTOSet1SpdCstAvlFlg4 : 47|1@0+ (1,0) [0|1] "" CSM,RadioLow

BO_ 1449 CGM_CAN5_PDU88: 8 CGM
 SG_ PTOPrssAndRelBrkPedIndOn : 56|1@0+ (1,0) [0|1] "" IPC
 SG_ PTOModeCstSetAval : 57|1@0+ (1,0) [0|1] "" CSM,RadioLow
 SG_ PTOMblModeTransInGrIndOn : 58|1@0+ (1,0) [0|1] "" IPC
 SG_ PTOEngSpdTypCstSetAval : 60|1@0+ (1,0) [0|1] "" CSM,RadioLow
 SG_ PTOEngRunTmrCstSetAval : 61|1@0+ (1,0) [0|1] "" CSM,RadioLow
 SG_ PTOModeCstCurrSetVal : 63|2@0+ (1,0) [0|2] "" CSM,RadioLow

BO_ 1466 CGM_CAN5_PDU94: 8 CGM
 SG_ PTOSet2SpdCstCurrSetVal : 59|4@0+ (1,0) [0|15] "" CSM,RadioLow
 SG_ PTOSet1SpdCstCurrSetVal : 63|4@0+ (1,0) [0|15] "" CSM,RadioLow

BA_DEF_ SG_  "SignalType" STRING ;
BA_DEF_ SG_  "SignalLongName" STRING ;
BA_DEF_ BO_  "GenMsgCycleTime" INT 0 10000;
BA_DEF_ BO_  "GenMsgSendType" ENUM "cyclicX","spontanX","cyclicIfActiveX","spontanWithDelay","cyclicAndSpontanX","cyclicAndSpontanWithDelay","spontanWithRepetition","cyclicIfActiveAndSpontanWD";
BA_DEF_DEF_  "SignalType" "";
BA_DEF_DEF_  "SignalLongName" "";
BA_DEF_DEF_  "GenMsgCycleTime" 0;
BA_DEF_DEF_  "GenMsgSendType" "cyclicX";
BA_ "GenMsgCycleTime" BO_ 1242 1000;
BA_ "GenMsgCycleTime" BO_ 1243 1000;
BA_ "GenMsgCycleTime" BO_ 1244 1000;
BA_ "GenMsgCycleTime" BO_ 1245 1000;
BA_ "GenMsgCycleTime" BO_ 1246 1000;
BA_ "GenMsgCycleTime" BO_ 1247 1000;
BA_ "GenMsgCycleTime" BO_ 1248 1000;
BA_ "GenMsgCycleTime" BO_ 1249 1000;
BA_ "GenMsgCycleTime" BO_ 1250 1000;
BA_ "GenMsgCycleTime" BO_ 44 20;
BA_ "GenMsgCycleTime" BO_ 611 250;
BA_ "GenMsgCycleTime" BO_ 612 250;
BA_ "GenMsgCycleTime" BO_ 181 50;
BA_ "GenMsgCycleTime" BO_ 1251 500;
BA_ "GenMsgCycleTime" BO_ 40 10;
BA_ "GenMsgCycleTime" BO_ 43 10;
BA_ "GenMsgCycleTime" BO_ 1172 1000;
BA_ "GenMsgCycleTime" BO_ 1253 1000;
BA_ "GenMsgCycleTime" BO_ 1066 1000;
BA_ "GenMsgCycleTime" BO_ 1107 1000;
BA_ "GenMsgCycleTime" BO_ 521 250;
BA_ "GenMsgCycleTime" BO_ 606 100;
BA_ "GenMsgCycleTime" BO_ 1300 1000;
BA_ "GenMsgCycleTime" BO_ 1301 1000;
BA_ "GenMsgCycleTime" BO_ 140 30;
BA_ "GenMsgCycleTime" BO_ 1289 1000;
BA_ "GenMsgCycleTime" BO_ 1298 1000;
BA_ "GenMsgCycleTime" BO_ 1106 1000;
BA_ "GenMsgCycleTime" BO_ 1386 1000;
BA_ "GenMsgCycleTime" BO_ 1387 1000;
BA_ "GenMsgCycleTime" BO_ 1401 1000;
BA_ "GenMsgCycleTime" BO_ 1043 1000;
BA_ "GenMsgCycleTime" BO_ 1125 1000;
BA_ "GenMsgCycleTime" BO_ 1414 1000;
BA_ "GenMsgCycleTime" BO_ 1061 1000;
BA_ "GenMsgCycleTime" BO_ 1087 500;
BA_ "GenMsgCycleTime" BO_ 1088 500;
BA_ "GenMsgCycleTime" BO_ 1115 500;
BA_ "GenMsgCycleTime" BO_ 1162 500;
BA_ "GenMsgCycleTime" BO_ 1417 500;
BA_ "GenMsgCycleTime" BO_ 1426 1000;
BA_ "GenMsgCycleTime" BO_ 1449 1000;
BA_ "GenMsgCycleTime" BO_ 1466 1000;
BA_ "SignalType" SG_ 1242 RRSCDS_Massg "ENM";
BA_ "SignalLongName" SG_ 1242 RRSCDS_Massg "Right Rear Seat Control Display Status : Massage";
BA_ "SignalType" SG_ 1242 RRSCDS_LmbrUDnFdRr "ENM";
BA_ "SignalLongName" SG_ 1242 RRSCDS_LmbrUDnFdRr "Right Rear Seat Control Display Status : Lumbar Up/Down and Forward/Rearward";
BA_ "SignalType" SG_ 1242 RRSCDS_MassgTyp "ENM";
BA_ "SignalLongName" SG_ 1242 RRSCDS_MassgTyp "Right Rear Seat Control Display Status : Massage Type";
BA_ "SignalType" SG_ 1242 RRSCDS_BkCshBlstInOt "ENM";
BA_ "SignalLongName" SG_ 1242 RRSCDS_BkCshBlstInOt "Right Rear Seat Control Display Status : Back and Cushion Bolster In/Out";
BA_ "SignalType" SG_ 1242 RRSCDS_HdrstFwdRrwd "ENM";
BA_ "SignalLongName" SG_ 1242 RRSCDS_HdrstFwdRrwd "Right Rear Seat Control Display Status : Headrest Forward/Rearward";
BA_ "SignalType" SG_ 1242 RRSCDS_LmbrFwdRr "ENM";
BA_ "SignalLongName" SG_ 1242 RRSCDS_LmbrFwdRr "Right Rear Seat Control Display Status : Lumbar Forward/Rearward";
BA_ "SignalType" SG_ 1242 RRSCDS_HdrstFdRrUDn "ENM";
BA_ "SignalLongName" SG_ 1242 RRSCDS_HdrstFdRrUDn "Right Rear Seat Control Display Status : Headrest Forward/Rearward and Up/Down";
BA_ "SignalType" SG_ 1242 RRSCDS_UprShldrFdRr "ENM";
BA_ "SignalLongName" SG_ 1242 RRSCDS_UprShldrFdRr "Right Rear Seat Control Display Status : Upper Shoulder Forward/Rearward";
BA_ "SignalType" SG_ 1242 RRSCDS_CshBlstrInOut "ENM";
BA_ "SignalLongName" SG_ 1242 RRSCDS_CshBlstrInOut "Right Rear Seat Control Display Status : Cushion Bolster In/Out";
BA_ "SignalType" SG_ 1242 RRSCDS_HdrstWngInOt "ENM";
BA_ "SignalLongName" SG_ 1242 RRSCDS_HdrstWngInOt "Right Rear Seat Control Display Status : Headrest Wings In/Out";
BA_ "SignalType" SG_ 1242 RRSCDS_HdrstUpDn "ENM";
BA_ "SignalLongName" SG_ 1242 RRSCDS_HdrstUpDn "Right Rear Seat Control Display Status : Headrest Up/Down";
BA_ "SignalType" SG_ 1242 RRSCDS_LmbrUpDwn "ENM";
BA_ "SignalLongName" SG_ 1242 RRSCDS_LmbrUpDwn "Right Rear Seat Control Display Status : Lumbar Up/Down";
BA_ "SignalType" SG_ 1242 RRSCDS_MassgIntsty "ENM";
BA_ "SignalLongName" SG_ 1242 RRSCDS_MassgIntsty "Right Rear Seat Control Display Status : Massage Intensity";
BA_ "SignalType" SG_ 1242 EDADS_ShftIndSt "ENM";
BA_ "SignalLongName" SG_ 1242 EDADS_ShftIndSt "ECO Drive Assist Display State : Shift Indication State";
BA_ "SignalType" SG_ 1242 RRSCDS_CshLgAdjFdRr "ENM";
BA_ "SignalLongName" SG_ 1242 RRSCDS_CshLgAdjFdRr "Right Rear Seat Control Display Status : Cushion Length Adjustment Forward/Rearward";
BA_ "SignalType" SG_ 1242 RRSCDS_HdrstTltFwdRr "ENM";
BA_ "SignalLongName" SG_ 1242 RRSCDS_HdrstTltFwdRr "Right Rear Seat Control Display Status : Headrest Tilt Forward/Rearward";
BA_ "SignalType" SG_ 1242 RRSCDS_BkBlstrInOut "ENM";
BA_ "SignalLongName" SG_ 1242 RRSCDS_BkBlstrInOut "Right Rear Seat Control Display Status : Back Bolster In/Out";
BA_ "SignalType" SG_ 1242 RRSCDS_DispReq "ENM";
BA_ "SignalLongName" SG_ 1242 RRSCDS_DispReq "Right Rear Seat Control Display Status : Display Request";
BA_ "SignalType" SG_ 1242 EDADS_RcmndtFwdGr "ENM";
BA_ "SignalLongName" SG_ 1242 EDADS_RcmndtFwdGr "ECO Drive Assist Display State : Recommended Forward Gear";
BA_ "SignalType" SG_ 1242 EDADS_CrntFwdMsdGr "ENM";
BA_ "SignalLongName" SG_ 1242 EDADS_CrntFwdMsdGr "ECO Drive Assist Display State : Current Forward Measured Gear";
BA_ "SignalType" SG_ 1242 CnvtblTpWndMtnReq "ENM";
BA_ "SignalLongName" SG_ 1242 CnvtblTpWndMtnReq "Convertible Top Window Motion Request";
BA_ "SignalType" SG_ 1242 CnvtblTpStat "ENM";
BA_ "SignalLongName" SG_ 1242 CnvtblTpStat "Convertible Top Status";
BA_ "SignalType" SG_ 1242 EDADS_EcoDrvShftIO "ENM";
BA_ "SignalLongName" SG_ 1242 EDADS_EcoDrvShftIO "ECO Drive Assist Display State : ECO Drive Assist Shift Indication On";
BA_ "SignalType" SG_ 1242 DrvDrAjrStat "ENM";
BA_ "SignalLongName" SG_ 1242 DrvDrAjrStat "Driver Door Ajar Status";
BA_ "SignalType" SG_ 1242 DrvDrAjrStat_Inv "ENM";
BA_ "SignalLongName" SG_ 1242 DrvDrAjrStat_Inv "Driver Door Ajar Status Invalid";
BA_ "SignalType" SG_ 1242 FCAACCGapSeltn "ENM";
BA_ "SignalLongName" SG_ 1242 FCAACCGapSeltn "Forward Collision Alert - Adaptive Cruise Control Gap Selection";
BA_ "SignalType" SG_ 1242 EsyExtCstCurSetVal "ENM";
BA_ "SignalLongName" SG_ 1242 EsyExtCstCurSetVal "EasyExitCustomizationCurrentSettingValue";
BA_ "SignalType" SG_ 1243 RFSCDS_LmbrUDnFdRr "ENM";
BA_ "SignalLongName" SG_ 1243 RFSCDS_LmbrUDnFdRr "Right Front Seat Control Display Status : Lumbar Up/Down and Forward/Rearward";
BA_ "SignalType" SG_ 1243 RFSCDS_UprShldrFdRr "ENM";
BA_ "SignalLongName" SG_ 1243 RFSCDS_UprShldrFdRr "Right Front Seat Control Display Status : Upper Shoulder Forward/Rearward";
BA_ "SignalType" SG_ 1243 RFSCDS_MassgTyp "ENM";
BA_ "SignalLongName" SG_ 1243 RFSCDS_MassgTyp "Right Front Seat Control Display Status : Massage Type";
BA_ "SignalType" SG_ 1243 RFSCDS_HdrstWngInOt "ENM";
BA_ "SignalLongName" SG_ 1243 RFSCDS_HdrstWngInOt "Right Front Seat Control Display Status : Headrest Wings In/Out";
BA_ "SignalType" SG_ 1243 RFSCDS_DispReq "ENM";
BA_ "SignalLongName" SG_ 1243 RFSCDS_DispReq "Right Front Seat Control Display Status : Display Request";
BA_ "SignalType" SG_ 1243 RFSCDS_BkBlstrInOut "ENM";
BA_ "SignalLongName" SG_ 1243 RFSCDS_BkBlstrInOut "Right Front Seat Control Display Status : Back Bolster In/Out";
BA_ "SignalType" SG_ 1243 RFSCDS_HdrstFwdRrwd "ENM";
BA_ "SignalLongName" SG_ 1243 RFSCDS_HdrstFwdRrwd "Right Front Seat Control Display Status : Headrest Forward/Rearward";
BA_ "SignalType" SG_ 1243 RFSCDS_LmbrFwdRr "ENM";
BA_ "SignalLongName" SG_ 1243 RFSCDS_LmbrFwdRr "Right Front Seat Control Display Status : Lumbar Forward/Rearward";
BA_ "SignalType" SG_ 1243 RFSCDS_HdrstTltFwdRr "ENM";
BA_ "SignalLongName" SG_ 1243 RFSCDS_HdrstTltFwdRr "Right Front Seat Control Display Status : Headrest Tilt Forward/Rearward";
BA_ "SignalType" SG_ 1243 RFSCDS_HdrstUpDn "ENM";
BA_ "SignalLongName" SG_ 1243 RFSCDS_HdrstUpDn "Right Front Seat Control Display Status : Headrest Up/Down";
BA_ "SignalType" SG_ 1243 RFSCDS_Massg "ENM";
BA_ "SignalLongName" SG_ 1243 RFSCDS_Massg "Right Front Seat Control Display Status : Massage";
BA_ "SignalType" SG_ 1243 RFSCDS_MassgIntsty "ENM";
BA_ "SignalLongName" SG_ 1243 RFSCDS_MassgIntsty "Right Front Seat Control Display Status : Massage Intensity";
BA_ "SignalType" SG_ 1243 RFSCDS_CshLgAdjFdRr "ENM";
BA_ "SignalLongName" SG_ 1243 RFSCDS_CshLgAdjFdRr "Right Front Seat Control Display Status : Cushion Length Adjustment Forward/Rearward";
BA_ "SignalType" SG_ 1243 RFSCDS_BkCshBlstInOt "ENM";
BA_ "SignalLongName" SG_ 1243 RFSCDS_BkCshBlstInOt "Right Front Seat Control Display Status : Back and Cushion Bolster In/Out";
BA_ "SignalType" SG_ 1243 RPARS_LtCntr "ENM";
BA_ "SignalLongName" SG_ 1243 RPARS_LtCntr "Rear Park Assist Region Status : Left Center Region";
BA_ "SignalType" SG_ 1243 RFSCDS_LmbrUpDwn "ENM";
BA_ "SignalLongName" SG_ 1243 RFSCDS_LmbrUpDwn "Right Front Seat Control Display Status : Lumbar Up/Down";
BA_ "SignalType" SG_ 1243 RFSCDS_HdrstFdRrUDn "ENM";
BA_ "SignalLongName" SG_ 1243 RFSCDS_HdrstFdRrUDn "Right Front Seat Control Display Status : Headrest Forward/Rearward and Up/Down";
BA_ "SignalType" SG_ 1243 RFSCDS_CshBlstrInOut "ENM";
BA_ "SignalLongName" SG_ 1243 RFSCDS_CshBlstrInOut "Right Front Seat Control Display Status : Cushion Bolster In/Out";
BA_ "SignalType" SG_ 1243 RPARS_RtCntr "ENM";
BA_ "SignalLongName" SG_ 1243 RPARS_RtCntr "Rear Park Assist Region Status : Right Center Region";
BA_ "SignalType" SG_ 1243 RPARS_Rt "ENM";
BA_ "SignalLongName" SG_ 1243 RPARS_Rt "Rear Park Assist Region Status : Right Region";
BA_ "SignalType" SG_ 1243 MemCmd "ENM";
BA_ "SignalLongName" SG_ 1243 MemCmd "Memory Command";
BA_ "SignalType" SG_ 1243 RPARS_Lt "ENM";
BA_ "SignalLongName" SG_ 1243 RPARS_Lt "Rear Park Assist Region Status : Left Region";
BA_ "SignalType" SG_ 1243 CoDrvDrAjrStat "ENM";
BA_ "SignalLongName" SG_ 1243 CoDrvDrAjrStat "Co-Driver Door Ajar Status";
BA_ "SignalType" SG_ 1243 CoDrvDrAjrStat_Inv "ENM";
BA_ "SignalLongName" SG_ 1243 CoDrvDrAjrStat_Inv "Co-Driver Door Ajar Status Invalid";
BA_ "SignalType" SG_ 1243 AutMemRclCstCurSetVal "ENM";
BA_ "SignalLongName" SG_ 1243 AutMemRclCstCurSetVal "AutoMemoryRecallCustomizationCurrentSettingValue";
BA_ "SignalType" SG_ 1244 LRSCDS_BkBlstrInOut "ENM";
BA_ "SignalLongName" SG_ 1244 LRSCDS_BkBlstrInOut "Left Rear Seat Control Display Status : Back Bolster In/Out";
BA_ "SignalType" SG_ 1244 LRSCDS_UprShldrFdRr "ENM";
BA_ "SignalLongName" SG_ 1244 LRSCDS_UprShldrFdRr "Left Rear Seat Control Display Status : Upper Shoulder Forward/Rearward";
BA_ "SignalType" SG_ 1244 LRSCDS_CshBlstrInOut "ENM";
BA_ "SignalLongName" SG_ 1244 LRSCDS_CshBlstrInOut "Left Rear Seat Control Display Status : Cushion Bolster In/Out";
BA_ "SignalType" SG_ 1244 LRSCDS_HdrstFdRrUDn "ENM";
BA_ "SignalLongName" SG_ 1244 LRSCDS_HdrstFdRrUDn "Left Rear Seat Control Display Status : Headrest Forward/Rearward and Up/Down";
BA_ "SignalType" SG_ 1244 LRSCDS_HdrstTltFwdRr "ENM";
BA_ "SignalLongName" SG_ 1244 LRSCDS_HdrstTltFwdRr "Left Rear Seat Control Display Status : Headrest Tilt Forward/Rearward";
BA_ "SignalType" SG_ 1244 LRSCDS_HdrstUpDn "ENM";
BA_ "SignalLongName" SG_ 1244 LRSCDS_HdrstUpDn "Left Rear Seat Control Display Status : Headrest Up/Down";
BA_ "SignalType" SG_ 1244 LRSCDS_LmbrUpDwn "ENM";
BA_ "SignalLongName" SG_ 1244 LRSCDS_LmbrUpDwn "Left Rear Seat Control Display Status : Lumbar Up/Down";
BA_ "SignalType" SG_ 1244 LRSCDS_DispReq "ENM";
BA_ "SignalLongName" SG_ 1244 LRSCDS_DispReq "Left Rear Seat Control Display Status : Display Request";
BA_ "SignalType" SG_ 1244 LRSCDS_MassgIntsty "ENM";
BA_ "SignalLongName" SG_ 1244 LRSCDS_MassgIntsty "Left Rear Seat Control Display Status : Massage Intensity";
BA_ "SignalType" SG_ 1244 LRSCDS_HdrstWngInOt "ENM";
BA_ "SignalLongName" SG_ 1244 LRSCDS_HdrstWngInOt "Left Rear Seat Control Display Status : Headrest Wings In/Out";
BA_ "SignalType" SG_ 1244 LRSCDS_LmbrUDnFdRr "ENM";
BA_ "SignalLongName" SG_ 1244 LRSCDS_LmbrUDnFdRr "Left Rear Seat Control Display Status : Lumbar Up/Down and Forward/Rearward";
BA_ "SignalType" SG_ 1244 LRSCDS_CshLgAdjFdRr "ENM";
BA_ "SignalLongName" SG_ 1244 LRSCDS_CshLgAdjFdRr "Left Rear Seat Control Display Status : Cushion Length Adjustment Forward/Rearward";
BA_ "SignalType" SG_ 1244 LRSCDS_HdrstFwdRrwd "ENM";
BA_ "SignalLongName" SG_ 1244 LRSCDS_HdrstFwdRrwd "Left Rear Seat Control Display Status : Headrest Forward/Rearward";
BA_ "SignalType" SG_ 1244 LRSCDS_LmbrFwdRr "ENM";
BA_ "SignalLongName" SG_ 1244 LRSCDS_LmbrFwdRr "Left Rear Seat Control Display Status : Lumbar Forward/Rearward";
BA_ "SignalType" SG_ 1244 LRSCDS_Massg "ENM";
BA_ "SignalLongName" SG_ 1244 LRSCDS_Massg "Left Rear Seat Control Display Status : Massage";
BA_ "SignalType" SG_ 1244 SAP_SecAxlOpMdAuth "ENM";
BA_ "SignalLongName" SG_ 1244 SAP_SecAxlOpMdAuth "Secondary Axle Protected : Secondary Axle Operational Mode Authenticated";
BA_ "SignalType" SG_ 1244 LRSCDS_BkCshBlstInOt "ENM";
BA_ "SignalLongName" SG_ 1244 LRSCDS_BkCshBlstInOt "Left Rear Seat Control Display Status : Back and Cushion Bolster In/Out";
BA_ "SignalType" SG_ 1244 LRSCDS_MassgTyp "ENM";
BA_ "SignalLongName" SG_ 1244 LRSCDS_MassgTyp "Left Rear Seat Control Display Status : Massage Type";
BA_ "SignalLongName" SG_ 1244 SAP_SecAxl4WDAWDEstTrqAuth "Secondary Axle Protected : Secondary Axle 4WD AWD Estimated Torque Authenticated";
BA_ "SignalType" SG_ 1244 SAP_SecAxl4WDAWDStatAuth "ENM";
BA_ "SignalLongName" SG_ 1244 SAP_SecAxl4WDAWDStatAuth "Secondary Axle Protected : Secondary Axle 4WD AWD Status Authenticated";
BA_ "SignalType" SG_ 1244 SAP_SecAxlOpMdAuth_Inv "ENM";
BA_ "SignalLongName" SG_ 1244 SAP_SecAxlOpMdAuth_Inv "Secondary Axle Protected : Secondary Axle Operational Mode Authenticated Invalid";
BA_ "SignalType" SG_ 1244 SAP_SecAxl4WDAWDEstTrqAuth_Inv "ENM";
BA_ "SignalLongName" SG_ 1244 SAP_SecAxl4WDAWDEstTrqAuth_Inv "Secondary Axle Protected : Secondary Axle 4WD AWD Estimated Torque Authenticated Invalid";
BA_ "SignalType" SG_ 1244 AdpLghtRspTypCstCurSetVal "ENM";
BA_ "SignalLongName" SG_ 1244 AdpLghtRspTypCstCurSetVal "Adaptive Lighting Response Type Customization Current Setting Value";
BA_ "SignalType" SG_ 1244 HSP_HptcStPrsntAuth "ENM";
BA_ "SignalLongName" SG_ 1244 HSP_HptcStPrsntAuth "Haptic Seat Protected : Haptic Seat Present Authenticated";
BA_ "SignalType" SG_ 1244 HSP_DrvAlrtTypCstCurrSetValAuth "ENM";
BA_ "SignalLongName" SG_ 1244 HSP_DrvAlrtTypCstCurrSetValAuth "Haptic Seat Protected : Driver Alert Type Customization Current Setting Value Authenticated";
BA_ "SignalType" SG_ 1245 LFSCDS_LmbrUDnFdRr "ENM";
BA_ "SignalLongName" SG_ 1245 LFSCDS_LmbrUDnFdRr "Left Front Seat Control Display Status : Lumbar Up/Down and Forward/Rearward";
BA_ "SignalType" SG_ 1245 LFSCDS_DispReq "ENM";
BA_ "SignalLongName" SG_ 1245 LFSCDS_DispReq "Left Front Seat Control Display Status : Display Request";
BA_ "SignalType" SG_ 1245 LFSCDS_UprShldrFdRr "ENM";
BA_ "SignalLongName" SG_ 1245 LFSCDS_UprShldrFdRr "Left Front Seat Control Display Status : Upper Shoulder Forward/Rearward";
BA_ "SignalType" SG_ 1245 LFSCDS_LmbrUpDwn "ENM";
BA_ "SignalLongName" SG_ 1245 LFSCDS_LmbrUpDwn "Left Front Seat Control Display Status : Lumbar Up/Down";
BA_ "SignalType" SG_ 1245 LFSCDS_Massg "ENM";
BA_ "SignalLongName" SG_ 1245 LFSCDS_Massg "Left Front Seat Control Display Status : Massage";
BA_ "SignalType" SG_ 1245 LFSCDS_BkBlstrInOut "ENM";
BA_ "SignalLongName" SG_ 1245 LFSCDS_BkBlstrInOut "Left Front Seat Control Display Status : Back Bolster In/Out";
BA_ "SignalType" SG_ 1245 LFSCDS_HdrstTltFwdRr "ENM";
BA_ "SignalLongName" SG_ 1245 LFSCDS_HdrstTltFwdRr "Left Front Seat Control Display Status : Headrest Tilt Forward/Rearward";
BA_ "SignalType" SG_ 1245 LFSCDS_LmbrFwdRr "ENM";
BA_ "SignalLongName" SG_ 1245 LFSCDS_LmbrFwdRr "Left Front Seat Control Display Status : Lumbar Forward/Rearward";
BA_ "SignalType" SG_ 1245 LFSCDS_MassgTyp "ENM";
BA_ "SignalLongName" SG_ 1245 LFSCDS_MassgTyp "Left Front Seat Control Display Status : Massage Type";
BA_ "SignalType" SG_ 1245 LFSCDS_HdrstFdRrUDn "ENM";
BA_ "SignalLongName" SG_ 1245 LFSCDS_HdrstFdRrUDn "Left Front Seat Control Display Status : Headrest Forward/Rearward and Up/Down";
BA_ "SignalType" SG_ 1245 LFSCDS_CshBlstrInOut "ENM";
BA_ "SignalLongName" SG_ 1245 LFSCDS_CshBlstrInOut "Left Front Seat Control Display Status : Cushion Bolster In/Out";
BA_ "SignalType" SG_ 1245 LFSCDS_HdrstUpDn "ENM";
BA_ "SignalLongName" SG_ 1245 LFSCDS_HdrstUpDn "Left Front Seat Control Display Status : Headrest Up/Down";
BA_ "SignalType" SG_ 1245 LFSCDS_HdrstWngInOt "ENM";
BA_ "SignalLongName" SG_ 1245 LFSCDS_HdrstWngInOt "Left Front Seat Control Display Status : Headrest Wings In/Out";
BA_ "SignalType" SG_ 1245 LFSCDS_BkCshBlstInOt "ENM";
BA_ "SignalLongName" SG_ 1245 LFSCDS_BkCshBlstInOt "Left Front Seat Control Display Status : Back and Cushion Bolster In/Out";
BA_ "SignalType" SG_ 1245 SDGPARS_CntrLtSd "ENM";
BA_ "SignalLongName" SG_ 1245 SDGPARS_CntrLtSd "Side Distance Guard Park Assist Region Status : Center Left Side Region";
BA_ "SignalType" SG_ 1245 LFSCDS_MassgIntsty "ENM";
BA_ "SignalLongName" SG_ 1245 LFSCDS_MassgIntsty "Left Front Seat Control Display Status : Massage Intensity";
BA_ "SignalType" SG_ 1245 LFSCDS_CshLgAdjFdRr "ENM";
BA_ "SignalLongName" SG_ 1245 LFSCDS_CshLgAdjFdRr "Left Front Seat Control Display Status : Cushion Length Adjustment Forward/Rearward";
BA_ "SignalType" SG_ 1245 LFSCDS_HdrstFwdRrwd "ENM";
BA_ "SignalLongName" SG_ 1245 LFSCDS_HdrstFwdRrwd "Left Front Seat Control Display Status : Headrest Forward/Rearward";
BA_ "SignalType" SG_ 1245 SDGPARS_FrtLtSd "ENM";
BA_ "SignalLongName" SG_ 1245 SDGPARS_FrtLtSd "Side Distance Guard Park Assist Region Status : Front Left Side Region";
BA_ "SignalType" SG_ 1245 SDGPARS_RrRtSd "ENM";
BA_ "SignalLongName" SG_ 1245 SDGPARS_RrRtSd "Side Distance Guard Park Assist Region Status : Rear Right Side Region";
BA_ "SignalType" SG_ 1245 SDGPARS_RrLtSd "ENM";
BA_ "SignalLongName" SG_ 1245 SDGPARS_RrLtSd "Side Distance Guard Park Assist Region Status : Rear Left Side Region";
BA_ "SignalType" SG_ 1245 SDGPARS_CntrRtSd "ENM";
BA_ "SignalLongName" SG_ 1245 SDGPARS_CntrRtSd "Side Distance Guard Park Assist Region Status : Center Right Side Region";
BA_ "SignalType" SG_ 1245 AutoHldEnbld "ENM";
BA_ "SignalLongName" SG_ 1245 AutoHldEnbld "Auto Hold Enabled";
BA_ "SignalType" SG_ 1245 SDGPARS_FrtRtSd "ENM";
BA_ "SignalLongName" SG_ 1245 SDGPARS_FrtRtSd "Side Distance Guard Park Assist Region Status : Front Right Side Region";
BA_ "SignalType" SG_ 1246 PCOSN_NtfnSecRowCntrStBltSts "ENM";
BA_ "SignalLongName" SG_ 1246 PCOSN_NtfnSecRowCntrStBltSts "Post Collision OnStar Notification : Notification Second Row Center Seat Belt Status";
BA_ "SignalType" SG_ 1246 PCOSN_NtfnSecRowLtStBltSts "ENM";
BA_ "SignalLongName" SG_ 1246 PCOSN_NtfnSecRowLtStBltSts "Post Collision OnStar Notification : Notification Second Row Left Seat Belt Status";
BA_ "SignalType" SG_ 1246 PCOSN_NtfnThrdRowCntrStBltSts "ENM";
BA_ "SignalLongName" SG_ 1246 PCOSN_NtfnThrdRowCntrStBltSts "Post Collision OnStar Notification : Notification Third Row Center Seat Belt Status";
BA_ "SignalType" SG_ 1246 PCOSN_NtfnImpDeltVelTxSts "ENM";
BA_ "SignalLongName" SG_ 1246 PCOSN_NtfnImpDeltVelTxSts "Post Collision OnStar Notification : Notification Impact Delta Velocity Transmit Status";
BA_ "SignalLongName" SG_ 1246 PCOSN_NtfnImpMaxLongDeltVel "Post Collision OnStar Notification : Notification Impact Maximum Longitudinal Delta Velocity";
BA_ "SignalType" SG_ 1246 PCOSN_NtfnSecRowCntrStOccpSts "ENM";
BA_ "SignalLongName" SG_ 1246 PCOSN_NtfnSecRowCntrStOccpSts "Post Collision OnStar Notification : Notification Second Row Center Seat Occupancy Status";
BA_ "SignalType" SG_ 1246 PCOSN_NtfnSecRowLtStOccpSts "ENM";
BA_ "SignalLongName" SG_ 1246 PCOSN_NtfnSecRowLtStOccpSts "Post Collision OnStar Notification : Notification Second Row Left Seat Occupancy Status";
BA_ "SignalType" SG_ 1246 PCOSN_NtfnSecRowRtStBltSts "ENM";
BA_ "SignalLongName" SG_ 1246 PCOSN_NtfnSecRowRtStBltSts "Post Collision OnStar Notification : Notification Second Row Right Seat Belt Status";
BA_ "SignalType" SG_ 1246 PCOSN_NtfnThrdRowCntrStOccpSts "ENM";
BA_ "SignalLongName" SG_ 1246 PCOSN_NtfnThrdRowCntrStOccpSts "Post Collision OnStar Notification : Notification Third Row Center Seat Occupancy Status";
BA_ "SignalLongName" SG_ 1246 PCOSN_NtfnImpMaxLatDeltVel "Post Collision OnStar Notification : Notification Impact Maximum Lateral Delta Velocity";
BA_ "SignalLongName" SG_ 1246 PCOSN_NtfnEvntSyncCnt "Post Collision OnStar Notification : Notification Event Sync Counter";
BA_ "SignalType" SG_ 1246 PCOSN_NtfnThrdRowRtStOccpSts "ENM";
BA_ "SignalLongName" SG_ 1246 PCOSN_NtfnThrdRowRtStOccpSts "Post Collision OnStar Notification : Notification Third Row Right Seat Occupancy Status";
BA_ "SignalType" SG_ 1246 PCOSN_NtfnFrstPsngrStBltSts "ENM";
BA_ "SignalLongName" SG_ 1246 PCOSN_NtfnFrstPsngrStBltSts "Post Collision OnStar Notification : Notification Front Passenger Seat Belt Status";
BA_ "SignalType" SG_ 1246 PCOSN_NtfnFrstPsngrStOccpSts "ENM";
BA_ "SignalLongName" SG_ 1246 PCOSN_NtfnFrstPsngrStOccpSts "Post Collision OnStar Notification : Notification Front Passenger Seat Occupancy Status";
BA_ "SignalType" SG_ 1246 PCOSN_NtfnSecRowRtStOccpSts "ENM";
BA_ "SignalLongName" SG_ 1246 PCOSN_NtfnSecRowRtStOccpSts "Post Collision OnStar Notification : Notification Second Row Right Seat Occupancy Status";
BA_ "SignalType" SG_ 1246 PCOSN_NtfnThrdRowLtStOccpSts "ENM";
BA_ "SignalLongName" SG_ 1246 PCOSN_NtfnThrdRowLtStOccpSts "Post Collision OnStar Notification : Notification Third Row Left Seat Occupancy Status";
BA_ "SignalType" SG_ 1246 PCOSN_NtfnThrdRowRtStBltSts "ENM";
BA_ "SignalLongName" SG_ 1246 PCOSN_NtfnThrdRowRtStBltSts "Post Collision OnStar Notification : Notification Third Row Right Seat Belt Status";
BA_ "SignalType" SG_ 1246 PCOSN_NtfnDrvrStBltSts "ENM";
BA_ "SignalLongName" SG_ 1246 PCOSN_NtfnDrvrStBltSts "Post Collision OnStar Notification : Notification Driver Seat Belt Status";
BA_ "SignalType" SG_ 1246 PCOSN_NtfnThrdRowLtStBltSts "ENM";
BA_ "SignalLongName" SG_ 1246 PCOSN_NtfnThrdRowLtStBltSts "Post Collision OnStar Notification : Notification Third Row Left Seat Belt Status";
BA_ "SignalType" SG_ 1246 TDAP_DrvrStMemIdfrAuth "ENM";
BA_ "SignalLongName" SG_ 1246 TDAP_DrvrStMemIdfrAuth "Teen Driver Active Protected : Driver Seat Memory Identifier Authenticated";
BA_ "SignalType" SG_ 1246 TDAP_DrvrIdfrAuth "ENM";
BA_ "SignalLongName" SG_ 1246 TDAP_DrvrIdfrAuth "Teen Driver Active Protected : Driver Identifier Authenticated";
BA_ "SignalType" SG_ 1246 TDAP_TeenDrvrActvAuth "ENM";
BA_ "SignalLongName" SG_ 1246 TDAP_TeenDrvrActvAuth "Teen Driver Active Protected : Teen Driver Active Authenticated";
BA_ "SignalLongName" SG_ 1247 RRSMP_Type5 "Right Rear Seat Massage Priority : Type 5";
BA_ "SignalLongName" SG_ 1247 RRSMP_Type14 "Right Rear Seat Massage Priority : Type 14";
BA_ "SignalLongName" SG_ 1247 RRSMP_Type2 "Right Rear Seat Massage Priority : Type 2";
BA_ "SignalLongName" SG_ 1247 RRSMP_Type10 "Right Rear Seat Massage Priority : Type 10";
BA_ "SignalLongName" SG_ 1247 RRSMP_MaxDispVal "Right Rear Seat Massage Priority : Maximum Display Value";
BA_ "SignalLongName" SG_ 1247 RRSMP_Type3 "Right Rear Seat Massage Priority : Type 3";
BA_ "SignalLongName" SG_ 1247 RRSMP_Type1 "Right Rear Seat Massage Priority : Type 1";
BA_ "SignalLongName" SG_ 1247 RRSMP_Type11 "Right Rear Seat Massage Priority : Type 11";
BA_ "SignalLongName" SG_ 1247 RRSMP_Type9 "Right Rear Seat Massage Priority : Type 9";
BA_ "SignalLongName" SG_ 1247 RRSMP_Type7 "Right Rear Seat Massage Priority : Type 7";
BA_ "SignalLongName" SG_ 1247 RRSMP_Type15 "Right Rear Seat Massage Priority : Type 15";
BA_ "SignalLongName" SG_ 1247 RRSMP_Type13 "Right Rear Seat Massage Priority : Type 13";
BA_ "SignalLongName" SG_ 1247 RRSMP_Type8 "Right Rear Seat Massage Priority : Type 8";
BA_ "SignalLongName" SG_ 1247 RRSMP_Type12 "Right Rear Seat Massage Priority : Type 12";
BA_ "SignalLongName" SG_ 1247 RRSMP_Type4 "Right Rear Seat Massage Priority : Type 4";
BA_ "SignalType" SG_ 1247 AutoHgBmActReq "ENM";
BA_ "SignalLongName" SG_ 1247 AutoHgBmActReq "Auto High Beam Activation Request";
BA_ "SignalLongName" SG_ 1247 RRSMP_Type6 "Right Rear Seat Massage Priority : Type 6";
BA_ "SignalLongName" SG_ 1248 RFSMP_Type7 "Right Front Seat Massage Priority : Type 7";
BA_ "SignalLongName" SG_ 1248 RFSMP_Type12 "Right Front Seat Massage Priority : Type 12";
BA_ "SignalLongName" SG_ 1248 RFSMP_Type14 "Right Front Seat Massage Priority : Type 14";
BA_ "SignalLongName" SG_ 1248 RFSMP_Type3 "Right Front Seat Massage Priority : Type 3";
BA_ "SignalLongName" SG_ 1248 RFSMP_Type13 "Right Front Seat Massage Priority : Type 13";
BA_ "SignalLongName" SG_ 1248 RFSMP_Type4 "Right Front Seat Massage Priority : Type 4";
BA_ "SignalLongName" SG_ 1248 RFSMP_Type5 "Right Front Seat Massage Priority : Type 5";
BA_ "SignalLongName" SG_ 1248 RFSMP_MaxDispVal "Right Front Seat Massage Priority : Maximum Display Value";
BA_ "SignalLongName" SG_ 1248 RFSMP_Type6 "Right Front Seat Massage Priority : Type 6";
BA_ "SignalLongName" SG_ 1248 RFSMP_Type10 "Right Front Seat Massage Priority : Type 10";
BA_ "SignalLongName" SG_ 1248 RFSMP_Type11 "Right Front Seat Massage Priority : Type 11";
BA_ "SignalLongName" SG_ 1248 RFSMP_Type9 "Right Front Seat Massage Priority : Type 9";
BA_ "SignalLongName" SG_ 1248 RFSMP_Type15 "Right Front Seat Massage Priority : Type 15";
BA_ "SignalLongName" SG_ 1248 RFSMP_Type1 "Right Front Seat Massage Priority : Type 1";
BA_ "SignalLongName" SG_ 1248 RFSMP_Type8 "Right Front Seat Massage Priority : Type 8";
BA_ "SignalType" SG_ 1248 AutMemRclCstStAvl "ENM";
BA_ "SignalLongName" SG_ 1248 AutMemRclCstStAvl "AutoMemoryRecallCustomizationSettingAvailable";
BA_ "SignalLongName" SG_ 1248 RFSMP_Type2 "Right Front Seat Massage Priority : Type 2";
BA_ "SignalLongName" SG_ 1249 LRSMP_Type6 "Left Rear Seat Massage Priority : Type 6";
BA_ "SignalLongName" SG_ 1249 LRSMP_Type15 "Left Rear Seat Massage Priority : Type 15";
BA_ "SignalLongName" SG_ 1249 LRSMP_Type13 "Left Rear Seat Massage Priority : Type 13";
BA_ "SignalLongName" SG_ 1249 LRSMP_Type2 "Left Rear Seat Massage Priority : Type 2";
BA_ "SignalLongName" SG_ 1249 LRSMP_Type5 "Left Rear Seat Massage Priority : Type 5";
BA_ "SignalLongName" SG_ 1249 LRSMP_MaxDispVal "Left Rear Seat Massage Priority : Maximum Display Value";
BA_ "SignalLongName" SG_ 1249 LRSMP_Type11 "Left Rear Seat Massage Priority : Type 11";
BA_ "SignalLongName" SG_ 1249 LRSMP_Type10 "Left Rear Seat Massage Priority : Type 10";
BA_ "SignalLongName" SG_ 1249 LRSMP_Type3 "Left Rear Seat Massage Priority : Type 3";
BA_ "SignalLongName" SG_ 1249 LRSMP_Type7 "Left Rear Seat Massage Priority : Type 7";
BA_ "SignalLongName" SG_ 1249 LRSMP_Type9 "Left Rear Seat Massage Priority : Type 9";
BA_ "SignalLongName" SG_ 1249 LRSMP_Type12 "Left Rear Seat Massage Priority : Type 12";
BA_ "SignalLongName" SG_ 1249 LRSMP_Type14 "Left Rear Seat Massage Priority : Type 14";
BA_ "SignalLongName" SG_ 1249 LRSMP_Type8 "Left Rear Seat Massage Priority : Type 8";
BA_ "SignalLongName" SG_ 1249 LRSMP_Type4 "Left Rear Seat Massage Priority : Type 4";
BA_ "SignalType" SG_ 1249 AdpLghtRspTypCstStAvl "ENM";
BA_ "SignalLongName" SG_ 1249 AdpLghtRspTypCstStAvl "Adaptive Lighting Response Type Customization Setting Available";
BA_ "SignalLongName" SG_ 1249 LRSMP_Type1 "Left Rear Seat Massage Priority : Type 1";
BA_ "SignalLongName" SG_ 1250 LFSMP_Type1 "Left Front Seat Massage Priority : Type 1";
BA_ "SignalLongName" SG_ 1250 LFSMP_Type10 "Left Front Seat Massage Priority : Type 10";
BA_ "SignalLongName" SG_ 1250 LFSMP_Type2 "Left Front Seat Massage Priority : Type 2";
BA_ "SignalLongName" SG_ 1250 LFSMP_Type9 "Left Front Seat Massage Priority : Type 9";
BA_ "SignalLongName" SG_ 1250 LFSMP_Type11 "Left Front Seat Massage Priority : Type 11";
BA_ "SignalLongName" SG_ 1250 LFSMP_Type13 "Left Front Seat Massage Priority : Type 13";
BA_ "SignalLongName" SG_ 1250 LFSMP_Type4 "Left Front Seat Massage Priority : Type 4";
BA_ "SignalLongName" SG_ 1250 LFSMP_Type12 "Left Front Seat Massage Priority : Type 12";
BA_ "SignalLongName" SG_ 1250 LFSMP_Type14 "Left Front Seat Massage Priority : Type 14";
BA_ "SignalLongName" SG_ 1250 LFSMP_Type5 "Left Front Seat Massage Priority : Type 5";
BA_ "SignalLongName" SG_ 1250 LFSMP_Type6 "Left Front Seat Massage Priority : Type 6";
BA_ "SignalLongName" SG_ 1250 LFSMP_Type3 "Left Front Seat Massage Priority : Type 3";
BA_ "SignalLongName" SG_ 1250 LFSMP_Type8 "Left Front Seat Massage Priority : Type 8";
BA_ "SignalLongName" SG_ 1250 LFSMP_Type7 "Left Front Seat Massage Priority : Type 7";
BA_ "SignalType" SG_ 1250 ACCBRP_ACCActvAuth "ENM";
BA_ "SignalLongName" SG_ 1250 ACCBRP_ACCActvAuth "Adaptive Cruise Control General Information 1 Protected : Adaptive Cruise Control Active Authenticated";
BA_ "SignalLongName" SG_ 1250 LFSMP_Type15 "Left Front Seat Massage Priority : Type 15";
BA_ "SignalLongName" SG_ 1250 LFSMP_MaxDispVal "Left Front Seat Massage Priority : Maximum Display Value";
BA_ "SignalLongName" SG_ 44 VMI1P_AccelActlPstnAuth "Vehicle Motion Information 1 Protected : Accelerator Actual Position Authenticated";
BA_ "SignalType" SG_ 44 VMI1P_VehTopSpdLimModeActvAuth "ENM";
BA_ "SignalLongName" SG_ 44 VMI1P_VehTopSpdLimModeActvAuth "Vehicle Motion Information 1 Protected : Vehicle Top Speed Limit Mode Active Authenticated";
BA_ "SignalType" SG_ 44 VMI1P_AccelActlPstnAuth_Inv "ENM";
BA_ "SignalLongName" SG_ 44 VMI1P_AccelActlPstnAuth_Inv "Vehicle Motion Information 1 Protected : Accelerator Actual Position Authenticated Invalid";
BA_ "SignalLongName" SG_ 44 VMI1P_VehTopSpdLimArbdValAuth "Vehicle Motion Information 1 Protected : Vehicle Top Speed Limit Arbitrated Value Authenticated";
BA_ "SignalType" SG_ 44 VMI1P_AccelPedOvrrdActvAuth "ENM";
BA_ "SignalLongName" SG_ 44 VMI1P_AccelPedOvrrdActvAuth "Vehicle Motion Information 1 Protected : Accelerator Pedal Override Active Authenticated";
BA_ "SignalLongName" SG_ 611 BVSCP_BdyCtlTopSpdLimReqValAuth "Body Vehicle Speed Control Protected : Body Control Top Speed Limit Request Value Authenticated";
BA_ "SignalLongName" SG_ 611 RdWhlAng "Road Wheel Angle";
BA_ "SignalType" SG_ 611 RdWhlAng_Inv "ENM";
BA_ "SignalLongName" SG_ 611 RdWhlAng_Inv "Road Wheel Angle Invalid";
BA_ "SignalLongName" SG_ 611 VehPtchAng "Vehicle Pitch Angle";
BA_ "SignalType" SG_ 611 VehPtchAng_Inv "ENM";
BA_ "SignalLongName" SG_ 611 VehPtchAng_Inv "Vehicle Pitch Angle Invalid";
BA_ "SignalLongName" SG_ 611 VehRollAng "Vehicle Roll Angle";
BA_ "SignalType" SG_ 611 VehRollAng_Inv "ENM";
BA_ "SignalLongName" SG_ 611 VehRollAng_Inv "Vehicle Roll Angle Invalid";
BA_ "SignalLongName" SG_ 611 BSIR2P_BrkgSysVhTpSpLmValAuth "EBCM General Information 3 Protected : Braking System Vehicle Top Speed Limit Value Authenticated";
BA_ "SignalLongName" SG_ 611 CTGI1P_CnvtTpSpLimRqValAuth "Convertible Top General Information 1 Protected : Convertible Top Speed Limit Request Value Authenticated";
BA_ "SignalType" SG_ 611 CnvtTopModSpdLimIndOn "ENM";
BA_ "SignalLongName" SG_ 611 CnvtTopModSpdLimIndOn "Convertible Top Module Speed Limit Indication On";
BA_ "SignalLongName" SG_ 612 IntDimDspLvl "Interior Dimming Display Level";
BA_ "SignalLongName" SG_ 612 DeadFrntSwtchIllumLvl "Dead Front Switch Illumination Level";
BA_ "SignalLongName" SG_ 612 IntDimLvl "Interior Dimming Backlighting Level";
BA_ "SignalType" SG_ 612 TEGP_TrnsShftLvrPstnAuth "ENM";
BA_ "SignalLongName" SG_ 612 TEGP_TrnsShftLvrPstnAuth "Transmission Estimated Gear Protected : Transmission Shift Lever Position Authenticated";
BA_ "SignalType" SG_ 612 TrnsRngInhbtSt "ENM";
BA_ "SignalLongName" SG_ 612 TrnsRngInhbtSt "Transmission Range Inhibit State";
BA_ "SignalType" SG_ 612 IntAmbtBrghtnsCtrlStVal "ENM";
BA_ "SignalLongName" SG_ 612 IntAmbtBrghtnsCtrlStVal "Interior Ambient Brightness Control Setting Value";
BA_ "SignalType" SG_ 612 TEGP_TrnsShftLvrPstnAuth_Inv "ENM";
BA_ "SignalLongName" SG_ 612 TEGP_TrnsShftLvrPstnAuth_Inv "Transmission Estimated Gear Protected : Transmission Shift Lever Position Authenticated Invalid";
BA_ "SignalType" SG_ 612 TEGP_TransCmndGrAuth "ENM";
BA_ "SignalLongName" SG_ 612 TEGP_TransCmndGrAuth "Transmission Estimated Gear Protected : Transmission Commanded Gear Authenticated";
BA_ "SignalType" SG_ 612 IntAmbtBrghtnsCtrlStAvl "ENM";
BA_ "SignalLongName" SG_ 612 IntAmbtBrghtnsCtrlStAvl "Interior Ambient Brightness Control Setting Available";
BA_ "SignalType" SG_ 612 BkUpPwrMdRnCrnkOutSt "ENM";
BA_ "SignalLongName" SG_ 612 BkUpPwrMdRnCrnkOutSt "Backup Power Mode RUN ACCESSORY Output State";
BA_ "SignalType" SG_ 612 TrnsTUTDMdSt "ENM";
BA_ "SignalLongName" SG_ 612 TrnsTUTDMdSt "Transmission Tap Up/Tap Down Mode State";
BA_ "SignalType" SG_ 612 EASSI_StrtStpSt "ENM";
BA_ "SignalLongName" SG_ 612 EASSI_StrtStpSt "Engine Auto Start Stop Information : Start Stop State";
BA_ "SignalType" SG_ 612 TEGP_TrnsEstGrAuth "ENM";
BA_ "SignalLongName" SG_ 612 TEGP_TrnsEstGrAuth "Transmission Estimated Gear Protected : Transmission Estimated Gear Authenticated";
BA_ "SignalType" SG_ 612 TEGP_TrnsEngdStAuth_Inv "ENM";
BA_ "SignalLongName" SG_ 612 TEGP_TrnsEngdStAuth_Inv "Transmission Estimated Gear Protected : Transmission Engaged State Authenticated Invalid";
BA_ "SignalType" SG_ 612 TEGP_TrnsEngdStAuth "ENM";
BA_ "SignalLongName" SG_ 612 TEGP_TrnsEngdStAuth "Transmission Estimated Gear Protected : Transmission Engaged State Authenticated";
BA_ "SignalType" SG_ 612 TEGP_TrnsEstGrAuth_Inv "ENM";
BA_ "SignalLongName" SG_ 612 TEGP_TrnsEstGrAuth_Inv "Transmission Estimated Gear Protected : Transmission Estimated Gear Authenticated Invalid";
BA_ "SignalLongName" SG_ 181 FWDECP_LFAuth "Front Wheel Distance Edge Counter Protected : Wheel Distance Edge Counter Left Front Authenticated";
BA_ "SignalType" SG_ 181 FWDECP_RFAuth_Inv "ENM";
BA_ "SignalLongName" SG_ 181 FWDECP_RFAuth_Inv "Front Wheel Distance Edge Counter Protected : Wheel Distance Edge Counter Right Front Authenticated Invalid";
BA_ "SignalType" SG_ 181 FWDECP_RstOccAuth "ENM";
BA_ "SignalLongName" SG_ 181 FWDECP_RstOccAuth "Front Wheel Distance Edge Counter Protected : Front Wheel Distance Edge Counter Reset Occurred Authenticated";
BA_ "SignalType" SG_ 181 FWDECP_LFAuth_Inv "ENM";
BA_ "SignalLongName" SG_ 181 FWDECP_LFAuth_Inv "Front Wheel Distance Edge Counter Protected : Wheel Distance Edge Counter Left Front Authenticated Invalid";
BA_ "SignalLongName" SG_ 181 FWDECP_RFAuth "Front Wheel Distance Edge Counter Protected : Wheel Distance Edge Counter Right Front Authenticated";
BA_ "SignalLongName" SG_ 181 RWDECP_LRAuth "Rear Wheel Distance Edge Counter Protected : Rear Wheel Distance Edge Counter Left Rear Authenticated";
BA_ "SignalType" SG_ 181 RWDECP_RRAuth_Inv "ENM";
BA_ "SignalLongName" SG_ 181 RWDECP_RRAuth_Inv "Rear Wheel Distance Edge Counter Protected : Rear Wheel Distance Edge Counter Right Rear Authenticated Invalid";
BA_ "SignalType" SG_ 181 RWDECP_RstOccAuth "ENM";
BA_ "SignalLongName" SG_ 181 RWDECP_RstOccAuth "Rear Wheel Distance Edge Counter Protected : Rear Wheel Distance Edge Counter Reset Occurred Authenticated";
BA_ "SignalType" SG_ 181 RWDECP_LRAuth_Inv "ENM";
BA_ "SignalLongName" SG_ 181 RWDECP_LRAuth_Inv "Rear Wheel Distance Edge Counter Protected : Rear Wheel Distance Edge Counter Left Rear Authenticated Invalid";
BA_ "SignalLongName" SG_ 181 RWDECP_RRAuth "Rear Wheel Distance Edge Counter Protected : Rear Wheel Distance Edge Counter Right Rear Authenticated";
BA_ "SignalType" SG_ 181 ASPATR_ClsnImntBrkgAxlTrqRqActv "ENM";
BA_ "SignalLongName" SG_ 181 ASPATR_ClsnImntBrkgAxlTrqRqActv "Active Safety Powertrain Axle Torque Request : Collision Imminent Braking Axle Torque Request Active";
BA_ "SignalType" SG_ 181 CIBAutoBrkReqActv "ENM";
BA_ "SignalLongName" SG_ 181 CIBAutoBrkReqActv "Collision Imminent Braking Autonomous Brake Request Active";
BA_ "SignalType" SG_ 181 DMSIP_DrvrAttnStatAuth_Inv "ENM";
BA_ "SignalLongName" SG_ 181 DMSIP_DrvrAttnStatAuth_Inv "Driver Monitoring System Information Protected : Driver Attention State Authenticated Invalid";
BA_ "SignalType" SG_ 181 DMSIP_DrvrAttnStatAuth "ENM";
BA_ "SignalLongName" SG_ 181 DMSIP_DrvrAttnStatAuth "Driver Monitoring System Information Protected : Driver Attention State Authenticated";
BA_ "SignalType" SG_ 181 ACCBRP_ReqActvAuth "ENM";
BA_ "SignalLongName" SG_ 181 ACCBRP_ReqActvAuth "Adaptive Cruise Control General Information 1 Protected : Adaptive Cruise Control Braking Request Active Authenticated";
BA_ "SignalType" SG_ 181 ACCATRIP_TrqActvAuth "ENM";
BA_ "SignalLongName" SG_ 181 ACCATRIP_TrqActvAuth "Adaptive Cruise Control General Information 1 Protected : Torque Active Authenticated";
BA_ "SignalType" SG_ 181 LCCPIP_LnCntrCtlAclPedLimRqAuth "ENM";
BA_ "SignalLongName" SG_ 181 LCCPIP_LnCntrCtlAclPedLimRqAuth "EOCM General Information 1 Protected : Lane Centering Control Accel Pedal Limiting Requested Authenticated";
BA_ "SignalLongName" SG_ 1251 EngOilPrs "Engine Oil Pressure";
BA_ "SignalType" SG_ 1251 EngOilPrs_Inv "ENM";
BA_ "SignalLongName" SG_ 1251 EngOilPrs_Inv "Engine Oil Pressure Invalid";
BA_ "SignalLongName" SG_ 1251 GenFldDutCyc "Generator Field Duty Cycle";
BA_ "SignalLongName" SG_ 1251 ACCTOSHiThrtLicVehTmToClsn1 "Adaptive Cruise Control Target Object Selection High Threat Licensable Vehicle Time to Collision 1";
BA_ "SignalLongName" SG_ 1251 LnFllwgTgtTrjctryLnCoef1 "Lane Following Target Trajectory Lane Coefficient 1";
BA_ "SignalType" SG_ 1251 StrgWhlTchSnsHndsOnStat "ENM";
BA_ "SignalLongName" SG_ 1251 StrgWhlTchSnsHndsOnStat "Steering Wheel Touch Sense Hands On State";
BA_ "SignalLongName" SG_ 40 HstVehLngVel "Host Vehicle Longitudinal Velocity";
BA_ "SignalType" SG_ 40 HstVehLngVel_Inv "ENM";
BA_ "SignalLongName" SG_ 40 HstVehLngVel_Inv "Host Vehicle Longitudinal Velocity Invalid";
BA_ "SignalLongName" SG_ 40 HstVehYawRate "Host Vehicle Yaw Rate";
BA_ "SignalType" SG_ 40 HstVehYawRate_Inv "ENM";
BA_ "SignalLongName" SG_ 40 HstVehYawRate_Inv "Host Vehicle Yaw Rate Invalid";
BA_ "SignalLongName" SG_ 40 HstVehLatVel "Host Vehicle Lateral Velocity";
BA_ "SignalType" SG_ 40 HstVehLatVel_Inv "ENM";
BA_ "SignalLongName" SG_ 40 HstVehLatVel_Inv "Host Vehicle Lateral Velocity Invalid";
BA_ "SignalLongName" SG_ 40 DASTP_StrTrqAuth "Driver Applied Steering Torque Protected : Driver Applied Steering Torque Authenticated";
BA_ "SignalLongName" SG_ 43 ESP_EngSpdAuth "Engine Speed Protected : Engine Speed Authenticated";
BA_ "SignalLongName" SG_ 43 TachEngSpd "Tachometer Engine Speed";
BA_ "SignalType" SG_ 43 ESP_EngSpdStAuth "ENM";
BA_ "SignalLongName" SG_ 43 ESP_EngSpdStAuth "Engine Speed Protected : Engine Speed State Authenticated";
BA_ "SignalType" SG_ 1172 TrlrTirePresProfXferSts "ENM";
BA_ "SignalLongName" SG_ 1172 TrlrTirePresProfXferSts "Trailer Tire Pressure Profile Transfer Status";
BA_ "SignalType" SG_ 1172 FrwdVehAhdIndReq "ENM";
BA_ "SignalLongName" SG_ 1172 FrwdVehAhdIndReq "Forward Vehicle Ahead Indication Request";
BA_ "SignalLongName" SG_ 1172 LnchCtlLineLckTmrVal "Launch Control Line Lock Timer Value";
BA_ "SignalType" SG_ 1172 ServPedtrnFrndlyAlrtIndOn "ENM";
BA_ "SignalLongName" SG_ 1172 ServPedtrnFrndlyAlrtIndOn "Service Pedestrian Friendly Alert Indication On";
BA_ "SignalType" SG_ 1172 RrAxlTmpInhIO "ENM";
BA_ "SignalLongName" SG_ 1172 RrAxlTmpInhIO "Rear Axle Temporary Inhibit Indication On";
BA_ "SignalType" SG_ 1172 RrAxlMlfIO "ENM";
BA_ "SignalLongName" SG_ 1172 RrAxlMlfIO "Rear Axle Malfunction Indication On";
BA_ "SignalType" SG_ 1172 RegVltgCtlEngyRcvryActv "ENM";
BA_ "SignalLongName" SG_ 1172 RegVltgCtlEngyRcvryActv "Regulated Voltage Control Energy Recovery Active";
BA_ "SignalType" SG_ 1172 HillDscntCtlDispActvIndOn "ENM";
BA_ "SignalLongName" SG_ 1172 HillDscntCtlDispActvIndOn "Hill Descent Control Display Active Indication On";
BA_ "SignalType" SG_ 1172 Deg360VidFtrPrsnt "ENM";
BA_ "SignalLongName" SG_ 1172 Deg360VidFtrPrsnt "Degree 360 Video Feature Present";
BA_ "SignalType" SG_ 1172 BrkgSysVehTopSpdLimIndOn "ENM";
BA_ "SignalLongName" SG_ 1172 BrkgSysVehTopSpdLimIndOn "Braking System Vehicle Top Speed Limit Indication On";
BA_ "SignalLongName" SG_ 1172 PrplDispTotPwr "Propulsion Display Total Power";
BA_ "SignalType" SG_ 1172 TrgrdVidRcrdrFtrPrsnt "ENM";
BA_ "SignalLongName" SG_ 1172 TrgrdVidRcrdrFtrPrsnt "Triggered Video Recorder Feature Present";
BA_ "SignalType" SG_ 1172 TireRRLoTracIndOn "ENM";
BA_ "SignalLongName" SG_ 1172 TireRRLoTracIndOn "Tire Right Rear Low Traction Indication On";
BA_ "SignalType" SG_ 1172 TireRFLoTracIndOn "ENM";
BA_ "SignalLongName" SG_ 1172 TireRFLoTracIndOn "Tire Right Front Low Traction Indication On";
BA_ "SignalType" SG_ 1172 TireLRLoTracIndOn "ENM";
BA_ "SignalLongName" SG_ 1172 TireLRLoTracIndOn "Tire Left Rear Low Traction Indication On";
BA_ "SignalType" SG_ 1172 TireLFLoTracIndOn "ENM";
BA_ "SignalLongName" SG_ 1172 TireLFLoTracIndOn "Tire Left Front Low Traction Indication On";
BA_ "SignalLongName" SG_ 1172 TDRevClnMtgnBrEvRpt "Teen Driver Reverse Collision Mitigation Braking Events Report";
BA_ "SignalType" SG_ 1172 MemIdfrIgnOnIndReq "ENM";
BA_ "SignalLongName" SG_ 1172 MemIdfrIgnOnIndReq "Memory Identifier Ignition On Indication Request";
BA_ "SignalType" SG_ 1172 HybStatElecVehModeOvrrd "ENM";
BA_ "SignalLongName" SG_ 1172 HybStatElecVehModeOvrrd "Hybrid State Electric Vehicle Mode Override";
BA_ "SignalType" SG_ 1172 ROSP_FrntPsRestOcpStatAuth "ENM";
BA_ "SignalLongName" SG_ 1172 ROSP_FrntPsRestOcpStatAuth "Restraint Occupancy Status Protected : Front Passenger Restraint Occupancy Status Authenticated";
BA_ "SignalLongName" SG_ 1172 HiVltgBatAvgTemp "High Voltage Battery Average Temperature";
BA_ "SignalType" SG_ 1172 HiVltgBatAvgTemp_Inv "ENM";
BA_ "SignalLongName" SG_ 1172 HiVltgBatAvgTemp_Inv "High Voltage Battery Average Temperature Invalid";
BA_ "SignalLongName" SG_ 1253 SLVFSP_SpdLimVsnFsdSpdAuth "Speed Limit Vision Fused Speed Protected : Speed Limit Vision Fused Speed Authenticated";
BA_ "SignalType" SG_ 1253 SLVFSP_SpdLimVsnFsdSpdUntAuth "ENM";
BA_ "SignalLongName" SG_ 1253 SLVFSP_SpdLimVsnFsdSpdUntAuth "Speed Limit Vision Fused Speed Protected : Speed Limit Vision Fused Speed Unit Authenticated";
BA_ "SignalLongName" SG_ 1066 CustUsblSOC "Customer Usable State of Charge";
BA_ "SignalType" SG_ 1066 CustUsblSOC_DuD "ENM";
BA_ "SignalLongName" SG_ 1066 CustUsblSOC_DuD "Customer Usable State of Charge Don't Use Data";
BA_ "SignalLongName" SG_ 1066 CustNonUsblSOCDispLvl "Customer Non Usable State of Charge Display Level";
BA_ "SignalLongName" SG_ 1066 PrplDispTotPwrLvlPct "Propulsion Display Total Power Level Percent";
BA_ "SignalLongName" SG_ 1066 EstdEleclPrplCpblty "Estimated Electrical Propulsion Capability";
BA_ "SignalLongName" SG_ 1066 HiVltgBatMinTemp "High Voltage Battery Minimum Temperature";
BA_ "SignalType" SG_ 1066 HiVltgBatMinTemp_Inv "ENM";
BA_ "SignalLongName" SG_ 1066 HiVltgBatMinTemp_Inv "High Voltage Battery Minimum Temperature Invalid";
BA_ "SignalType" SG_ 1066 TnDrvStBltShfIntlkCstAvlFlg4 "ENM";
BA_ "SignalLongName" SG_ 1066 TnDrvStBltShfIntlkCstAvlFlg4 "Teen Driver Seat Belt Shift Interlock Customization Availability Flag4";
BA_ "SignalType" SG_ 1066 TnDrvStBltShfIntlkCstAvlFlg3 "ENM";
BA_ "SignalLongName" SG_ 1066 TnDrvStBltShfIntlkCstAvlFlg3 "Teen Driver Seat Belt Shift Interlock Customization Availability Flag3";
BA_ "SignalType" SG_ 1066 TnDrvStBltShfIntlkCstAvlFlg2 "ENM";
BA_ "SignalLongName" SG_ 1066 TnDrvStBltShfIntlkCstAvlFlg2 "Teen Driver Seat Belt Shift Interlock Customization Availability Flag2";
BA_ "SignalType" SG_ 1066 TnDrvStBltShfIntlkCstAvlFlg1 "ENM";
BA_ "SignalLongName" SG_ 1066 TnDrvStBltShfIntlkCstAvlFlg1 "Teen Driver Seat Belt Shift Interlock Customization Availability Flag1";
BA_ "SignalType" SG_ 1066 PwrRrClsrCstSetAval "ENM";
BA_ "SignalLongName" SG_ 1066 PwrRrClsrCstSetAval "Power Rear Closure Customization Setting Available";
BA_ "SignalType" SG_ 1066 PwrRrClsrCstAvlFlg7 "ENM";
BA_ "SignalLongName" SG_ 1066 PwrRrClsrCstAvlFlg7 "Power Rear Closure Customization Availability Flag 7";
BA_ "SignalType" SG_ 1066 PwrRrClsrCstAvlFlg6 "ENM";
BA_ "SignalLongName" SG_ 1066 PwrRrClsrCstAvlFlg6 "Power Rear Closure Customization Availability Flag 6";
BA_ "SignalLongName" SG_ 1107 BatPrplDispPwrLvlPct "Battery Propulsion Display Power Level Percent";
BA_ "SignalLongName" SG_ 1107 RegenPwrLimdDispPct "Regenerative Power Limited Display Percent";
BA_ "SignalLongName" SG_ 1107 PrplCpbltyDispOprtgPstn "Propulsion Capability Display Operating Position";
BA_ "SignalLongName" SG_ 1107 EngPrplDispPwrLvlPct "Engine Propulsion Display Power Level Percent";
BA_ "SignalType" SG_ 1107 MemIdfrMemStorIndReq "ENM";
BA_ "SignalLongName" SG_ 1107 MemIdfrMemStorIndReq "Memory Identifier Memory Store Indication Request";
BA_ "SignalType" SG_ 1107 ServHiVltgBatIndReq "ENM";
BA_ "SignalLongName" SG_ 1107 ServHiVltgBatIndReq "Service High Voltage Battery Indication Request";
BA_ "SignalType" SG_ 1107 HtdStrgWhlInd_HVAC_FP_F "ENM";
BA_ "SignalLongName" SG_ 1107 HtdStrgWhlInd_HVAC_FP_F "Heated Steering Wheel Indication - HVAC Front Faceplate";
BA_ "SignalType" SG_ 1107 HiVltgBatLmtnDueToTempInd "ENM";
BA_ "SignalLongName" SG_ 1107 HiVltgBatLmtnDueToTempInd "High Voltage Battery Limitation Due to Temperature Indication";
BA_ "SignalType" SG_ 1107 ServHybSysIndOn "ENM";
BA_ "SignalLongName" SG_ 1107 ServHybSysIndOn "Service Hybrid System Indication On";
BA_ "SignalType" SG_ 1107 ReqFrtPsgrRstntOccFltInd "ENM";
BA_ "SignalLongName" SG_ 1107 ReqFrtPsgrRstntOccFltInd "Request Front Passenger Restraint Occupancy Fault Indication";
BA_ "SignalType" SG_ 1107 RegenPwrLimdIndOn "ENM";
BA_ "SignalLongName" SG_ 1107 RegenPwrLimdIndOn "Regenerative Power Limited Indication On";
BA_ "SignalType" SG_ 1107 RegenPwrLimdDispPctVsbl "ENM";
BA_ "SignalLongName" SG_ 1107 RegenPwrLimdDispPctVsbl "Regenerative Power Limited Display Percent Visible";
BA_ "SignalType" SG_ 1107 PrplDispTotPwrUntDisp "ENM";
BA_ "SignalLongName" SG_ 1107 PrplDispTotPwrUntDisp "Propulsion Display Total Power Unit Display";
BA_ "SignalType" SG_ 1107 LossOfPrplIndOn "ENM";
BA_ "SignalLongName" SG_ 1107 LossOfPrplIndOn "Loss Of Propulsion Indication On";
BA_ "SignalType" SG_ 1107 HybShfToPrkIndOn "ENM";
BA_ "SignalLongName" SG_ 1107 HybShfToPrkIndOn "Hybrid Shift to Park Indication On";
BA_ "SignalType" SG_ 1107 EngRnngDueToVehSpdIndOn "ENM";
BA_ "SignalLongName" SG_ 1107 EngRnngDueToVehSpdIndOn "Engine Running Due to Vehicle Speed Indication On";
BA_ "SignalType" SG_ 1107 InstnsFuelEconHybOvrrdReq "ENM";
BA_ "SignalLongName" SG_ 1107 InstnsFuelEconHybOvrrdReq "Instantaneous Fuel Economy Hybrid Override Request";
BA_ "SignalType" SG_ 1107 HybStatShtlModeOvrrd "ENM";
BA_ "SignalLongName" SG_ 1107 HybStatShtlModeOvrrd "Hybrid State Shuttle Mode Override";
BA_ "SignalType" SG_ 1107 DM6Denied "ENM";
BA_ "SignalLongName" SG_ 1107 DM6Denied "Drive Mode 6 Denied";
BA_ "SignalType" SG_ 1107 DM5Denied "ENM";
BA_ "SignalLongName" SG_ 1107 DM5Denied "Drive Mode 5 Denied";
BA_ "SignalType" SG_ 1107 DM4Denied "ENM";
BA_ "SignalLongName" SG_ 1107 DM4Denied "Drive Mode 4 Denied";
BA_ "SignalType" SG_ 1107 DM3Denied "ENM";
BA_ "SignalLongName" SG_ 1107 DM3Denied "Drive Mode 3 Denied";
BA_ "SignalType" SG_ 1107 JmpStrtSts "ENM";
BA_ "SignalLongName" SG_ 1107 JmpStrtSts "Jump Start Status";
BA_ "SignalType" SG_ 521 TSP_TmpDrvrShfCtlActvAuth "ENM";
BA_ "SignalLongName" SG_ 521 TSP_TmpDrvrShfCtlActvAuth "TCM General Information 1 Protected : Temporary Driver Shift Control Active Authenticated";
BA_ "SignalType" SG_ 521 TSP_ElecRngSeltnInDrvActvAuth "ENM";
BA_ "SignalLongName" SG_ 521 TSP_ElecRngSeltnInDrvActvAuth "TCM General Information 1 Protected : Electronic Range Selection in Drive Active Authenticated";
BA_ "SignalType" SG_ 45 VCBA_FrtJnctnActv "ENM";
BA_ "SignalLongName" SG_ 45 VCBA_FrtJnctnActv "Viewing Control Button Availability : Front Junction Active";
BA_ "SignalType" SG_ 45 VCBA_DynGdlnsActv "ENM";
BA_ "SignalLongName" SG_ 45 VCBA_DynGdlnsActv "Viewing Control Button Availability : Dynamic Guidelines Active";
BA_ "SignalType" SG_ 45 VCBA_CurbVwGdlnsActv "ENM";
BA_ "SignalLongName" SG_ 45 VCBA_CurbVwGdlnsActv "Viewing Control Button Availability : Curb View Guidelines Active";
BA_ "SignalType" SG_ 45 VCBA_CurbOvrhdActv "ENM";
BA_ "SignalLongName" SG_ 45 VCBA_CurbOvrhdActv "Viewing Control Button Availability : Curb Overhead Active";
BA_ "SignalType" SG_ 45 VCBA_CurbActv "ENM";
BA_ "SignalLongName" SG_ 45 VCBA_CurbActv "Viewing Control Button Availability : Curb Active";
BA_ "SignalType" SG_ 45 VCBA_CrgBedActv "ENM";
BA_ "SignalLongName" SG_ 45 VCBA_CrgBedActv "Viewing Control Button Availability : Cargo Bed Active";
BA_ "SignalType" SG_ 45 VCBA_BowlActv "ENM";
BA_ "SignalLongName" SG_ 45 VCBA_BowlActv "Viewing Control Button Availability : Bowl Active";
BA_ "SignalType" SG_ 45 VCBA_BedHtchActv "ENM";
BA_ "SignalLongName" SG_ 45 VCBA_BedHtchActv "Viewing Control Button Availability : Bed Hitch Active";
BA_ "SignalType" SG_ 45 VCBA_RrOvrhdActv "ENM";
BA_ "SignalLongName" SG_ 45 VCBA_RrOvrhdActv "Viewing Control Button Availability : Rear Overhead Active";
BA_ "SignalType" SG_ 45 VCBA_RrJnctnActv "ENM";
BA_ "SignalLongName" SG_ 45 VCBA_RrJnctnActv "Viewing Control Button Availability : Rear Junction Active";
BA_ "SignalType" SG_ 45 VCBA_RrHtchActv "ENM";
BA_ "SignalLongName" SG_ 45 VCBA_RrHtchActv "Viewing Control Button Availability : Rear Hitch Active";
BA_ "SignalType" SG_ 45 VCBA_LRTrlrTowMirActv "ENM";
BA_ "SignalLongName" SG_ 45 VCBA_LRTrlrTowMirActv "Viewing Control Button Availability : L R Trailer Towing Mirror Active";
BA_ "SignalType" SG_ 45 VCBA_JPActv "ENM";
BA_ "SignalLongName" SG_ 45 VCBA_JPActv "Viewing Control Button Availability : Japan Active";
BA_ "SignalType" SG_ 45 VCBA_InvsblTrlrActv "ENM";
BA_ "SignalLongName" SG_ 45 VCBA_InvsblTrlrActv "Viewing Control Button Availability : Invisible Trailer Active";
BA_ "SignalType" SG_ 45 VCBA_FrtPrspctvActv "ENM";
BA_ "SignalLongName" SG_ 45 VCBA_FrtPrspctvActv "Viewing Control Button Availability : Front Perspective Active";
BA_ "SignalType" SG_ 45 VCBA_FrtOvrhdActv "ENM";
BA_ "SignalLongName" SG_ 45 VCBA_FrtOvrhdActv "Viewing Control Button Availability : Front Overhead Active";
BA_ "SignalType" SG_ 45 VCBA_TrlrTowMirActv "ENM";
BA_ "SignalLongName" SG_ 45 VCBA_TrlrTowMirActv "Viewing Control Button Availability : Trailer Towing Mirror Active";
BA_ "SignalType" SG_ 45 VCBA_TrlrGdlnsActv "ENM";
BA_ "SignalLongName" SG_ 45 VCBA_TrlrGdlnsActv "Viewing Control Button Availability : Trailer Guidelines Active";
BA_ "SignalType" SG_ 45 VCBA_TrlrAux2Actv "ENM";
BA_ "SignalLongName" SG_ 45 VCBA_TrlrAux2Actv "Viewing Control Button Availability : Trailer Aux2 Active";
BA_ "SignalType" SG_ 45 VCBA_TrlrAux1CmbdActv "ENM";
BA_ "SignalLongName" SG_ 45 VCBA_TrlrAux1CmbdActv "Viewing Control Button Availability : Trailer Aux1 Combined Active";
BA_ "SignalType" SG_ 45 VCBA_TrlrAux1Actv "ENM";
BA_ "SignalLongName" SG_ 45 VCBA_TrlrAux1Actv "Viewing Control Button Availability : Trailer Aux1 Active";
BA_ "SignalType" SG_ 45 VCBA_SdRrwdActv "ENM";
BA_ "SignalLongName" SG_ 45 VCBA_SdRrwdActv "Viewing Control Button Availability : Side Rearward Active";
BA_ "SignalType" SG_ 45 VCBA_SdFrwdActv "ENM";
BA_ "SignalLongName" SG_ 45 VCBA_SdFrwdActv "Viewing Control Button Availability : Side Forward Active";
BA_ "SignalType" SG_ 45 VCBA_RrPrspctvActv "ENM";
BA_ "SignalLongName" SG_ 45 VCBA_RrPrspctvActv "Viewing Control Button Availability : Rear Perspective Active";
BA_ "SignalLongName" SG_ 45 VwgBowlVwAngSts "Viewing Bowl View Angle Status";
BA_ "SignalType" SG_ 45 VCBA_ZmdBowlActv "ENM";
BA_ "SignalLongName" SG_ 45 VCBA_ZmdBowlActv "Viewing Control Button Availability : Zoomed Bowl Active";
BA_ "SignalLongName" SG_ 45 SrrndVsnRcrdrNumDispdFiles "Surround Vision Recorder Number of Displayed Files";
BA_ "SignalType" SG_ 45 SrrndVsnRcrdrDelFileReqSts "ENM";
BA_ "SignalLongName" SG_ 45 SrrndVsnRcrdrDelFileReqSts "Surround Vision Recorder Delete File Request Status";
BA_ "SignalType" SG_ 45 SrrndVsnRcrdrVwprtSts "ENM";
BA_ "SignalLongName" SG_ 45 SrrndVsnRcrdrVwprtSts "Surround Vision Recorder Viewport Status";
BA_ "SignalType" SG_ 45 SrrndVsnRcrdrVwprtReq "ENM";
BA_ "SignalLongName" SG_ 45 SrrndVsnRcrdrVwprtReq "Surround Vision Recorder Viewport Request";
BA_ "SignalType" SG_ 45 SrrndVsnRcrdrPlybkSts "ENM";
BA_ "SignalLongName" SG_ 45 SrrndVsnRcrdrPlybkSts "Surround Vision Recorder Playback Status";
BA_ "SignalType" SG_ 45 SrrndVsnRcrdrRcrdSts "ENM";
BA_ "SignalLongName" SG_ 45 SrrndVsnRcrdrRcrdSts "Surround Vision Recorder Record Status";
BA_ "SignalType" SG_ 45 SrrndVsnRcrdrListPgSts "ENM";
BA_ "SignalLongName" SG_ 45 SrrndVsnRcrdrListPgSts "Surround Vision Recorder List Page Status";
BA_ "SignalType" SG_ 45 VGVS_TrlrActv "ENM";
BA_ "SignalLongName" SG_ 45 VGVS_TrlrActv "Viewing Guideline View Status : Trailer Active";
BA_ "SignalType" SG_ 45 VGVS_DynActv "ENM";
BA_ "SignalLongName" SG_ 45 VGVS_DynActv "Viewing Guideline View Status : Dynamic Active";
BA_ "SignalType" SG_ 45 VGVS_CurbVwActv "ENM";
BA_ "SignalLongName" SG_ 45 VGVS_CurbVwActv "Viewing Guideline View Status : Curb View Active";
BA_ "SignalType" SG_ 45 VCBA_TrnspHdActv "ENM";
BA_ "SignalLongName" SG_ 45 VCBA_TrnspHdActv "Viewing Control Button Availability : Transparent Hood Active";
BA_ "SignalType" SG_ 45 SrrndVsnRcrdrRcrdgActv "ENM";
BA_ "SignalLongName" SG_ 45 SrrndVsnRcrdrRcrdgActv "Surround Vision Recorder Recording Active";
BA_ "SignalType" SG_ 45 SVRCBA_PgUpActv "ENM";
BA_ "SignalLongName" SG_ 45 SVRCBA_PgUpActv "Surround Vision Recorder Control Button Availability : Page Up Active";
BA_ "SignalType" SG_ 45 SVRCBA_PgDnActv "ENM";
BA_ "SignalLongName" SG_ 45 SVRCBA_PgDnActv "Surround Vision Recorder Control Button Availability : Page Down Active";
BA_ "SignalLongName" SG_ 606 PrplDispBatTrq "Propulsion Display Battery Torque";
BA_ "SignalLongName" SG_ 606 PrplDispEngTrq "Propulsion Display Engine Torque";
BA_ "SignalLongName" SG_ 606 PrplDispTotTrq "Propulsion Display Total Torque";
BA_ "SignalType" SG_ 1300 RmtRflshDispActvnReq "ENM";
BA_ "SignalLongName" SG_ 1300 RmtRflshDispActvnReq "Remote Reflash Display Activation Request";
BA_ "SignalType" SG_ 1300 RmtRflshCmpgnAval "ENM";
BA_ "SignalLongName" SG_ 1300 RmtRflshCmpgnAval "Remote Reflash Campaign Available";
BA_ "SignalType" SG_ 1300 RdcBrkgToAvoidOvrhtgIndOn "ENM";
BA_ "SignalLongName" SG_ 1300 RdcBrkgToAvoidOvrhtgIndOn "Reduce Braking To Avoid Overheating Indication On";
BA_ "SignalType" SG_ 1300 HiVltgSysDsbld "ENM";
BA_ "SignalLongName" SG_ 1300 HiVltgSysDsbld "High Voltage System Disabled";
BA_ "SignalType" SG_ 1300 FuelFiltChgNowIndOn "ENM";
BA_ "SignalLongName" SG_ 1300 FuelFiltChgNowIndOn "Fuel Filter Change Now Indication On";
BA_ "SignalType" SG_ 1300 ElecAllWhlDrvIndOn "ENM";
BA_ "SignalLongName" SG_ 1300 ElecAllWhlDrvIndOn "Electric All Wheel Drive Indication On";
BA_ "SignalType" SG_ 1300 DM8Denied "ENM";
BA_ "SignalLongName" SG_ 1300 DM8Denied "Drive Mode 8 Denied";
BA_ "SignalType" SG_ 1300 DM7Denied "ENM";
BA_ "SignalLongName" SG_ 1300 DM7Denied "Drive Mode 7 Denied";
BA_ "SignalType" SG_ 1300 TrnspModeInactiveIndOn "ENM";
BA_ "SignalLongName" SG_ 1300 TrnspModeInactiveIndOn "Transport Mode Inactive Indication On";
BA_ "SignalType" SG_ 1300 TrnspModeActvIndOn "ENM";
BA_ "SignalLongName" SG_ 1300 TrnspModeActvIndOn "Transport Mode Active Indication On";
BA_ "SignalLongName" SG_ 1300 FPCMHSR_HptcStReqPuls "Front Pedestrian Collision Mitigation Haptic Seat Request : Haptic Seat Request Pulses";
BA_ "SignalLongName" SG_ 1300 LDWCLHSHSR_HptcStReqPuls "Lane Detection Warning and Control Left Hand Side Haptic Seat Request : Haptic Seat Request Pulses";
BA_ "SignalLongName" SG_ 1300 RCMHSR_HptcStReqPuls "Rear Collision Mitigation Haptic Seat Request : Haptic Seat Request Pulses";
BA_ "SignalLongName" SG_ 1300 LDWCRHSHSR_HptcStReqPuls "Lane Detection Warning and Control Right Hand Side Haptic Seat Request : Haptic Seat Request Pulses";
BA_ "SignalType" SG_ 1300 BrkTempStsIndReq "ENM";
BA_ "SignalLongName" SG_ 1300 BrkTempStsIndReq "Brakes Temperature Status Indication Request";
BA_ "SignalType" SG_ 1301 VwgVwprtSts "ENM";
BA_ "SignalLongName" SG_ 1301 VwgVwprtSts "Viewing Viewport Status";
BA_ "SignalType" SG_ 1301 VwgVwprtReq "ENM";
BA_ "SignalLongName" SG_ 1301 VwgVwprtReq "Viewing Viewport Request";
BA_ "SignalLongName" SG_ 1301 DrvEffInd "Drive Efficiency Indication";
BA_ "SignalType" SG_ 1301 StBltShfIntlkCstCurrSetVal "ENM";
BA_ "SignalLongName" SG_ 1301 StBltShfIntlkCstCurrSetVal "Seat Belt Shift Interlock Customization Current Setting Value";
BA_ "SignalType" SG_ 1301 TnDrvStBltShfIntlkCstSetAval "ENM";
BA_ "SignalLongName" SG_ 1301 TnDrvStBltShfIntlkCstSetAval "Teen Driver Seat Belt Shift Interlock Customization Setting Available";
BA_ "SignalType" SG_ 1301 TnDrvStBltShfIntlkCstCurrSetVal "ENM";
BA_ "SignalLongName" SG_ 1301 TnDrvStBltShfIntlkCstCurrSetVal "Teen Driver Seat Belt Shift Interlock Customization Current Setting Value";
BA_ "SignalType" SG_ 1301 LvlgSysEntEgrsMdCstCurrSetVal "ENM";
BA_ "SignalLongName" SG_ 1301 LvlgSysEntEgrsMdCstCurrSetVal "Leveling System Entry Egress Mode Customization Current Setting Value";
BA_ "SignalType" SG_ 1301 LvlgSysAlgnMdCstCurrSetVal "ENM";
BA_ "SignalLongName" SG_ 1301 LvlgSysAlgnMdCstCurrSetVal "Leveling System Alignment Mode Customization Current Setting Value";
BA_ "SignalType" SG_ 1301 StBltShfIntlkCstSetAval "ENM";
BA_ "SignalLongName" SG_ 1301 StBltShfIntlkCstSetAval "Seat Belt Shift Interlock Customization Setting Available";
BA_ "SignalType" SG_ 1301 RideHghtSeltn2Name "ENM";
BA_ "SignalLongName" SG_ 1301 RideHghtSeltn2Name "Ride Height Selection 2 Name";
BA_ "SignalType" SG_ 1301 RideHghtSeltn1Name "ENM";
BA_ "SignalLongName" SG_ 1301 RideHghtSeltn1Name "Ride Height Selection 1 Name";
BA_ "SignalType" SG_ 1301 LvlgSysServMdCstCurrSetVal "ENM";
BA_ "SignalLongName" SG_ 1301 LvlgSysServMdCstCurrSetVal "Leveling System Service Mode Customization Current Setting Value";
BA_ "SignalType" SG_ 1301 LvlgSysAlgnMdCstSetAval "ENM";
BA_ "SignalLongName" SG_ 1301 LvlgSysAlgnMdCstSetAval "Leveling System Alignment Mode Customization Setting Available";
BA_ "SignalType" SG_ 1301 RideHghtSeltn4Name "ENM";
BA_ "SignalLongName" SG_ 1301 RideHghtSeltn4Name "Ride Height Selection 4 Name";
BA_ "SignalType" SG_ 1301 RideHghtSeltn3Name "ENM";
BA_ "SignalLongName" SG_ 1301 RideHghtSeltn3Name "Ride Height Selection 3 Name";
BA_ "SignalLongName" SG_ 140 RdLdNomAxlTrq "Road Load Nominal Axle Torque";
BA_ "SignalLongName" SG_ 1289 DrvCycBatEngyRegntd "Drive Cycle Battery Energy Regenerated";
BA_ "SignalLongName" SG_ 1289 DrvCycFuelAvdd "Drive Cycle Fuel Avoided";
BA_ "SignalLongName" SG_ 1289 EAWDMPTR_Mins "Electric All Wheel Drive Maximum Power Time Remaining : Minutes";
BA_ "SignalLongName" SG_ 1289 EAWDMPTR_Secs "Electric All Wheel Drive Maximum Power Time Remaining : Seconds";
BA_ "SignalLongName" SG_ 1289 ElecMtrATach "Electric Motor A Tachometer";
BA_ "SignalLongName" SG_ 1289 BatSvrMdSevLvl "Battery Saver Mode Severity Level";
BA_ "SignalType" SG_ 1289 StBltShfIntlkCstAvlFlg3 "ENM";
BA_ "SignalLongName" SG_ 1289 StBltShfIntlkCstAvlFlg3 "Seat Belt Shift Interlock Customization Availability Flag3";
BA_ "SignalType" SG_ 1289 StBltShfIntlkCstAvlFlg2 "ENM";
BA_ "SignalLongName" SG_ 1289 StBltShfIntlkCstAvlFlg2 "Seat Belt Shift Interlock Customization Availability Flag2";
BA_ "SignalType" SG_ 1289 StBltShfIntlkCstAvlFlg1 "ENM";
BA_ "SignalLongName" SG_ 1289 StBltShfIntlkCstAvlFlg1 "Seat Belt Shift Interlock Customization Availability Flag1";
BA_ "SignalType" SG_ 1289 TnDrvStBltShfIntlkCstAvlFlg7 "ENM";
BA_ "SignalLongName" SG_ 1289 TnDrvStBltShfIntlkCstAvlFlg7 "Teen Driver Seat Belt Shift Interlock Customization Availability Flag7";
BA_ "SignalType" SG_ 1289 TnDrvStBltShfIntlkCstAvlFlg6 "ENM";
BA_ "SignalLongName" SG_ 1289 TnDrvStBltShfIntlkCstAvlFlg6 "Teen Driver Seat Belt Shift Interlock Customization Availability Flag6";
BA_ "SignalType" SG_ 1289 TnDrvStBltShfIntlkCstAvlFlg5 "ENM";
BA_ "SignalLongName" SG_ 1289 TnDrvStBltShfIntlkCstAvlFlg5 "Teen Driver Seat Belt Shift Interlock Customization Availability Flag5";
BA_ "SignalLongName" SG_ 1298 RPCMHSR_HptcStReqPuls "Rear Pedestrian Collision Mitigation Haptic Seat Request : Haptic Seat Request Pulses";
BA_ "SignalLongName" SG_ 1298 RCTALSHSR_HptcStReqPuls "Rear Cross Traffic Alert Left Side Haptic Seat Request : Haptic Seat Request Pulses";
BA_ "SignalType" SG_ 1298 HybModeDisp "ENM";
BA_ "SignalLongName" SG_ 1298 HybModeDisp "Hybrid Mode Display";
BA_ "SignalType" SG_ 1298 RrClsrLckSts "ENM";
BA_ "SignalLongName" SG_ 1298 RrClsrLckSts "Rear Closure Lock Status";
BA_ "SignalType" SG_ 1298 RdHgtActvnIndReq "ENM";
BA_ "SignalLongName" SG_ 1298 RdHgtActvnIndReq "Ride Height Activation Indication Request";
BA_ "SignalType" SG_ 1298 HybModeDispVehCfg "ENM";
BA_ "SignalLongName" SG_ 1298 HybModeDispVehCfg "Hybrid Mode Display Vehicle Configuration";
BA_ "SignalLongName" SG_ 1298 RCTARSHSR_HptcStReqPuls "Rear Cross Traffic Alert Right Side Haptic Seat Request : Rear Cross Traffic Alert Right Side Haptic Seat Request Pulses";
BA_ "SignalType" SG_ 1298 WhlSlpSt "ENM";
BA_ "SignalLongName" SG_ 1298 WhlSlpSt "Wheel Slip Status";
BA_ "SignalType" SG_ 1298 SBZALCAVisIndStatRt "ENM";
BA_ "SignalLongName" SG_ 1298 SBZALCAVisIndStatRt "SBZA - LCA Visual Indication State Right";
BA_ "SignalType" SG_ 1298 SBZALCAVisIndStatLt "ENM";
BA_ "SignalLongName" SG_ 1298 SBZALCAVisIndStatLt "SBZA - LCA Visual Indication State Left";
BA_ "SignalType" SG_ 1298 FrFgLmpIO "ENM";
BA_ "SignalLongName" SG_ 1298 FrFgLmpIO "Front Fog Lamp Indication On";
BA_ "SignalType" SG_ 1298 ShftrUnlckdBrktoShfIndOn "ENM";
BA_ "SignalLongName" SG_ 1298 ShftrUnlckdBrktoShfIndOn "Shifter Unlocked Brake to Shift Indication On";
BA_ "SignalType" SG_ 1298 ShftrLckdBcklPsngrStBltIndOn "ENM";
BA_ "SignalLongName" SG_ 1298 ShftrLckdBcklPsngrStBltIndOn "Shifter Locked Buckle Passenger Seatbelt Indication On";
BA_ "SignalType" SG_ 1298 ShftrLckdBcklDrvrStBltIndOn "ENM";
BA_ "SignalLongName" SG_ 1298 ShftrLckdBcklDrvrStBltIndOn "Shifter Locked Buckle Driver Seatbelt Indication On";
BA_ "SignalType" SG_ 1298 FuelSysNEmsRltMlfActv "ENM";
BA_ "SignalLongName" SG_ 1298 FuelSysNEmsRltMlfActv "Fuel System Non Emissions Related Malfunction Active";
BA_ "SignalType" SG_ 1298 DCCnvStblznErrIndOn "ENM";
BA_ "SignalLongName" SG_ 1298 DCCnvStblznErrIndOn "DCDC Converter Stabilization Error Indication On";
BA_ "SignalLongName" SG_ 1298 ACCSpdLimSgnVal "Adaptive Cruise Control Speed Limit Sign Value";
BA_ "SignalType" SG_ 1298 NtVsnVidBrghtnsSts "ENM";
BA_ "SignalLongName" SG_ 1298 NtVsnVidBrghtnsSts "Night Vision Video Brightness Status";
BA_ "SignalType" SG_ 1298 AnmlWrnIndReq "ENM";
BA_ "SignalLongName" SG_ 1298 AnmlWrnIndReq "Animal Warning Indication Request";
BA_ "SignalType" SG_ 1298 RrFgLmpIO "ENM";
BA_ "SignalLongName" SG_ 1298 RrFgLmpIO "Rear Fog Lamp Indication On";
BA_ "SignalLongName" SG_ 1298 SpdLmtrSpdLimSgnVal "Speed Limiter Speed Limit Sign Value";
BA_ "SignalType" SG_ 1298 IdlRecmndToClEngIO "ENM";
BA_ "SignalLongName" SG_ 1298 IdlRecmndToClEngIO "Idle Recommended To Cool Engine Indication On";
BA_ "SignalType" SG_ 1298 ACCSpdLimSgnUnt "ENM";
BA_ "SignalLongName" SG_ 1298 ACCSpdLimSgnUnt "Adaptive Cruise Control Speed Limit Sign Unit";
BA_ "SignalLongName" SG_ 1106 MCMTR_Mins "Maximum Charge Mode Time Remaining : Minutes";
BA_ "SignalType" SG_ 1106 StBltShfIntlkCstAvlFlg7 "ENM";
BA_ "SignalLongName" SG_ 1106 StBltShfIntlkCstAvlFlg7 "Seat Belt Shift Interlock Customization Availability Flag7";
BA_ "SignalType" SG_ 1106 StBltShfIntlkCstAvlFlg6 "ENM";
BA_ "SignalLongName" SG_ 1106 StBltShfIntlkCstAvlFlg6 "Seat Belt Shift Interlock Customization Availability Flag6";
BA_ "SignalType" SG_ 1106 StBltShfIntlkCstAvlFlg5 "ENM";
BA_ "SignalLongName" SG_ 1106 StBltShfIntlkCstAvlFlg5 "Seat Belt Shift Interlock Customization Availability Flag5";
BA_ "SignalType" SG_ 1106 StBltShfIntlkCstAvlFlg4 "ENM";
BA_ "SignalLongName" SG_ 1106 StBltShfIntlkCstAvlFlg4 "Seat Belt Shift Interlock Customization Availability Flag4";
BA_ "SignalLongName" SG_ 1106 MCMTR_Secs "Maximum Charge Mode Time Remaining : Seconds";
BA_ "SignalLongName" SG_ 1106 ElecMtrARotrTemp "Electric Motor A Rotor Temperature";
BA_ "SignalType" SG_ 1106 ElecMtrARotrTemp_Inv "ENM";
BA_ "SignalLongName" SG_ 1106 ElecMtrARotrTemp_Inv "Electric Motor A Rotor Temperature Invalid";
BA_ "SignalLongName" SG_ 1106 ElecMtrASttrTemp "Electric Motor A Stator Temperature";
BA_ "SignalType" SG_ 1106 ElecMtrASttrTemp_Inv "ENM";
BA_ "SignalLongName" SG_ 1106 ElecMtrASttrTemp_Inv "Electric Motor A Stator Temperature Invalid";
BA_ "SignalLongName" SG_ 1106 RideHghtSpdRstrctnDispVal "Ride Height Speed Restriction Display Value";
BA_ "SignalType" SG_ 1106 LvlgSysAlgnMdCstAvlFlg5 "ENM";
BA_ "SignalLongName" SG_ 1106 LvlgSysAlgnMdCstAvlFlg5 "Leveling System Alignment Mode Customization Availability Flag 5";
BA_ "SignalType" SG_ 1106 LvlgSysAlgnMdCstAvlFlg4 "ENM";
BA_ "SignalLongName" SG_ 1106 LvlgSysAlgnMdCstAvlFlg4 "Leveling System Alignment Mode Customization Availability Flag 4";
BA_ "SignalType" SG_ 1106 LvlgSysAlgnMdCstAvlFlg3 "ENM";
BA_ "SignalLongName" SG_ 1106 LvlgSysAlgnMdCstAvlFlg3 "Leveling System Alignment Mode Customization Availability Flag 3";
BA_ "SignalType" SG_ 1106 LvlgSysAlgnMdCstAvlFlg2 "ENM";
BA_ "SignalLongName" SG_ 1106 LvlgSysAlgnMdCstAvlFlg2 "Leveling System Alignment Mode Customization Availability Flag 2";
BA_ "SignalType" SG_ 1106 LvlgSysAlgnMdCstAvlFlg1 "ENM";
BA_ "SignalLongName" SG_ 1106 LvlgSysAlgnMdCstAvlFlg1 "Leveling System Alignment Mode Customization Availability Flag 1";
BA_ "SignalType" SG_ 1386 SecAxlTransStatAchvd_Inv "ENM";
BA_ "SignalLongName" SG_ 1386 SecAxlTransStatAchvd_Inv "Secondary Axle Transmission State Achieved Invalid";
BA_ "SignalType" SG_ 1386 NtVsnVidCntrstSts "ENM";
BA_ "SignalLongName" SG_ 1386 NtVsnVidCntrstSts "Night Vision Video Contrast Status";
BA_ "SignalType" SG_ 1386 NtVsnFncSts "ENM";
BA_ "SignalLongName" SG_ 1386 NtVsnFncSts "Night Vision Function Status";
BA_ "SignalType" SG_ 1386 HzrdReqActv "ENM";
BA_ "SignalLongName" SG_ 1386 HzrdReqActv "Hazard Request Active";
BA_ "SignalType" SG_ 1386 AllWhlDrvRcmndIndOn "ENM";
BA_ "SignalLongName" SG_ 1386 AllWhlDrvRcmndIndOn "All Wheel Drive Recommended Indication On";
BA_ "SignalType" SG_ 1386 ElecShfLckdBcklPsngrStBltIndOn "ENM";
BA_ "SignalLongName" SG_ 1386 ElecShfLckdBcklPsngrStBltIndOn "Electronic Shift Locked Buckle Passenger Seatbelt Indication On";
BA_ "SignalType" SG_ 1386 ElecShfLckdBcklDrvrStBltIndOn "ENM";
BA_ "SignalLongName" SG_ 1386 ElecShfLckdBcklDrvrStBltIndOn "Electronic Shift Locked Buckle Driver Seatbelt Indication On";
BA_ "SignalType" SG_ 1386 TrlrBrkgSysProfSts "ENM";
BA_ "SignalLongName" SG_ 1386 TrlrBrkgSysProfSts "Trailer Braking System Profile Status";
BA_ "SignalType" SG_ 1386 TrlrBrkCnctdIndOn "ENM";
BA_ "SignalLongName" SG_ 1386 TrlrBrkCnctdIndOn "Trailer Brakes Connected Indication On";
BA_ "SignalType" SG_ 1386 SecAxlTransStatAchvd "ENM";
BA_ "SignalLongName" SG_ 1386 SecAxlTransStatAchvd "Secondary Axle Transmission State Achieved";
BA_ "SignalType" SG_ 1386 RmtPRNDLDispFltIndOn "ENM";
BA_ "SignalLongName" SG_ 1386 RmtPRNDLDispFltIndOn "Remote PRNDL Display Fault Indication On";
BA_ "SignalType" SG_ 1386 NoKeyFndTryAgnIndOn "ENM";
BA_ "SignalLongName" SG_ 1386 NoKeyFndTryAgnIndOn "No Key Found Try Again Indication On";
BA_ "SignalType" SG_ 1386 NoKeyDtdElecShfDndIndOn "ENM";
BA_ "SignalLongName" SG_ 1386 NoKeyDtdElecShfDndIndOn "No Key Detected Electronic Shift Denied Indication On";
BA_ "SignalType" SG_ 1386 KeyMisgCkForKeyIndOn "ENM";
BA_ "SignalLongName" SG_ 1386 KeyMisgCkForKeyIndOn "Key Missing Check for Key Indication On";
BA_ "SignalType" SG_ 1386 PrtctdIdlUnvIndOn "ENM";
BA_ "SignalLongName" SG_ 1386 PrtctdIdlUnvIndOn "Protected Idle Unavailable Indication On";
BA_ "SignalType" SG_ 1386 PrtctdIdlIndOn "ENM";
BA_ "SignalLongName" SG_ 1386 PrtctdIdlIndOn "Protected Idle Indication On";
BA_ "SignalType" SG_ 1386 NoKeyDtdMechShfDndIndOn "ENM";
BA_ "SignalLongName" SG_ 1386 NoKeyDtdMechShfDndIndOn "No Key Detected Mechanical Shift Denied Indication On";
BA_ "SignalType" SG_ 1386 ElecShfUnlckdBrkToShfIndOn "ENM";
BA_ "SignalLongName" SG_ 1386 ElecShfUnlckdBrkToShfIndOn "Electronic Shift Unlocked Brake To Shift Indication On";
BA_ "SignalLongName" SG_ 1386 KMORAI_AllwdTm "Key Missing One Restart Allowed Indication : Allowed Time";
BA_ "SignalType" SG_ 1386 SpdLmtrSpdLimSgnUnt "ENM";
BA_ "SignalLongName" SG_ 1386 SpdLmtrSpdLimSgnUnt "Speed Limiter Speed Limit Sign Unit";
BA_ "SignalLongName" SG_ 1386 InstDrvEff "Instantaneous Drive Efficiency";
BA_ "SignalType" SG_ 1386 KMORAI_IndOn "ENM";
BA_ "SignalLongName" SG_ 1386 KMORAI_IndOn "Key Missing One Restart Allowed Indication : Indication On";
BA_ "SignalType" SG_ 1386 EngRcmndDwnsftIndOn "ENM";
BA_ "SignalLongName" SG_ 1386 EngRcmndDwnsftIndOn "Engine Recommended Downshift Indication On";
BA_ "SignalType" SG_ 1386 ElecShfVehInPrkNeutGrMisusdIO "ENM";
BA_ "SignalLongName" SG_ 1386 ElecShfVehInPrkNeutGrMisusdIO "Electronic Shift Vehicle in Park Neutral Gear Misused Indication On";
BA_ "SignalType" SG_ 1386 ElecShfShfgToPrkNeutGrMisusdIO "ENM";
BA_ "SignalLongName" SG_ 1386 ElecShfShfgToPrkNeutGrMisusdIO "Electronic Shift Shifting to Park Neutral Gear Misused Indication On";
BA_ "SignalType" SG_ 1386 ElecShfSelNeutAgnForCarWshMdIO "ENM";
BA_ "SignalLongName" SG_ 1386 ElecShfSelNeutAgnForCarWshMdIO "Electronic Shift Select Neutral Again For Car Wash Mode Indication On";
BA_ "SignalType" SG_ 1386 ElecShfPrssNeutAgnForNeutIndOn "ENM";
BA_ "SignalLongName" SG_ 1386 ElecShfPrssNeutAgnForNeutIndOn "Electronic Shift Press Neutral Again For Neutral Indication On";
BA_ "SignalType" SG_ 1386 ElecShfCarWshModeOnDoNTowIndOn "ENM";
BA_ "SignalLongName" SG_ 1386 ElecShfCarWshModeOnDoNTowIndOn "Electronic Shift Car Wash Mode On Do Not Tow Indication On";
BA_ "SignalType" SG_ 1386 SGI2P_AirSpnsnRdHghtActlStsAuth "ENM";
BA_ "SignalLongName" SG_ 1386 SGI2P_AirSpnsnRdHghtActlStsAuth "Suspension General Information 2 Protected : Air Suspension Ride Height Actual Status Authenticated";
BA_ "SignalLongName" SG_ 1386 ESCSpdLtdCntdwnVal "Electronic Stability Control Speed Limited Countdown Value";
BA_ "SignalType" SG_ 1386 InvsblTrlrAux2CamConctSts "ENM";
BA_ "SignalLongName" SG_ 1386 InvsblTrlrAux2CamConctSts "Invisible Trailer Aux2 Camera Connection Status";
BA_ "SignalType" SG_ 1386 InvsblTrlrAux1CamConctSts "ENM";
BA_ "SignalLongName" SG_ 1386 InvsblTrlrAux1CamConctSts "Invisible Trailer Aux1 Camera Connection Status";
BA_ "SignalType" SG_ 1386 ESCSpdLtdIndReq "ENM";
BA_ "SignalLongName" SG_ 1386 ESCSpdLtdIndReq "Electronic Stability Control Speed Limited Indication Request";
BA_ "SignalType" SG_ 1387 RideHghtSeltn7Name "ENM";
BA_ "SignalLongName" SG_ 1387 RideHghtSeltn7Name "Ride Height Selection 7 Name";
BA_ "SignalType" SG_ 1387 RideHghtSeltn6Name "ENM";
BA_ "SignalLongName" SG_ 1387 RideHghtSeltn6Name "Ride Height Selection 6 Name";
BA_ "SignalType" SG_ 1387 RideHghtSeltn5Name "ENM";
BA_ "SignalLongName" SG_ 1387 RideHghtSeltn5Name "Ride Height Selection 5 Name";
BA_ "SignalType" SG_ 1387 LvlgSysServMdCstSetSelable "ENM";
BA_ "SignalLongName" SG_ 1387 LvlgSysServMdCstSetSelable "Leveling System Service Mode Customization Setting Selectable";
BA_ "SignalType" SG_ 1387 LvlgSysServMdCstSetAval "ENM";
BA_ "SignalLongName" SG_ 1387 LvlgSysServMdCstSetAval "Leveling System Service Mode Customization Setting Available";
BA_ "SignalType" SG_ 1387 LvlgSysEntEgrsMdCstSetAval "ENM";
BA_ "SignalLongName" SG_ 1387 LvlgSysEntEgrsMdCstSetAval "Leveling System Entry Egress Mode Customization Setting Available";
BA_ "SignalType" SG_ 1387 LvlgSysAlgnMdCstSetSelable "ENM";
BA_ "SignalLongName" SG_ 1387 LvlgSysAlgnMdCstSetSelable "Leveling System Alignment Mode Customization Setting Selectable";
BA_ "SignalType" SG_ 1387 RideHghtSeltn8Name "ENM";
BA_ "SignalLongName" SG_ 1387 RideHghtSeltn8Name "Ride Height Selection 8 Name";
BA_ "SignalType" SG_ 1387 RideHghtSeltn4Unv "ENM";
BA_ "SignalLongName" SG_ 1387 RideHghtSeltn4Unv "Ride Height Selection 4 Unavailable";
BA_ "SignalType" SG_ 1387 RideHghtSeltn4Pndg "ENM";
BA_ "SignalLongName" SG_ 1387 RideHghtSeltn4Pndg "Ride Height Selection 4 Pending";
BA_ "SignalType" SG_ 1387 RideHghtSeltn3Unv "ENM";
BA_ "SignalLongName" SG_ 1387 RideHghtSeltn3Unv "Ride Height Selection 3 Unavailable";
BA_ "SignalType" SG_ 1387 RideHghtSeltn3Pndg "ENM";
BA_ "SignalLongName" SG_ 1387 RideHghtSeltn3Pndg "Ride Height Selection 3 Pending";
BA_ "SignalType" SG_ 1387 RideHghtSeltn2Unv "ENM";
BA_ "SignalLongName" SG_ 1387 RideHghtSeltn2Unv "Ride Height Selection 2 Unavailable";
BA_ "SignalType" SG_ 1387 RideHghtSeltn2Pndg "ENM";
BA_ "SignalLongName" SG_ 1387 RideHghtSeltn2Pndg "Ride Height Selection 2 Pending";
BA_ "SignalType" SG_ 1387 RideHghtSeltn1Unv "ENM";
BA_ "SignalLongName" SG_ 1387 RideHghtSeltn1Unv "Ride Height Selection 1 Unavailable";
BA_ "SignalType" SG_ 1387 RideHghtSeltn1Pndg "ENM";
BA_ "SignalLongName" SG_ 1387 RideHghtSeltn1Pndg "Ride Height Selection 1 Pending";
BA_ "SignalType" SG_ 1387 RideHghtSeltn8Unv "ENM";
BA_ "SignalLongName" SG_ 1387 RideHghtSeltn8Unv "Ride Height Selection 8 Unavailable";
BA_ "SignalType" SG_ 1387 RideHghtSeltn8Pndg "ENM";
BA_ "SignalLongName" SG_ 1387 RideHghtSeltn8Pndg "Ride Height Selection 8 Pending";
BA_ "SignalType" SG_ 1387 RideHghtSeltn7Unv "ENM";
BA_ "SignalLongName" SG_ 1387 RideHghtSeltn7Unv "Ride Height Selection 7 Unavailable";
BA_ "SignalType" SG_ 1387 RideHghtSeltn7Pndg "ENM";
BA_ "SignalLongName" SG_ 1387 RideHghtSeltn7Pndg "Ride Height Selection 7 Pending";
BA_ "SignalType" SG_ 1387 RideHghtSeltn6Unv "ENM";
BA_ "SignalLongName" SG_ 1387 RideHghtSeltn6Unv "Ride Height Selection 6 Unavailable";
BA_ "SignalType" SG_ 1387 RideHghtSeltn6Pndg "ENM";
BA_ "SignalLongName" SG_ 1387 RideHghtSeltn6Pndg "Ride Height Selection 6 Pending";
BA_ "SignalType" SG_ 1387 RideHghtSeltn5Unv "ENM";
BA_ "SignalLongName" SG_ 1387 RideHghtSeltn5Unv "Ride Height Selection 5 Unavailable";
BA_ "SignalType" SG_ 1387 RideHghtSeltn5Pndg "ENM";
BA_ "SignalLongName" SG_ 1387 RideHghtSeltn5Pndg "Ride Height Selection 5 Pending";
BA_ "SignalType" SG_ 1387 IHVSLR_HtdCushBckLvl2 "ENM";
BA_ "SignalLongName" SG_ 1387 IHVSLR_HtdCushBckLvl2 "Indication Heated Vented Seat Left Rear : Heated Cushion and Back Level 2";
BA_ "SignalType" SG_ 1387 IHVSLR_HtdCushBckLvl1 "ENM";
BA_ "SignalLongName" SG_ 1387 IHVSLR_HtdCushBckLvl1 "Indication Heated Vented Seat Left Rear : Heated Cushion and Back Level 1";
BA_ "SignalType" SG_ 1387 IHVSLR_HtdCushBckAuto "ENM";
BA_ "SignalLongName" SG_ 1387 IHVSLR_HtdCushBckAuto "Indication Heated Vented Seat Left Rear : Heated Cushion and Back Auto";
BA_ "SignalType" SG_ 1387 IHVSLR_HtdBckMd "ENM";
BA_ "SignalLongName" SG_ 1387 IHVSLR_HtdBckMd "Indication Heated Vented Seat Left Rear : Heated Back Mode";
BA_ "SignalType" SG_ 1387 IHVSLR_HtdBckLvl3 "ENM";
BA_ "SignalLongName" SG_ 1387 IHVSLR_HtdBckLvl3 "Indication Heated Vented Seat Left Rear : Heated Back Level 3";
BA_ "SignalType" SG_ 1387 IHVSLR_HtdBckLvl2 "ENM";
BA_ "SignalLongName" SG_ 1387 IHVSLR_HtdBckLvl2 "Indication Heated Vented Seat Left Rear : Heated Back Level 2";
BA_ "SignalType" SG_ 1387 IHVSLR_HtdBckLvl1 "ENM";
BA_ "SignalLongName" SG_ 1387 IHVSLR_HtdBckLvl1 "Indication Heated Vented Seat Left Rear : Heated Back Level 1";
BA_ "SignalType" SG_ 1387 IHVSLR_HtdBckAuto "ENM";
BA_ "SignalLongName" SG_ 1387 IHVSLR_HtdBckAuto "Indication Heated Vented Seat Left Rear : Heated Back Auto";
BA_ "SignalType" SG_ 1387 DispSmrtTowVidOn "ENM";
BA_ "SignalLongName" SG_ 1387 DispSmrtTowVidOn "Display Smart Tow Video On";
BA_ "SignalType" SG_ 1387 IHVSLR_VntMd "ENM";
BA_ "SignalLongName" SG_ 1387 IHVSLR_VntMd "Indication Heated Vented Seat Left Rear : Vented Mode";
BA_ "SignalType" SG_ 1387 IHVSLR_VntLvl3 "ENM";
BA_ "SignalLongName" SG_ 1387 IHVSLR_VntLvl3 "Indication Heated Vented Seat Left Rear : Vented Level 3";
BA_ "SignalType" SG_ 1387 IHVSLR_VntLvl2 "ENM";
BA_ "SignalLongName" SG_ 1387 IHVSLR_VntLvl2 "Indication Heated Vented Seat Left Rear : Vented Level 2";
BA_ "SignalType" SG_ 1387 IHVSLR_VntLvl1 "ENM";
BA_ "SignalLongName" SG_ 1387 IHVSLR_VntLvl1 "Indication Heated Vented Seat Left Rear : Vented Level 1";
BA_ "SignalType" SG_ 1387 IHVSLR_VntAuto "ENM";
BA_ "SignalLongName" SG_ 1387 IHVSLR_VntAuto "Indication Heated Vented Seat Left Rear : Vented Auto";
BA_ "SignalType" SG_ 1387 IHVSLR_HtdCushBckMd "ENM";
BA_ "SignalLongName" SG_ 1387 IHVSLR_HtdCushBckMd "Indication Heated Vented Seat Left Rear : Heated Cushion and Back Mode";
BA_ "SignalType" SG_ 1387 IHVSLR_HtdCushBckLvl3 "ENM";
BA_ "SignalLongName" SG_ 1387 IHVSLR_HtdCushBckLvl3 "Indication Heated Vented Seat Left Rear : Heated Cushion and Back Level 3";
BA_ "SignalType" SG_ 1401 LvlgSysEntEgrsMdCstAvlFlg6 "ENM";
BA_ "SignalLongName" SG_ 1401 LvlgSysEntEgrsMdCstAvlFlg6 "Leveling System Entry Egress Mode Customization Availability Flag 6";
BA_ "SignalType" SG_ 1401 LvlgSysEntEgrsMdCstAvlFlg5 "ENM";
BA_ "SignalLongName" SG_ 1401 LvlgSysEntEgrsMdCstAvlFlg5 "Leveling System Entry Egress Mode Customization Availability Flag 5";
BA_ "SignalType" SG_ 1401 LvlgSysEntEgrsMdCstAvlFlg4 "ENM";
BA_ "SignalLongName" SG_ 1401 LvlgSysEntEgrsMdCstAvlFlg4 "Leveling System Entry Egress Mode Customization Availability Flag 4";
BA_ "SignalType" SG_ 1401 LvlgSysEntEgrsMdCstAvlFlg3 "ENM";
BA_ "SignalLongName" SG_ 1401 LvlgSysEntEgrsMdCstAvlFlg3 "Leveling System Entry Egress Mode Customization Availability Flag 3";
BA_ "SignalType" SG_ 1401 LvlgSysEntEgrsMdCstAvlFlg2 "ENM";
BA_ "SignalLongName" SG_ 1401 LvlgSysEntEgrsMdCstAvlFlg2 "Leveling System Entry Egress Mode Customization Availability Flag 2";
BA_ "SignalType" SG_ 1401 LvlgSysEntEgrsMdCstAvlFlg1 "ENM";
BA_ "SignalLongName" SG_ 1401 LvlgSysEntEgrsMdCstAvlFlg1 "Leveling System Entry Egress Mode Customization Availability Flag 1";
BA_ "SignalType" SG_ 1401 LvlgSysAlgnMdCstAvlFlg7 "ENM";
BA_ "SignalLongName" SG_ 1401 LvlgSysAlgnMdCstAvlFlg7 "Leveling System Alignment Mode Customization Availability Flag 7";
BA_ "SignalType" SG_ 1401 LvlgSysAlgnMdCstAvlFlg6 "ENM";
BA_ "SignalLongName" SG_ 1401 LvlgSysAlgnMdCstAvlFlg6 "Leveling System Alignment Mode Customization Availability Flag 6";
BA_ "SignalType" SG_ 1401 LvlgSysServMdCstAvlFlg7 "ENM";
BA_ "SignalLongName" SG_ 1401 LvlgSysServMdCstAvlFlg7 "Leveling System Service Mode Customization Availability Flag 7";
BA_ "SignalType" SG_ 1401 LvlgSysServMdCstAvlFlg6 "ENM";
BA_ "SignalLongName" SG_ 1401 LvlgSysServMdCstAvlFlg6 "Leveling System Service Mode Customization Availability Flag 6";
BA_ "SignalType" SG_ 1401 LvlgSysServMdCstAvlFlg5 "ENM";
BA_ "SignalLongName" SG_ 1401 LvlgSysServMdCstAvlFlg5 "Leveling System Service Mode Customization Availability Flag 5";
BA_ "SignalType" SG_ 1401 LvlgSysServMdCstAvlFlg4 "ENM";
BA_ "SignalLongName" SG_ 1401 LvlgSysServMdCstAvlFlg4 "Leveling System Service Mode Customization Availability Flag 4";
BA_ "SignalType" SG_ 1401 LvlgSysServMdCstAvlFlg3 "ENM";
BA_ "SignalLongName" SG_ 1401 LvlgSysServMdCstAvlFlg3 "Leveling System Service Mode Customization Availability Flag 3";
BA_ "SignalType" SG_ 1401 LvlgSysServMdCstAvlFlg2 "ENM";
BA_ "SignalLongName" SG_ 1401 LvlgSysServMdCstAvlFlg2 "Leveling System Service Mode Customization Availability Flag 2";
BA_ "SignalType" SG_ 1401 LvlgSysServMdCstAvlFlg1 "ENM";
BA_ "SignalLongName" SG_ 1401 LvlgSysServMdCstAvlFlg1 "Leveling System Service Mode Customization Availability Flag 1";
BA_ "SignalType" SG_ 1401 LvlgSysEntEgrsMdCstAvlFlg7 "ENM";
BA_ "SignalLongName" SG_ 1401 LvlgSysEntEgrsMdCstAvlFlg7 "Leveling System Entry Egress Mode Customization Availability Flag 7";
BA_ "SignalLongName" SG_ 1401 BattCrntFltrd "Battery Current Filtered";
BA_ "SignalType" SG_ 1401 VehMassEstSts "ENM";
BA_ "SignalLongName" SG_ 1401 VehMassEstSts "Vehicle Mass Estimate Status";
BA_ "SignalType" SG_ 1401 TmngBltChgIndOn "ENM";
BA_ "SignalLongName" SG_ 1401 TmngBltChgIndOn "Timing Belt Change Indication On";
BA_ "SignalType" SG_ 1401 FuelConsmpHvyIndReq "ENM";
BA_ "SignalLongName" SG_ 1401 FuelConsmpHvyIndReq "Fuel Consumption Heavy Indication Request";
BA_ "SignalType" SG_ 1043 IHVSRR_HtdCushBckLvl2 "ENM";
BA_ "SignalLongName" SG_ 1043 IHVSRR_HtdCushBckLvl2 "Indication Heated Vented Seat Right Rear : Heated Cushion and Back Level 2";
BA_ "SignalType" SG_ 1043 IHVSRR_HtdCushBckLvl1 "ENM";
BA_ "SignalLongName" SG_ 1043 IHVSRR_HtdCushBckLvl1 "Indication Heated Vented Seat Right Rear : Heated Cushion and Back Level 1";
BA_ "SignalType" SG_ 1043 IHVSRR_HtdCushBckAuto "ENM";
BA_ "SignalLongName" SG_ 1043 IHVSRR_HtdCushBckAuto "Indication Heated Vented Seat Right Rear : Heated Cushion and Back Auto";
BA_ "SignalType" SG_ 1043 IHVSRR_HtdBckMd "ENM";
BA_ "SignalLongName" SG_ 1043 IHVSRR_HtdBckMd "Indication Heated Vented Seat Right Rear : Heated Back Mode";
BA_ "SignalType" SG_ 1043 IHVSRR_HtdBckLvl3 "ENM";
BA_ "SignalLongName" SG_ 1043 IHVSRR_HtdBckLvl3 "Indication Heated Vented Seat Right Rear : Heated Back Level 3";
BA_ "SignalType" SG_ 1043 IHVSRR_HtdBckLvl2 "ENM";
BA_ "SignalLongName" SG_ 1043 IHVSRR_HtdBckLvl2 "Indication Heated Vented Seat Right Rear : Heated Back Level 2";
BA_ "SignalType" SG_ 1043 IHVSRR_HtdBckLvl1 "ENM";
BA_ "SignalLongName" SG_ 1043 IHVSRR_HtdBckLvl1 "Indication Heated Vented Seat Right Rear : Heated Back Level 1";
BA_ "SignalType" SG_ 1043 IHVSRR_HtdBckAuto "ENM";
BA_ "SignalLongName" SG_ 1043 IHVSRR_HtdBckAuto "Indication Heated Vented Seat Right Rear : Heated Back Auto";
BA_ "SignalType" SG_ 1043 IHVSRR_VntMd "ENM";
BA_ "SignalLongName" SG_ 1043 IHVSRR_VntMd "Indication Heated Vented Seat Right Rear : Vented Mode";
BA_ "SignalType" SG_ 1043 IHVSRR_VntLvl3 "ENM";
BA_ "SignalLongName" SG_ 1043 IHVSRR_VntLvl3 "Indication Heated Vented Seat Right Rear : Vented Level 3";
BA_ "SignalType" SG_ 1043 IHVSRR_VntLvl2 "ENM";
BA_ "SignalLongName" SG_ 1043 IHVSRR_VntLvl2 "Indication Heated Vented Seat Right Rear : Vented Level 2";
BA_ "SignalType" SG_ 1043 IHVSRR_VntLvl1 "ENM";
BA_ "SignalLongName" SG_ 1043 IHVSRR_VntLvl1 "Indication Heated Vented Seat Right Rear : Vented Level 1";
BA_ "SignalType" SG_ 1043 IHVSRR_VntAuto "ENM";
BA_ "SignalLongName" SG_ 1043 IHVSRR_VntAuto "Indication Heated Vented Seat Right Rear : Vented Auto";
BA_ "SignalType" SG_ 1043 IHVSRR_HtdCushBckMd "ENM";
BA_ "SignalLongName" SG_ 1043 IHVSRR_HtdCushBckMd "Indication Heated Vented Seat Right Rear : Heated Cushion and Back Mode";
BA_ "SignalType" SG_ 1043 IHVSRR_HtdCushBckLvl3 "ENM";
BA_ "SignalLongName" SG_ 1043 IHVSRR_HtdCushBckLvl3 "Indication Heated Vented Seat Right Rear : Heated Cushion and Back Level 3";
BA_ "SignalLongName" SG_ 1125 VehMassEst "Vehicle Mass Estimate";
BA_ "SignalType" SG_ 1414 MemStorCmpltdIndReq "ENM";
BA_ "SignalLongName" SG_ 1414 MemStorCmpltdIndReq "Memory Store Completed Indication Request";
BA_ "SignalType" SG_ 1414 MemRclHldUntilCmpltIndReq "ENM";
BA_ "SignalLongName" SG_ 1414 MemRclHldUntilCmpltIndReq "Memory Recall Hold Until Complete Indication Request";
BA_ "SignalType" SG_ 1414 TrlrArtclnAngCalSts "ENM";
BA_ "SignalLongName" SG_ 1414 TrlrArtclnAngCalSts "Trailer Articulation Angle Calibration Status";
BA_ "SignalType" SG_ 1414 PrkAsstActIndCmnd "ENM";
BA_ "SignalLongName" SG_ 1414 PrkAsstActIndCmnd "Park Assist Active Indication Command";
BA_ "SignalType" SG_ 1414 InrTlgtOpnIndOn "ENM";
BA_ "SignalLongName" SG_ 1414 InrTlgtOpnIndOn "Inner Tailgate Open Indication On";
BA_ "SignalType" SG_ 1414 PPVehRadioMutReq "ENM";
BA_ "SignalLongName" SG_ 1414 PPVehRadioMutReq "Police Pursuit Vehicle Radio Mute Request";
BA_ "SignalType" SG_ 1414 RrStrgFlrIndOn "ENM";
BA_ "SignalLongName" SG_ 1414 RrStrgFlrIndOn "Rear Steering Failure Indication On";
BA_ "SignalType" SG_ 1414 MemStorTmdOutIndOn "ENM";
BA_ "SignalLongName" SG_ 1414 MemStorTmdOutIndOn "Memory Store Timed Out Indication On";
BA_ "SignalType" SG_ 1414 MemStorPrssSetFrstIndOn "ENM";
BA_ "SignalLongName" SG_ 1414 MemStorPrssSetFrstIndOn "Memory Store Press Set First Indication On";
BA_ "SignalType" SG_ 1414 MemSeeAutoRclSetsIndOn "ENM";
BA_ "SignalLongName" SG_ 1414 MemSeeAutoRclSetsIndOn "Memory See Auto Recall Settings Indication On";
BA_ "SignalType" SG_ 1414 OffRdMdDrvlnVisDispVal "ENM";
BA_ "SignalLongName" SG_ 1414 OffRdMdDrvlnVisDispVal "Off Road Mode Driveline Visualization Display Value";
BA_ "SignalType" SG_ 1414 OffRdMdBrkPedVisDispVal "ENM";
BA_ "SignalLongName" SG_ 1414 OffRdMdBrkPedVisDispVal "Off Road Mode Brake Pedal Visualization Display Value";
BA_ "SignalType" SG_ 1414 OffRdMdActvAerodynsVisDispVal "ENM";
BA_ "SignalLongName" SG_ 1414 OffRdMdActvAerodynsVisDispVal "Off Road Mode Active Aerodynamics Visualization Display Value";
BA_ "SignalType" SG_ 1414 OffRdMdSpnsnVisDispVal "ENM";
BA_ "SignalLongName" SG_ 1414 OffRdMdSpnsnVisDispVal "Off Road Mode Suspension Visualization Display Value";
BA_ "SignalType" SG_ 1414 OffRdMdPwrtrnVisDispVal "ENM";
BA_ "SignalLongName" SG_ 1414 OffRdMdPwrtrnVisDispVal "Off Road Mode Powertrain Visualization Display Value";
BA_ "SignalType" SG_ 1414 OffRdMdESCVisDispVal "ENM";
BA_ "SignalLongName" SG_ 1414 OffRdMdESCVisDispVal "Off Road Mode ESC Visualization Display Value";
BA_ "SignalType" SG_ 1414 OffRdMdRideHghtVisDispVal "ENM";
BA_ "SignalLongName" SG_ 1414 OffRdMdRideHghtVisDispVal "Off Road Mode Ride Height Visualization Display Value";
BA_ "SignalType" SG_ 1414 OffRdMdStrgVisDispVal "ENM";
BA_ "SignalLongName" SG_ 1414 OffRdMdStrgVisDispVal "Off Road Mode Steering Visualization Display Value";
BA_ "SignalType" SG_ 1414 PTOEngRunTmrCstAvlFlg11 "ENM";
BA_ "SignalLongName" SG_ 1414 PTOEngRunTmrCstAvlFlg11 "Power Take Off Engine Run Timer Customization Availability Flag 11";
BA_ "SignalType" SG_ 1414 PTOEngRunTmrCstAvlFlg10 "ENM";
BA_ "SignalLongName" SG_ 1414 PTOEngRunTmrCstAvlFlg10 "Power Take Off Engine Run Timer Customization Availability Flag 10";
BA_ "SignalType" SG_ 1414 BrkSysTwoFtdDrvDtdIndOn "ENM";
BA_ "SignalLongName" SG_ 1414 BrkSysTwoFtdDrvDtdIndOn "Brake System Two Footed Driving Detected Indication On";
BA_ "SignalType" SG_ 1414 RrCrsTrfcAutoBrkgOffIndOn "ENM";
BA_ "SignalLongName" SG_ 1414 RrCrsTrfcAutoBrkgOffIndOn "Rear Cross Traffic Auto Braking Off Indication On";
BA_ "SignalType" SG_ 1414 ACCTrlrGapSetIndOn "ENM";
BA_ "SignalLongName" SG_ 1414 ACCTrlrGapSetIndOn "Adaptive Cruise Control Trailer Gap Setting Indication On";
BA_ "SignalType" SG_ 1414 OffRdMdSndVisDispVal "ENM";
BA_ "SignalLongName" SG_ 1414 OffRdMdSndVisDispVal "Off Road Mode Sound Visualization Display Value";
BA_ "SignalType" SG_ 1061 TowHaulMdPwrtrnVisDispVal "ENM";
BA_ "SignalLongName" SG_ 1061 TowHaulMdPwrtrnVisDispVal "Tow Haul Mode Powertrain Visualization Display Value";
BA_ "SignalType" SG_ 1061 TowHaulMdESCVisDispVal "ENM";
BA_ "SignalLongName" SG_ 1061 TowHaulMdESCVisDispVal "Tow Haul Mode ESC Visualization Display Value";
BA_ "SignalType" SG_ 1061 TowHaulMdBrkPedVisDispVal "ENM";
BA_ "SignalLongName" SG_ 1061 TowHaulMdBrkPedVisDispVal "Tow Haul Mode Brake Pedal Visualization Display Value";
BA_ "SignalType" SG_ 1061 TowHaulMdActvAerodynsVisDispVal "ENM";
BA_ "SignalLongName" SG_ 1061 TowHaulMdActvAerodynsVisDispVal "Tow Haul Mode Active Aerodynamics Visualization Display Value";
BA_ "SignalType" SG_ 1061 TowHaulMdStrgVisDispVal "ENM";
BA_ "SignalLongName" SG_ 1061 TowHaulMdStrgVisDispVal "Tow Haul Mode Steering Visualization Display Value";
BA_ "SignalType" SG_ 1061 TowHaulMdSpnsnVisDispVal "ENM";
BA_ "SignalLongName" SG_ 1061 TowHaulMdSpnsnVisDispVal "Tow Haul Mode Suspension Visualization Display Value";
BA_ "SignalType" SG_ 1061 TowHaulMdSndVisDispVal "ENM";
BA_ "SignalLongName" SG_ 1061 TowHaulMdSndVisDispVal "Tow Haul Mode Sound Visualization Display Value";
BA_ "SignalType" SG_ 1061 TowHaulMdDrvlnVisDispVal "ENM";
BA_ "SignalLongName" SG_ 1061 TowHaulMdDrvlnVisDispVal "Tow Haul Mode Driveline Visualization Display Value";
BA_ "SignalType" SG_ 1061 RrAxlLckIO "ENM";
BA_ "SignalLongName" SG_ 1061 RrAxlLckIO "Rear Axle Lock Indication On";
BA_ "SignalType" SG_ 1061 FrntAxlLckIO "ENM";
BA_ "SignalLongName" SG_ 1061 FrntAxlLckIO "Front Axle Lock Indication On";
BA_ "SignalType" SG_ 1061 AxlLckUnavailIndReq "ENM";
BA_ "SignalLongName" SG_ 1061 AxlLckUnavailIndReq "Axle Locks Unavailable Indication Request";
BA_ "SignalType" SG_ 1061 TowHaulMdRideHghtVisDispVal "ENM";
BA_ "SignalLongName" SG_ 1061 TowHaulMdRideHghtVisDispVal "Tow Haul Mode Ride Height Visualization Display Value";
BA_ "SignalLongName" SG_ 1061 TirePrsLRInr "Tire Pressure Left Rear Inner Information : Tire Pressure Left Rear Inner";
BA_ "SignalType" SG_ 1061 TirePrsLRInr_Inv "ENM";
BA_ "SignalLongName" SG_ 1061 TirePrsLRInr_Inv "Tire Pressure Left Rear Inner Information : Tire Pressure Left Rear Inner Invalid";
BA_ "SignalType" SG_ 1061 AutoTrnspHdActvnCstAvlFlg1 "ENM";
BA_ "SignalLongName" SG_ 1061 AutoTrnspHdActvnCstAvlFlg1 "Automatic Transparent Hood Activation Customization Availability Flag1";
BA_ "SignalType" SG_ 1061 TirePrsStatLRInr "ENM";
BA_ "SignalLongName" SG_ 1061 TirePrsStatLRInr "Tire Pressure Left Rear Inner Information : TPMS Status Left Rear Inner";
BA_ "SignalType" SG_ 1061 AutoTrnspHdActvnCstCurrSetVal "ENM";
BA_ "SignalLongName" SG_ 1061 AutoTrnspHdActvnCstCurrSetVal "Automatic Transparent Hood Activation Customization Current Setting Value";
BA_ "SignalLongName" SG_ 1087 ACCTOSHiThrtLicVehTmToClsn10 "Adaptive Cruise Control Target Object Selection High Threat Licensable Vehicle Time to Collision 10";
BA_ "SignalLongName" SG_ 1087 ACCTOSHiThrtLicVehTmToClsn2 "Adaptive Cruise Control Target Object Selection High Threat Licensable Vehicle Time to Collision 2";
BA_ "SignalLongName" SG_ 1087 ACCTOSHiThrtLicVehTmToClsn3 "Adaptive Cruise Control Target Object Selection High Threat Licensable Vehicle Time to Collision 3";
BA_ "SignalLongName" SG_ 1087 ACCTOSHiThrtLicVehTmToClsn4 "Adaptive Cruise Control Target Object Selection High Threat Licensable Vehicle Time to Collision 4";
BA_ "SignalLongName" SG_ 1088 ACCTOSHiThrtLicVehTmToClsn5 "Adaptive Cruise Control Target Object Selection High Threat Licensable Vehicle Time to Collision 5";
BA_ "SignalLongName" SG_ 1088 ACCTOSHiThrtLicVehTmToClsn6 "Adaptive Cruise Control Target Object Selection High Threat Licensable Vehicle Time to Collision 6";
BA_ "SignalLongName" SG_ 1088 ACCTOSHiThrtLicVehTmToClsn7 "Adaptive Cruise Control Target Object Selection High Threat Licensable Vehicle Time to Collision 7";
BA_ "SignalLongName" SG_ 1088 ACCTOSHiThrtLicVehTmToClsn8 "Adaptive Cruise Control Target Object Selection High Threat Licensable Vehicle Time to Collision 8";
BA_ "SignalLongName" SG_ 1115 ACCTOSHiThrtLicVehTmToClsn9 "Adaptive Cruise Control Target Object Selection High Threat Licensable Vehicle Time to Collision 9";
BA_ "SignalLongName" SG_ 1115 LnFllwgTgtTrjctryLnCoef2 "Lane Following Target Trajectory Lane Coefficient 2";
BA_ "SignalLongName" SG_ 1115 LnFllwgTgtTrjctryLnCoef3 "Lane Following Target Trajectory Lane Coefficient 3";
BA_ "SignalLongName" SG_ 1115 LnFllwgTgtTrjctryLnCoef0 "Lane Following Target Trajectory Lane Coefficient 0";
BA_ "SignalLongName" SG_ 1162 LnFllwgTOSHiThrtLicVehLngDist1 "Lane Following Target Object Selection High Threat Licensable Vehicle Longitudinal Distance 1";
BA_ "SignalLongName" SG_ 1162 LnFllwgTOSHiThrtLicVehLngDist2 "Lane Following Target Object Selection High Threat Licensable Vehicle Longitudinal Distance 2";
BA_ "SignalLongName" SG_ 1162 LnFllwgTOSHiThrtLicVehLngDist3 "Lane Following Target Object Selection High Threat Licensable Vehicle Longitudinal Distance 3";
BA_ "SignalLongName" SG_ 1162 LnFllwgTOSHiThrtLicVehLngDist4 "Lane Following Target Object Selection High Threat Licensable Vehicle Longitudinal Distance 4";
BA_ "SignalLongName" SG_ 1162 LnFllwgTOSHiThrtLicVehLngDist5 "Lane Following Target Object Selection High Threat Licensable Vehicle Longitudinal Distance 5";
BA_ "SignalLongName" SG_ 1417 LnFllwgTOSHiThrtLicVehLngDist6 "Lane Following Target Object Selection High Threat Licensable Vehicle Longitudinal Distance 6";
BA_ "SignalLongName" SG_ 1426 TirePrsRRInr "Tire Pressure Right Rear Inner Information : Tire Pressure Right Rear Inner";
BA_ "SignalType" SG_ 1426 TirePrsRRInr_Inv "ENM";
BA_ "SignalLongName" SG_ 1426 TirePrsRRInr_Inv "Tire Pressure Right Rear Inner Information : Tire Pressure Right Rear Inner Invalid";
BA_ "SignalType" SG_ 1426 AutoTrnspHdActvnCstAvlFlg5 "ENM";
BA_ "SignalLongName" SG_ 1426 AutoTrnspHdActvnCstAvlFlg5 "Automatic Transparent Hood Activation Customization Availability Flag5";
BA_ "SignalType" SG_ 1426 AutoTrnspHdActvnCstAvlFlg4 "ENM";
BA_ "SignalLongName" SG_ 1426 AutoTrnspHdActvnCstAvlFlg4 "Automatic Transparent Hood Activation Customization Availability Flag4";
BA_ "SignalType" SG_ 1426 AutoTrnspHdActvnCstAvlFlg3 "ENM";
BA_ "SignalLongName" SG_ 1426 AutoTrnspHdActvnCstAvlFlg3 "Automatic Transparent Hood Activation Customization Availability Flag3";
BA_ "SignalType" SG_ 1426 AutoTrnspHdActvnCstAvlFlg2 "ENM";
BA_ "SignalLongName" SG_ 1426 AutoTrnspHdActvnCstAvlFlg2 "Automatic Transparent Hood Activation Customization Availability Flag2";
BA_ "SignalType" SG_ 1426 TirePrsStatRRInr "ENM";
BA_ "SignalLongName" SG_ 1426 TirePrsStatRRInr "Tire Pressure Right Rear Inner Information : TPMS Status Right Rear Inner";
BA_ "SignalType" SG_ 1426 PTOEngRunTmrCstAvlFlg6 "ENM";
BA_ "SignalLongName" SG_ 1426 PTOEngRunTmrCstAvlFlg6 "Power Take Off Engine Run Timer Customization Availability Flag 6";
BA_ "SignalType" SG_ 1426 PTOEngRunTmrCstAvlFlg5 "ENM";
BA_ "SignalLongName" SG_ 1426 PTOEngRunTmrCstAvlFlg5 "Power Take Off Engine Run Timer Customization Availability Flag 5";
BA_ "SignalType" SG_ 1426 PTOEngRunTmrCstAvlFlg4 "ENM";
BA_ "SignalLongName" SG_ 1426 PTOEngRunTmrCstAvlFlg4 "Power Take Off Engine Run Timer Customization Availability Flag 4";
BA_ "SignalType" SG_ 1426 PTOEngRunTmrCstAvlFlg3 "ENM";
BA_ "SignalLongName" SG_ 1426 PTOEngRunTmrCstAvlFlg3 "Power Take Off Engine Run Timer Customization Availability Flag 3";
BA_ "SignalType" SG_ 1426 AxlLcksServIO "ENM";
BA_ "SignalLongName" SG_ 1426 AxlLcksServIO "Axle Locks Service Indication On";
BA_ "SignalType" SG_ 1426 AutoTrnspHdActvnCstSetAval "ENM";
BA_ "SignalLongName" SG_ 1426 AutoTrnspHdActvnCstSetAval "Automatic Transparent Hood Activation Customization Setting Available";
BA_ "SignalType" SG_ 1426 AutoTrnspHdActvnCstAvlFlg7 "ENM";
BA_ "SignalLongName" SG_ 1426 AutoTrnspHdActvnCstAvlFlg7 "Automatic Transparent Hood Activation Customization Availability Flag7";
BA_ "SignalType" SG_ 1426 AutoTrnspHdActvnCstAvlFlg6 "ENM";
BA_ "SignalLongName" SG_ 1426 AutoTrnspHdActvnCstAvlFlg6 "Automatic Transparent Hood Activation Customization Availability Flag6";
BA_ "SignalType" SG_ 1426 PTOSet1SpdCstAvlFlg1 "ENM";
BA_ "SignalLongName" SG_ 1426 PTOSet1SpdCstAvlFlg1 "Power Take Off Set 1 Speed Customization Availability Flag 1";
BA_ "SignalType" SG_ 1426 PTOModeCstAvlFlg2 "ENM";
BA_ "SignalLongName" SG_ 1426 PTOModeCstAvlFlg2 "Power Take Off Mode Customization Availability Flag 2";
BA_ "SignalType" SG_ 1426 PTOModeCstAvlFlg1 "ENM";
BA_ "SignalLongName" SG_ 1426 PTOModeCstAvlFlg1 "Power Take Off Mode Customization Availability Flag 1";
BA_ "SignalType" SG_ 1426 PTOEngSpdTypCstAvlFlg2 "ENM";
BA_ "SignalLongName" SG_ 1426 PTOEngSpdTypCstAvlFlg2 "Power Take Off Engine Speed Type Customization Availability Flag 2";
BA_ "SignalType" SG_ 1426 PTOEngSpdTypCstAvlFlg1 "ENM";
BA_ "SignalLongName" SG_ 1426 PTOEngSpdTypCstAvlFlg1 "Power Take Off Engine Speed Type Customization Availability Flag 1";
BA_ "SignalType" SG_ 1426 PTOEngRunTmrCstAvlFlg9 "ENM";
BA_ "SignalLongName" SG_ 1426 PTOEngRunTmrCstAvlFlg9 "Power Take Off Engine Run Timer Customization Availability Flag 9";
BA_ "SignalType" SG_ 1426 PTOEngRunTmrCstAvlFlg8 "ENM";
BA_ "SignalLongName" SG_ 1426 PTOEngRunTmrCstAvlFlg8 "Power Take Off Engine Run Timer Customization Availability Flag 8";
BA_ "SignalType" SG_ 1426 PTOEngRunTmrCstAvlFlg7 "ENM";
BA_ "SignalLongName" SG_ 1426 PTOEngRunTmrCstAvlFlg7 "Power Take Off Engine Run Timer Customization Availability Flag 7";
BA_ "SignalType" SG_ 1426 PTOSet1SpdCstAvlFlg3 "ENM";
BA_ "SignalLongName" SG_ 1426 PTOSet1SpdCstAvlFlg3 "Power Take Off Set 1 Speed Customization Availability Flag 3";
BA_ "SignalType" SG_ 1426 PTOSet1SpdCstAvlFlg2 "ENM";
BA_ "SignalLongName" SG_ 1426 PTOSet1SpdCstAvlFlg2 "Power Take Off Set 1 Speed Customization Availability Flag 2";
BA_ "SignalType" SG_ 1426 PTOSet1SpdCstAvlFlg15 "ENM";
BA_ "SignalLongName" SG_ 1426 PTOSet1SpdCstAvlFlg15 "Power Take Off Set 1 Speed Customization Availability Flag 15";
BA_ "SignalType" SG_ 1426 PTOSet1SpdCstAvlFlg14 "ENM";
BA_ "SignalLongName" SG_ 1426 PTOSet1SpdCstAvlFlg14 "Power Take Off Set 1 Speed Customization Availability Flag 14";
BA_ "SignalType" SG_ 1426 PTOSet1SpdCstAvlFlg13 "ENM";
BA_ "SignalLongName" SG_ 1426 PTOSet1SpdCstAvlFlg13 "Power Take Off Set 1 Speed Customization Availability Flag 13";
BA_ "SignalType" SG_ 1426 PTOSet1SpdCstAvlFlg12 "ENM";
BA_ "SignalLongName" SG_ 1426 PTOSet1SpdCstAvlFlg12 "Power Take Off Set 1 Speed Customization Availability Flag 12";
BA_ "SignalType" SG_ 1426 PTOSet1SpdCstAvlFlg11 "ENM";
BA_ "SignalLongName" SG_ 1426 PTOSet1SpdCstAvlFlg11 "Power Take Off Set 1 Speed Customization Availability Flag 11";
BA_ "SignalType" SG_ 1426 PTOSet1SpdCstAvlFlg10 "ENM";
BA_ "SignalLongName" SG_ 1426 PTOSet1SpdCstAvlFlg10 "Power Take Off Set 1 Speed Customization Availability Flag 10";
BA_ "SignalType" SG_ 1426 PTOSet2SpdCstAvlFlg10 "ENM";
BA_ "SignalLongName" SG_ 1426 PTOSet2SpdCstAvlFlg10 "Power Take Off Set 2 Speed Customization Availability Flag 10";
BA_ "SignalType" SG_ 1426 PTOSet2SpdCstAvlFlg1 "ENM";
BA_ "SignalLongName" SG_ 1426 PTOSet2SpdCstAvlFlg1 "Power Take Off Set 2 Speed Customization Availability Flag 1";
BA_ "SignalType" SG_ 1426 PTOSet1SpdCstAvlFlg9 "ENM";
BA_ "SignalLongName" SG_ 1426 PTOSet1SpdCstAvlFlg9 "Power Take Off Set 1 Speed Customization Availability Flag 9";
BA_ "SignalType" SG_ 1426 PTOSet1SpdCstAvlFlg8 "ENM";
BA_ "SignalLongName" SG_ 1426 PTOSet1SpdCstAvlFlg8 "Power Take Off Set 1 Speed Customization Availability Flag 8";
BA_ "SignalType" SG_ 1426 PTOSet1SpdCstAvlFlg7 "ENM";
BA_ "SignalLongName" SG_ 1426 PTOSet1SpdCstAvlFlg7 "Power Take Off Set 1 Speed Customization Availability Flag 7";
BA_ "SignalType" SG_ 1426 PTOSet1SpdCstAvlFlg6 "ENM";
BA_ "SignalLongName" SG_ 1426 PTOSet1SpdCstAvlFlg6 "Power Take Off Set 1 Speed Customization Availability Flag 6";
BA_ "SignalType" SG_ 1426 PTOSet1SpdCstAvlFlg5 "ENM";
BA_ "SignalLongName" SG_ 1426 PTOSet1SpdCstAvlFlg5 "Power Take Off Set 1 Speed Customization Availability Flag 5";
BA_ "SignalType" SG_ 1426 PTOSet1SpdCstAvlFlg4 "ENM";
BA_ "SignalLongName" SG_ 1426 PTOSet1SpdCstAvlFlg4 "Power Take Off Set 1 Speed Customization Availability Flag 4";
BA_ "SignalType" SG_ 1449 PTOPrssAndRelBrkPedIndOn "ENM";
BA_ "SignalLongName" SG_ 1449 PTOPrssAndRelBrkPedIndOn "Power Take Off Press And Release Brake Pedal Indication On";
BA_ "SignalType" SG_ 1449 PTOModeCstSetAval "ENM";
BA_ "SignalLongName" SG_ 1449 PTOModeCstSetAval "Power Take Off Mode Customization Setting Available";
BA_ "SignalType" SG_ 1449 PTOMblModeTransInGrIndOn "ENM";
BA_ "SignalLongName" SG_ 1449 PTOMblModeTransInGrIndOn "Power Take Off Mobile Mode Transmission In Gear Indication On";
BA_ "SignalType" SG_ 1449 PTOEngSpdTypCstSetAval "ENM";
BA_ "SignalLongName" SG_ 1449 PTOEngSpdTypCstSetAval "Power Take Off Engine Speed Type Customization Setting Available";
BA_ "SignalType" SG_ 1449 PTOEngRunTmrCstSetAval "ENM";
BA_ "SignalLongName" SG_ 1449 PTOEngRunTmrCstSetAval "Power Take Off Engine Run Timer Customization Setting Available";
BA_ "SignalType" SG_ 1449 PTOModeCstCurrSetVal "ENM";
BA_ "SignalLongName" SG_ 1449 PTOModeCstCurrSetVal "Power Take Off Mode Customization Current Setting Value";
BA_ "SignalType" SG_ 1466 PTOSet2SpdCstCurrSetVal "ENM";
BA_ "SignalLongName" SG_ 1466 PTOSet2SpdCstCurrSetVal "Power Take Off Set 2 Speed Customization Current Setting Value";
BA_ "SignalType" SG_ 1466 PTOSet1SpdCstCurrSetVal "ENM";
BA_ "SignalLongName" SG_ 1466 PTOSet1SpdCstCurrSetVal "Power Take Off Set 1 Speed Customization Current Setting Value";
VAL_ 1242 RRSCDS_Massg 0 "Not Selected" 1 "Selected Massage Off" 2 "Selected Massage On" ;
VAL_ 1242 RRSCDS_LmbrUDnFdRr 0 "Not Selected" 1 "Selected-No Movement" 2 "Up" 3 "Down" 4 "Forward" 5 "Rearward" ;
VAL_ 1242 RRSCDS_MassgTyp 0 "Massage Off" 1 "Massage Type 1" 2 "Massage Type 2" 3 "Massage Type 3" 4 "Massage Type 4" 5 "Massage Type 5" 6 "Massage Type 6" 7 "Massage Type 7" 8 "Massage Type 8" 9 "Massage Type 9" 10 "Massage Type 10" 11 "Massage Type 11" 12 "Massage Type 12" 13 "Massage Type 13" 14 "Massage Type 14" 15 "Massage Type 15" ;
VAL_ 1242 RRSCDS_BkCshBlstInOt 0 "Not Selected" 1 "Selected-No Movement" 2 "Back Bolster In" 3 "Back Bolster Out" 4 "Cushion Bolster In" 5 "Cushion Bolster Out" ;
VAL_ 1242 RRSCDS_HdrstFwdRrwd 0 "Not Selected" 1 "Selected-No Movement" 2 "Forward" 3 "Rearward" ;
VAL_ 1242 RRSCDS_LmbrFwdRr 0 "Not Selected" 1 "Selected-No Movement" 2 "Forward" 3 "Rearward" ;
VAL_ 1242 RRSCDS_HdrstFdRrUDn 0 "Not Selected" 1 "Selected-No Movement" 2 "Up" 3 "Down" 4 "Forward" 5 "Rearward" ;
VAL_ 1242 RRSCDS_UprShldrFdRr 0 "Not Selected" 1 "Selected-No Movement" 2 "Forward" 3 "Rearward" ;
VAL_ 1242 RRSCDS_CshBlstrInOut 0 "Not Selected" 1 "Selected-No Movement" 2 "In" 3 "Out" ;
VAL_ 1242 RRSCDS_HdrstWngInOt 0 "Not Selected" 1 "Selected-No Movement" 2 "In" 3 "Out" ;
VAL_ 1242 RRSCDS_HdrstUpDn 0 "Not Selected" 1 "Selected-No Movement" 2 "Up" 3 "Down" ;
VAL_ 1242 RRSCDS_LmbrUpDwn 0 "Not Selected" 1 "Selected-No Movement" 2 "Up" 3 "Down" ;
VAL_ 1242 RRSCDS_MassgIntsty 0 "Massage Off" 1 "Massage Intensity 1" 2 "Massage Intensity 2" 3 "Massage Intensity 3" 4 "Massage Intensity 4" 5 "Massage Intensity 5" 6 "Massage Intensity 6" 7 "Massage Intensity 7" ;
VAL_ 1242 EDADS_ShftIndSt 0 "Shift Down" 1 "Shift Up" 2 "No Shift" ;
VAL_ 1242 RRSCDS_CshLgAdjFdRr 0 "Not Selected" 1 "Selected-No Movement" 2 "Forward" 3 "Rearward" ;
VAL_ 1242 RRSCDS_HdrstTltFwdRr 0 "Not Selected" 1 "Selected-No Movement" 2 "Forward" 3 "Rearward" ;
VAL_ 1242 RRSCDS_BkBlstrInOut 0 "Not Selected" 1 "Selected-No Movement" 2 "In" 3 "Out" ;
VAL_ 1242 RRSCDS_DispReq 0 "FALSE" 1 "TRUE" ;
VAL_ 1242 EDADS_RcmndtFwdGr 0 "None" 1 "First Gear" 2 "Second Gear" 3 "Third Gear" 4 "Fourth Gear" 5 "Fifth Gear" 6 "Sixth Gear" 7 "Seventh Gear" 8 "Eighth Gear" 9 "Ninth Gear" 10 "Tenth Gear" 11 "Unused" 12 "Unused" 13 "Unused" 14 "Unused" 15 "Unused" ;
VAL_ 1242 EDADS_CrntFwdMsdGr 0 "None" 1 "First Gear" 2 "Second Gear" 3 "Third Gear" 4 "Fourth Gear" 5 "Fifth Gear" 6 "Sixth Gear" 7 "Seventh Gear" 8 "Eighth Gear" 9 "Ninth Gear" 10 "Tenth Gear" 11 "Unused" 12 "Unused" 13 "Unused" 14 "Unused" 15 "Unused" ;
VAL_ 1242 CnvtblTpWndMtnReq 0 "NO_ACTION" 1 "OPEN" 2 "CLOSE" 3 "COMFORT_OPEN" 4 "COMFORT_CLOSE" ;
VAL_ 1242 CnvtblTpStat 0 "INDETERMINATE" 1 "FULLY CLOSED" 2 "FULLY OPEN" 3 "CLOSING" 4 "OPENING" 5 "HALTED" ;
VAL_ 1242 EDADS_EcoDrvShftIO 0 "FALSE" 1 "TRUE" ;
VAL_ 1242 DrvDrAjrStat 0 "FALSE" 1 "TRUE" ;
VAL_ 1242 DrvDrAjrStat_Inv 0 "FALSE" 1 "TRUE" ;
VAL_ 1242 FCAACCGapSeltn 0 "Far" 1 "Medium" 2 "Near" 3 "Off" 4 "Unknown" ;
VAL_ 1242 EsyExtCstCurSetVal 0 "SETTING_UNKNOWN" 1 "OFF" 2 "ON" 3 "RESERVED_3" 4 "RESERVED_4" 5 "RESERVED_5" 6 "RESERVED_6" 7 "RESERVED_7" ;
VAL_ 1243 RFSCDS_LmbrUDnFdRr 0 "Not Selected" 1 "Selected-No Movement" 2 "Up" 3 "Down" 4 "Forward" 5 "Rearward" ;
VAL_ 1243 RFSCDS_UprShldrFdRr 0 "Not Selected" 1 "Selected-No Movement" 2 "Forward" 3 "Rearward" ;
VAL_ 1243 RFSCDS_MassgTyp 0 "Massage Off" 1 "Massage Type 1" 2 "Massage Type 2" 3 "Massage Type 3" 4 "Massage Type 4" 5 "Massage Type 5" 6 "Massage Type 6" 7 "Massage Type 7" 8 "Massage Type 8" 9 "Massage Type 9" 10 "Massage Type 10" 11 "Massage Type 11" 12 "Massage Type 12" 13 "Massage Type 13" 14 "Massage Type 14" 15 "Massage Type 15" ;
VAL_ 1243 RFSCDS_HdrstWngInOt 0 "Not Selected" 1 "Selected-No Movement" 2 "In" 3 "Out" ;
VAL_ 1243 RFSCDS_DispReq 0 "FALSE" 1 "TRUE" ;
VAL_ 1243 RFSCDS_BkBlstrInOut 0 "Not Selected" 1 "Selected-No Movement" 2 "In" 3 "Out" ;
VAL_ 1243 RFSCDS_HdrstFwdRrwd 0 "Not Selected" 1 "Selected-No Movement" 2 "Forward" 3 "Rearward" ;
VAL_ 1243 RFSCDS_LmbrFwdRr 0 "Not Selected" 1 "Selected-No Movement" 2 "Forward" 3 "Rearward" ;
VAL_ 1243 RFSCDS_HdrstTltFwdRr 0 "Not Selected" 1 "Selected-No Movement" 2 "Forward" 3 "Rearward" ;
VAL_ 1243 RFSCDS_HdrstUpDn 0 "Not Selected" 1 "Selected-No Movement" 2 "Up" 3 "Down" ;
VAL_ 1243 RFSCDS_Massg 0 "Not Selected" 1 "Selected Massage Off" 2 "Selected Massage On" ;
VAL_ 1243 RFSCDS_MassgIntsty 0 "Massage Off" 1 "Massage Intensity 1" 2 "Massage Intensity 2" 3 "Massage Intensity 3" 4 "Massage Intensity 4" 5 "Massage Intensity 5" 6 "Massage Intensity 6" 7 "Massage Intensity 7" ;
VAL_ 1243 RFSCDS_CshLgAdjFdRr 0 "Not Selected" 1 "Selected-No Movement" 2 "Forward" 3 "Rearward" ;
VAL_ 1243 RFSCDS_BkCshBlstInOt 0 "Not Selected" 1 "Selected-No Movement" 2 "Back Bolster In" 3 "Back Bolster Out" 4 "Cushion Bolster In" 5 "Cushion Bolster Out" ;
VAL_ 1243 RPARS_LtCntr 0 "OFF" 1 "FAILED" 2 "BLOCKED" 3 "ATTACHED_OBJECT" 4 "NO_OBJECT" 5 "ZONE_1" 6 "ZONE_2" 7 "ZONE_3" 8 "ZONE_4" 9 "ZONE_5" 10 "ZONE_6" 11 "OFF_NO_FAULT" 12 "RESERVED_1" 13 "RESERVED_2" 14 "RESERVED_3" ;
VAL_ 1243 RFSCDS_LmbrUpDwn 0 "Not Selected" 1 "Selected-No Movement" 2 "Up" 3 "Down" ;
VAL_ 1243 RFSCDS_HdrstFdRrUDn 0 "Not Selected" 1 "Selected-No Movement" 2 "Up" 3 "Down" 4 "Forward" 5 "Rearward" ;
VAL_ 1243 RFSCDS_CshBlstrInOut 0 "Not Selected" 1 "Selected-No Movement" 2 "In" 3 "Out" ;
VAL_ 1243 RPARS_RtCntr 0 "OFF" 1 "FAILED" 2 "BLOCKED" 3 "ATTACHED_OBJECT" 4 "NO_OBJECT" 5 "ZONE_1" 6 "ZONE_2" 7 "ZONE_3" 8 "ZONE_4" 9 "ZONE_5" 10 "ZONE_6" 11 "OFF_NO_FAULT" 12 "RESERVED_1" 13 "RESERVED_2" 14 "RESERVED_3" ;
VAL_ 1243 RPARS_Rt 0 "OFF" 1 "FAILED" 2 "BLOCKED" 3 "ATTACHED_OBJECT" 4 "NO_OBJECT" 5 "ZONE_1" 6 "ZONE_2" 7 "ZONE_3" 8 "ZONE_4" 9 "ZONE_5" 10 "ZONE_6" 11 "OFF_NO_FAULT" 12 "RESERVED_1" 13 "RESERVED_2" 14 "RESERVED_3" ;
VAL_ 1243 MemCmd 0 "No Operation Required" 1 "Store Mem 1 (Button Mem 1)" 2 "Store Mem 2(Button Mem 2)" 3 "Store Mem 3 (Button Mem 3)" 4 "Store Mem EXIT (Button Mem Exit)" 5 "Recall Mem 1 (Button Mem 1)" 6 "Recall Mem 2 (Button Mem 2)" 7 "Recall Mem 3 (Button Mem 3)" 8 "Recall Mem EXIT (Button Mem Exit)" 9 "Stop All Movement" 10 "RESERVED_10" 11 "RESERVED_11" 12 "RESERVED_12" 13 "RESERVED_13" 14 "RESERVED_14" 15 "RESERVED_15" ;
VAL_ 1243 RPARS_Lt 0 "OFF" 1 "FAILED" 2 "BLOCKED" 3 "ATTACHED_OBJECT" 4 "NO_OBJECT" 5 "ZONE_1" 6 "ZONE_2" 7 "ZONE_3" 8 "ZONE_4" 9 "ZONE_5" 10 "ZONE_6" 11 "OFF_NO_FAULT" 12 "RESERVED_1" 13 "RESERVED_2" 14 "RESERVED_3" ;
VAL_ 1243 CoDrvDrAjrStat 0 "FALSE" 1 "TRUE" ;
VAL_ 1243 CoDrvDrAjrStat_Inv 0 "FALSE" 1 "TRUE" ;
VAL_ 1243 AutMemRclCstCurSetVal 0 "SETTING_UNKNOWN" 1 "OFF" 2 "ON" 3 "AUTO_MEMORY_RECALL" 4 "EASY_EXIT" 5 "AUTO_MEMORY_AND EASY_EXIT_RECALLS" 6 "RESERVED_7" ;
VAL_ 1244 LRSCDS_BkBlstrInOut 0 "Not Selected" 1 "Selected-No Movement" 2 "In" 3 "Out" ;
VAL_ 1244 LRSCDS_UprShldrFdRr 0 "Not Selected" 1 "Selected-No Movement" 2 "Forward" 3 "Rearward" ;
VAL_ 1244 LRSCDS_CshBlstrInOut 0 "Not Selected" 1 "Selected-No Movement" 2 "In" 3 "Out" ;
VAL_ 1244 LRSCDS_HdrstFdRrUDn 0 "Not Selected" 1 "Selected-No Movement" 2 "Up" 3 "Down" 4 "Forward" 5 "Rearward" ;
VAL_ 1244 LRSCDS_HdrstTltFwdRr 0 "Not Selected" 1 "Selected-No Movement" 2 "Forward" 3 "Rearward" ;
VAL_ 1244 LRSCDS_HdrstUpDn 0 "Not Selected" 1 "Selected-No Movement" 2 "Up" 3 "Down" ;
VAL_ 1244 LRSCDS_LmbrUpDwn 0 "Not Selected" 1 "Selected-No Movement" 2 "Up" 3 "Down" ;
VAL_ 1244 LRSCDS_DispReq 0 "FALSE" 1 "TRUE" ;
VAL_ 1244 LRSCDS_MassgIntsty 0 "Massage Off" 1 "Massage Intensity 1" 2 "Massage Intensity 2" 3 "Massage Intensity 3" 4 "Massage Intensity 4" 5 "Massage Intensity 5" 6 "Massage Intensity 6" 7 "Massage Intensity 7" ;
VAL_ 1244 LRSCDS_HdrstWngInOt 0 "Not Selected" 1 "Selected-No Movement" 2 "In" 3 "Out" ;
VAL_ 1244 LRSCDS_LmbrUDnFdRr 0 "Not Selected" 1 "Selected-No Movement" 2 "Up" 3 "Down" 4 "Forward" 5 "Rearward" ;
VAL_ 1244 LRSCDS_CshLgAdjFdRr 0 "Not Selected" 1 "Selected-No Movement" 2 "Forward" 3 "Rearward" ;
VAL_ 1244 LRSCDS_HdrstFwdRrwd 0 "Not Selected" 1 "Selected-No Movement" 2 "Forward" 3 "Rearward" ;
VAL_ 1244 LRSCDS_LmbrFwdRr 0 "Not Selected" 1 "Selected-No Movement" 2 "Forward" 3 "Rearward" ;
VAL_ 1244 LRSCDS_Massg 0 "Not Selected" 1 "Selected Massage Off" 2 "Selected Massage On" ;
VAL_ 1244 SAP_SecAxlOpMdAuth 0 "2WD High" 1 "4WD High Rigid Coupling" 2 "4WD Low Rigid Coupling" 3 "AWD Active Single Clutch" 4 "4WD High Active Clutch" 5 "4WD Low Active Clutch" 6 "AWD Active Twin Clutch" 7 "2WD Low" 8 "Unknown" 9 "Neutral" ;
VAL_ 1244 LRSCDS_BkCshBlstInOt 0 "Not Selected" 1 "Selected-No Movement" 2 "Back Bolster In" 3 "Back Bolster Out" 4 "Cushion Bolster In" 5 "Cushion Bolster Out" ;
VAL_ 1244 LRSCDS_MassgTyp 0 "Massage Off" 1 "Massage Type 1" 2 "Massage Type 2" 3 "Massage Type 3" 4 "Massage Type 4" 5 "Massage Type 5" 6 "Massage Type 6" 7 "Massage Type 7" 8 "Massage Type 8" 9 "Massage Type 9" 10 "Massage Type 10" 11 "Massage Type 11" 12 "Massage Type 12" 13 "Massage Type 13" 14 "Massage Type 14" 15 "Massage Type 15" ;
VAL_ 1244 SAP_SecAxl4WDAWDStatAuth 0 "Normal" 1 "Temporary_Limited" 2 "Temporary_Inhibit" 3 "Permanently_Failed" ;
VAL_ 1244 SAP_SecAxlOpMdAuth_Inv 0 "FALSE" 1 "TRUE" ;
VAL_ 1244 SAP_SecAxl4WDAWDEstTrqAuth_Inv 0 "FALSE" 1 "TRUE" ;
VAL_ 1244 AdpLghtRspTypCstCurSetVal 0 "SETTING_UNKNOWN" 1 "OFF" 2 "CORNER_AND_CURVE_LIGHTING" 3 "INTELLIGENT_LIGHT_DISTRIBUTION" 4 "INTELLIGENT_LIGHT_DISTRIBUTION_GPS_ASSISTANCE" 5 "RESERVED_5" 6 "RESERVED_6" 7 "RESERVED_7" ;
VAL_ 1244 HSP_HptcStPrsntAuth 0 "FALSE" 1 "TRUE" ;
VAL_ 1244 HSP_DrvAlrtTypCstCurrSetValAuth 0 "SETTING_UNKNOWN" 1 "CHIME" 2 "SEAT" ;
VAL_ 1245 LFSCDS_LmbrUDnFdRr 0 "Not Selected" 1 "Selected-No Movement" 2 "Up" 3 "Down" 4 "Forward" 5 "Rearward" ;
VAL_ 1245 LFSCDS_DispReq 0 "FALSE" 1 "TRUE" ;
VAL_ 1245 LFSCDS_UprShldrFdRr 0 "Not Selected" 1 "Selected-No Movement" 2 "Forward" 3 "Rearward" ;
VAL_ 1245 LFSCDS_LmbrUpDwn 0 "Not Selected" 1 "Selected-No Movement" 2 "Up" 3 "Down" ;
VAL_ 1245 LFSCDS_Massg 0 "Not Selected" 1 "Selected Massage Off" 2 "Selected Massage On" ;
VAL_ 1245 LFSCDS_BkBlstrInOut 0 "Not Selected" 1 "Selected-No Movement" 2 "In" 3 "Out" ;
VAL_ 1245 LFSCDS_HdrstTltFwdRr 0 "Not Selected" 1 "Selected-No Movement" 2 "Forward" 3 "Rearward" ;
VAL_ 1245 LFSCDS_LmbrFwdRr 0 "Not Selected" 1 "Selected-No Movement" 2 "Forward" 3 "Rearward" ;
VAL_ 1245 LFSCDS_MassgTyp 0 "Massage Off" 1 "Massage Type 1" 2 "Massage Type 2" 3 "Massage Type 3" 4 "Massage Type 4" 5 "Massage Type 5" 6 "Massage Type 6" 7 "Massage Type 7" 8 "Massage Type 8" 9 "Massage Type 9" 10 "Massage Type 10" 11 "Massage Type 11" 12 "Massage Type 12" 13 "Massage Type 13" 14 "Massage Type 14" 15 "Massage Type 15" ;
VAL_ 1245 LFSCDS_HdrstFdRrUDn 0 "Not Selected" 1 "Selected-No Movement" 2 "Up" 3 "Down" 4 "Forward" 5 "Rearward" ;
VAL_ 1245 LFSCDS_CshBlstrInOut 0 "Not Selected" 1 "Selected-No Movement" 2 "In" 3 "Out" ;
VAL_ 1245 LFSCDS_HdrstUpDn 0 "Not Selected" 1 "Selected-No Movement" 2 "Up" 3 "Down" ;
VAL_ 1245 LFSCDS_HdrstWngInOt 0 "Not Selected" 1 "Selected-No Movement" 2 "In" 3 "Out" ;
VAL_ 1245 LFSCDS_BkCshBlstInOt 0 "Not Selected" 1 "Selected-No Movement" 2 "Back Bolster In" 3 "Back Bolster Out" 4 "Cushion Bolster In" 5 "Cushion Bolster Out" ;
VAL_ 1245 SDGPARS_CntrLtSd 0 "OFF" 1 "FAILED" 2 "BLOCKED" 3 "ATTACHED_OBJECT" 4 "NO_OBJECT" 5 "ZONE_1" 6 "ZONE_2" 7 "ZONE_3" 8 "ZONE_4" 9 "ZONE_5" 10 "ZONE_6" 11 "OFF_NO_FAULT" 12 "RESERVED_1" 13 "RESERVED_2" 14 "RESERVED_3" ;
VAL_ 1245 LFSCDS_MassgIntsty 0 "Massage Off" 1 "Massage Intensity 1" 2 "Massage Intensity 2" 3 "Massage Intensity 3" 4 "Massage Intensity 4" 5 "Massage Intensity 5" 6 "Massage Intensity 6" 7 "Massage Intensity 7" ;
VAL_ 1245 LFSCDS_CshLgAdjFdRr 0 "Not Selected" 1 "Selected-No Movement" 2 "Forward" 3 "Rearward" ;
VAL_ 1245 LFSCDS_HdrstFwdRrwd 0 "Not Selected" 1 "Selected-No Movement" 2 "Forward" 3 "Rearward" ;
VAL_ 1245 SDGPARS_FrtLtSd 0 "OFF" 1 "FAILED" 2 "BLOCKED" 3 "ATTACHED_OBJECT" 4 "NO_OBJECT" 5 "ZONE_1" 6 "ZONE_2" 7 "ZONE_3" 8 "ZONE_4" 9 "ZONE_5" 10 "ZONE_6" 11 "OFF_NO_FAULT" 12 "RESERVED_1" 13 "RESERVED_2" 14 "RESERVED_3" ;
VAL_ 1245 SDGPARS_RrRtSd 0 "OFF" 1 "FAILED" 2 "BLOCKED" 3 "ATTACHED_OBJECT" 4 "NO_OBJECT" 5 "ZONE_1" 6 "ZONE_2" 7 "ZONE_3" 8 "ZONE_4" 9 "ZONE_5" 10 "ZONE_6" 11 "OFF_NO_FAULT" 12 "RESERVED_1" 13 "RESERVED_2" 14 "RESERVED_3" ;
VAL_ 1245 SDGPARS_RrLtSd 0 "OFF" 1 "FAILED" 2 "BLOCKED" 3 "ATTACHED_OBJECT" 4 "NO_OBJECT" 5 "ZONE_1" 6 "ZONE_2" 7 "ZONE_3" 8 "ZONE_4" 9 "ZONE_5" 10 "ZONE_6" 11 "OFF_NO_FAULT" 12 "RESERVED_1" 13 "RESERVED_2" 14 "RESERVED_3" ;
VAL_ 1245 SDGPARS_CntrRtSd 0 "OFF" 1 "FAILED" 2 "BLOCKED" 3 "ATTACHED_OBJECT" 4 "NO_OBJECT" 5 "ZONE_1" 6 "ZONE_2" 7 "ZONE_3" 8 "ZONE_4" 9 "ZONE_5" 10 "ZONE_6" 11 "OFF_NO_FAULT" 12 "RESERVED_1" 13 "RESERVED_2" 14 "RESERVED_3" ;
VAL_ 1245 AutoHldEnbld 0 "FALSE" 1 "TRUE" ;
VAL_ 1245 SDGPARS_FrtRtSd 0 "OFF" 1 "FAILED" 2 "BLOCKED" 3 "ATTACHED_OBJECT" 4 "NO_OBJECT" 5 "ZONE_1" 6 "ZONE_2" 7 "ZONE_3" 8 "ZONE_4" 9 "ZONE_5" 10 "ZONE_6" 11 "OFF_NO_FAULT" 12 "RESERVED_1" 13 "RESERVED_2" 14 "RESERVED_3" ;
VAL_ 1246 PCOSN_NtfnSecRowCntrStBltSts 0 "Unknown" 1 "UnFastened" 2 "Fastened" 3 "Data Not Available" ;
VAL_ 1246 PCOSN_NtfnSecRowLtStBltSts 0 "Unknown" 1 "UnFastened" 2 "Fastened" 3 "Data Not Available" ;
VAL_ 1246 PCOSN_NtfnThrdRowCntrStBltSts 0 "Unknown" 1 "UnFastened" 2 "Fastened" 3 "Data Not Available" ;
VAL_ 1246 PCOSN_NtfnImpDeltVelTxSts 0 "Not Available" 1 "Pending" 2 "Complete" ;
VAL_ 1246 PCOSN_NtfnSecRowCntrStOccpSts 0 "Unknown" 1 "Empty" 2 "Occupied" 3 "Data Not Available" ;
VAL_ 1246 PCOSN_NtfnSecRowLtStOccpSts 0 "Unknown" 1 "Empty" 2 "Occupied" 3 "Data Not Available" ;
VAL_ 1246 PCOSN_NtfnSecRowRtStBltSts 0 "Unknown" 1 "UnFastened" 2 "Fastened" 3 "Data Not Available" ;
VAL_ 1246 PCOSN_NtfnThrdRowCntrStOccpSts 0 "Unknown" 1 "Empty" 2 "Occupied" 3 "Data Not Available" ;
VAL_ 1246 PCOSN_NtfnThrdRowRtStOccpSts 0 "Unknown" 1 "Empty" 2 "Occupied" 3 "Data Not Available" ;
VAL_ 1246 PCOSN_NtfnFrstPsngrStBltSts 0 "Unknown" 1 "UnFastened" 2 "Fastened" 3 "Data Not Available" ;
VAL_ 1246 PCOSN_NtfnFrstPsngrStOccpSts 0 "UNKNOWN" 1 "EMPTY" 2 "OCCUPIED" 3 "DATA NOT AVAILABLE" ;
VAL_ 1246 PCOSN_NtfnSecRowRtStOccpSts 0 "Unknown" 1 "Empty" 2 "Occupied" 3 "Data Not Available" ;
VAL_ 1246 PCOSN_NtfnThrdRowLtStOccpSts 0 "Unknown" 1 "Empty" 2 "Occupied" 3 "Data Not Available" ;
VAL_ 1246 PCOSN_NtfnThrdRowRtStBltSts 0 "Unknown" 1 "UnFastened" 2 "Fastened" 3 "Data Not Available" ;
VAL_ 1246 PCOSN_NtfnDrvrStBltSts 0 "Unknown" 1 "UnFastened" 2 "Fastened" 3 "Data Not Available" ;
VAL_ 1246 PCOSN_NtfnThrdRowLtStBltSts 0 "Unknown" 1 "UnFastened" 2 "Fastened" 3 "Data Not Available" ;
VAL_ 1246 TDAP_DrvrStMemIdfrAuth 0 "Memory 1" 1 "Memory 2" 2 "Memory 3" 3 "Memory 4" 4 "Memory 5" 5 "Memory 6" 6 "Memory 7" 7 "Unknown" ;
VAL_ 1246 TDAP_DrvrIdfrAuth 0 "Driver 1" 1 "Driver 2" 2 "Driver 3" 3 "Driver 4" 4 "Driver 5" 5 "Driver 6" 6 "Driver 7" 7 "Unknown" ;
VAL_ 1246 TDAP_TeenDrvrActvAuth 0 "FALSE" 1 "TRUE" ;
VAL_ 1247 AutoHgBmActReq 0 "FALSE" 1 "TRUE" ;
VAL_ 1248 AutMemRclCstStAvl 0 "FALSE" 1 "TRUE" ;
VAL_ 1249 AdpLghtRspTypCstStAvl 0 "FALSE" 1 "TRUE" ;
VAL_ 1250 ACCBRP_ACCActvAuth 0 "FALSE" 1 "TRUE" ;
VAL_ 44 VMI1P_VehTopSpdLimModeActvAuth 0 "FALSE" 1 "TRUE" ;
VAL_ 44 VMI1P_AccelActlPstnAuth_Inv 0 "FALSE" 1 "TRUE" ;
VAL_ 44 VMI1P_AccelPedOvrrdActvAuth 0 "FALSE" 1 "TRUE" ;
VAL_ 611 RdWhlAng_Inv 0 "FALSE" 1 "TRUE" ;
VAL_ 611 VehPtchAng_Inv 0 "FALSE" 1 "TRUE" ;
VAL_ 611 VehRollAng_Inv 0 "FALSE" 1 "TRUE" ;
VAL_ 611 CnvtTopModSpdLimIndOn 0 "FALSE" 1 "TRUE" ;
VAL_ 612 TEGP_TrnsShftLvrPstnAuth 0 "Between Ranges" 1 "Park Range" 2 "Reverse Range" 3 "Neutral Range" 4 "Forward Range A" 5 "Forward Range B" 6 "Forward Range C" 7 "Forward Range D" 8 "Forward Range E" 9 "Forward Range F" 10 "Forward Range G" 11 "Forward Range H" 12 "Forward Range I" 13 "Forward Range J" 14 "Lever Position Unknown" ;
VAL_ 612 TrnsRngInhbtSt 0 "No Range Inhibit Active" 1 "Transmission Inhibit Active" 2 "Transmission Range Re-Selection Req" 3 "Driveline Not Engaged" 4 "Diagnostic Inhibit Active" ;
VAL_ 612 IntAmbtBrghtnsCtrlStVal 0 "No Action" 1 "BrightnessLevel 1" 2 "BrightnessLevel 2" 3 "BrightnessLevel 3" 4 "BrightnessLevel 4" 5 "ReservedLevel 5" 6 "ReservedLevel 6" 7 "ReservedLevel 7" ;
VAL_ 612 TEGP_TrnsShftLvrPstnAuth_Inv 0 "FALSE" 1 "TRUE" ;
VAL_ 612 TEGP_TransCmndGrAuth 0 "Not Supported" 1 "First Gear" 2 "Second Gear" 3 "Third Gear" 4 "Fourth Gear" 5 "Fifth Gear" 6 "Sixth Gear" 7 "Seventh Gear" 8 "Eighth Gear" 9 "Ninth Gear" 10 "Tenth Gear" 11 "Unused and Reserved" 12 "CVT Forward Gear" 13 "Neutral Gear" 14 "Reverse Gear" 15 "Park Gear" ;
VAL_ 612 IntAmbtBrghtnsCtrlStAvl 0 "FALSE" 1 "TRUE" ;
VAL_ 612 BkUpPwrMdRnCrnkOutSt 0 "FALSE" 1 "TRUE" ;
VAL_ 612 TrnsTUTDMdSt 0 "No Activation" 1 "Driver Shift Control Active" 2 "Electronic Range Select Active" ;
VAL_ 612 EASSI_StrtStpSt 0 "Engine Off" 1 "Engine Running" 2 "Engine Starting" 3 "Engine Stopping" ;
VAL_ 612 TEGP_TrnsEstGrAuth 0 "Not Supported" 1 "First Gear" 2 "Second Gear" 3 "Third Gear" 4 "Fourth Gear" 5 "Fifth Gear" 6 "Sixth Gear" 7 "Seventh Gear" 8 "Eighth Gear" 9 "Ninth Gear" 10 "Tenth Gear" 11 "Unused and Reserved" 12 "CVT Forward Gear" 13 "Neutral Gear" 14 "Reverse Gear" 15 "Park Gear" ;
VAL_ 612 TEGP_TrnsEngdStAuth_Inv 0 "FALSE" 1 "TRUE" ;
VAL_ 612 TEGP_TrnsEngdStAuth 0 "Transmission Not Engaged" 1 "Transmission Engaged in Forward" 2 "Transmission Engaged in Reverse" 3 "Operating State Not Reached" ;
VAL_ 612 TEGP_TrnsEstGrAuth_Inv 0 "FALSE" 1 "TRUE" ;
VAL_ 181 FWDECP_RFAuth_Inv 0 "FALSE" 1 "TRUE" ;
VAL_ 181 FWDECP_RstOccAuth 0 "FALSE" 1 "TRUE" ;
VAL_ 181 FWDECP_LFAuth_Inv 0 "FALSE" 1 "TRUE" ;
VAL_ 181 RWDECP_RRAuth_Inv 0 "FALSE" 1 "TRUE" ;
VAL_ 181 RWDECP_RstOccAuth 0 "FALSE" 1 "TRUE" ;
VAL_ 181 RWDECP_LRAuth_Inv 0 "FALSE" 1 "TRUE" ;
VAL_ 181 ASPATR_ClsnImntBrkgAxlTrqRqActv 0 "FALSE" 1 "TRUE" ;
VAL_ 181 CIBAutoBrkReqActv 0 "FALSE" 1 "TRUE" ;
VAL_ 181 DMSIP_DrvrAttnStatAuth_Inv 0 "FALSE" 1 "TRUE" ;
VAL_ 181 DMSIP_DrvrAttnStatAuth 0 "Unknown" 1 "Attention is On Road" 2 "Attention is Off Road" 3 "Attention is Driver's Lap" 4 "Attention is Center Console" 5 "Driver\???s Eyes Fully Closed" 6 "Reserved" ;
VAL_ 181 ACCBRP_ReqActvAuth 0 "FALSE" 1 "TRUE" ;
VAL_ 181 ACCATRIP_TrqActvAuth 0 "FALSE" 1 "TRUE" ;
VAL_ 181 LCCPIP_LnCntrCtlAclPedLimRqAuth 0 "FALSE" 1 "TRUE" ;
VAL_ 1251 EngOilPrs_Inv 0 "FALSE" 1 "TRUE" ;
VAL_ 1251 StrgWhlTchSnsHndsOnStat 0 "Hands Off" 1 "Hands On" ;
VAL_ 40 HstVehLngVel_Inv 0 "FALSE" 1 "TRUE" ;
VAL_ 40 HstVehYawRate_Inv 0 "FALSE" 1 "TRUE" ;
VAL_ 40 HstVehLatVel_Inv 0 "FALSE" 1 "TRUE" ;
VAL_ 43 ESP_EngSpdStAuth 0 "Normal_Operation" 1 "Degraded_Operation" 2 "Invalid" ;
VAL_ 1172 TrlrTirePresProfXferSts 0 "Not Active" 1 "Completed" 2 "In Progress" 3 "Failed" ;
VAL_ 1172 FrwdVehAhdIndReq 0 "OFF" 1 "ON" 2 "0.5_Hz" 3 "1_Hz" 4 "2_Hz" 5 "4_Hz" ;
VAL_ 1172 ServPedtrnFrndlyAlrtIndOn 0 "FALSE" 1 "TRUE" ;
VAL_ 1172 RrAxlTmpInhIO 0 "FALSE" 1 "TRUE" ;
VAL_ 1172 RrAxlMlfIO 0 "FALSE" 1 "TRUE" ;
VAL_ 1172 RegVltgCtlEngyRcvryActv 0 "FALSE" 1 "TRUE" ;
VAL_ 1172 HillDscntCtlDispActvIndOn 0 "FALSE" 1 "TRUE" ;
VAL_ 1172 Deg360VidFtrPrsnt 0 "FALSE" 1 "TRUE" ;
VAL_ 1172 BrkgSysVehTopSpdLimIndOn 0 "FALSE" 1 "TRUE" ;
VAL_ 1172 TrgrdVidRcrdrFtrPrsnt 0 "FALSE" 1 "TRUE" ;
VAL_ 1172 TireRRLoTracIndOn 0 "FALSE" 1 "TRUE" ;
VAL_ 1172 TireRFLoTracIndOn 0 "FALSE" 1 "TRUE" ;
VAL_ 1172 TireLRLoTracIndOn 0 "FALSE" 1 "TRUE" ;
VAL_ 1172 TireLFLoTracIndOn 0 "FALSE" 1 "TRUE" ;
VAL_ 1172 MemIdfrIgnOnIndReq 0 "No Action" 1 "Driver 1" 2 "Driver 2" 3 "Driver 3" 4 "Driver 4" 5 "Driver 5" 6 "Driver 6" 7 "Driver 7" 8 "Driver 8" ;
VAL_ 1172 HybStatElecVehModeOvrrd 0 "Undetermined" 1 "No Override" 2 "Too Cold" 3 "Battery Low" 4 "Speed too High" 5 "Generic Override" 6 "Grade too High" 7 "Accelerator Pedal Threshold Exceeded" ;
VAL_ 1172 ROSP_FrntPsRestOcpStatAuth 0 "Unknown" 1 "Empty" 2 "Empty or Occupied_Non-Adult" 3 "Occupied_Adult" ;
VAL_ 1172 HiVltgBatAvgTemp_Inv 0 "FALSE" 1 "TRUE" ;
VAL_ 1253 SLVFSP_SpdLimVsnFsdSpdUntAuth 0 "km/h" 1 "mph" ;
VAL_ 1066 CustUsblSOC_DuD 0 "FALSE" 1 "TRUE" ;
VAL_ 1066 HiVltgBatMinTemp_Inv 0 "FALSE" 1 "TRUE" ;
VAL_ 1066 TnDrvStBltShfIntlkCstAvlFlg4 0 "FALSE" 1 "TRUE" ;
VAL_ 1066 TnDrvStBltShfIntlkCstAvlFlg3 0 "FALSE" 1 "TRUE" ;
VAL_ 1066 TnDrvStBltShfIntlkCstAvlFlg2 0 "FALSE" 1 "TRUE" ;
VAL_ 1066 TnDrvStBltShfIntlkCstAvlFlg1 0 "FALSE" 1 "TRUE" ;
VAL_ 1066 PwrRrClsrCstSetAval 0 "FALSE" 1 "TRUE" ;
VAL_ 1066 PwrRrClsrCstAvlFlg7 0 "FALSE" 1 "TRUE" ;
VAL_ 1066 PwrRrClsrCstAvlFlg6 0 "FALSE" 1 "TRUE" ;
VAL_ 1107 MemIdfrMemStorIndReq 0 "No Action" 1 "Driver 1" 2 "Driver 2" 3 "Driver 3" 4 "Driver 4" 5 "Driver 5" 6 "Driver 6" 7 "Driver 7" 8 "Driver 8" ;
VAL_ 1107 ServHiVltgBatIndReq 0 "No Indication" 1 "Shut Down Soon" 2 "No Restart" ;
VAL_ 1107 HtdStrgWhlInd_HVAC_FP_F 0 "Off" 1 "Low" 2 "Med" 3 "High" ;
VAL_ 1107 HiVltgBatLmtnDueToTempInd 0 "Normal" 1 "Cold" 2 "Hot" ;
VAL_ 1107 ServHybSysIndOn 0 "FALSE" 1 "TRUE" ;
VAL_ 1107 ReqFrtPsgrRstntOccFltInd 0 "FALSE" 1 "TRUE" ;
VAL_ 1107 RegenPwrLimdIndOn 0 "FALSE" 1 "TRUE" ;
VAL_ 1107 RegenPwrLimdDispPctVsbl 0 "FALSE" 1 "TRUE" ;
VAL_ 1107 PrplDispTotPwrUntDisp 0 "kilowatt" 1 "Horsepower" ;
VAL_ 1107 LossOfPrplIndOn 0 "FALSE" 1 "TRUE" ;
VAL_ 1107 HybShfToPrkIndOn 0 "FALSE" 1 "TRUE" ;
VAL_ 1107 EngRnngDueToVehSpdIndOn 0 "FALSE" 1 "TRUE" ;
VAL_ 1107 InstnsFuelEconHybOvrrdReq 0 "No Action" 1 "Min Fuel Economy" 2 "Max Fuel Economy" 3 "Auto Stop" 4 "EV" ;
VAL_ 1107 HybStatShtlModeOvrrd 0 "Undetermined" 1 "No Override" 2 "Too Cold" 3 "Battery Low" 4 "Speed too High" 5 "Generic Override" 6 "Grade too High" 7 "Accelerator Pedal Threshold Exceeded" ;
VAL_ 1107 DM6Denied 0 "FALSE" 1 "TRUE" ;
VAL_ 1107 DM5Denied 0 "FALSE" 1 "TRUE" ;
VAL_ 1107 DM4Denied 0 "FALSE" 1 "TRUE" ;
VAL_ 1107 DM3Denied 0 "FALSE" 1 "TRUE" ;
VAL_ 1107 JmpStrtSts 0 "Inactive" 1 "In Progress" 2 "Complete" 3 "Power Mode" 4 "Disabled" ;
VAL_ 521 TSP_TmpDrvrShfCtlActvAuth 0 "FALSE" 1 "TRUE" ;
VAL_ 521 TSP_ElecRngSeltnInDrvActvAuth 0 "FALSE" 1 "TRUE" ;
VAL_ 45 VCBA_FrtJnctnActv 0 "FALSE" 1 "TRUE" ;
VAL_ 45 VCBA_DynGdlnsActv 0 "FALSE" 1 "TRUE" ;
VAL_ 45 VCBA_CurbVwGdlnsActv 0 "FALSE" 1 "TRUE" ;
VAL_ 45 VCBA_CurbOvrhdActv 0 "FALSE" 1 "TRUE" ;
VAL_ 45 VCBA_CurbActv 0 "FALSE" 1 "TRUE" ;
VAL_ 45 VCBA_CrgBedActv 0 "FALSE" 1 "TRUE" ;
VAL_ 45 VCBA_BowlActv 0 "FALSE" 1 "TRUE" ;
VAL_ 45 VCBA_BedHtchActv 0 "FALSE" 1 "TRUE" ;
VAL_ 45 VCBA_RrOvrhdActv 0 "FALSE" 1 "TRUE" ;
VAL_ 45 VCBA_RrJnctnActv 0 "FALSE" 1 "TRUE" ;
VAL_ 45 VCBA_RrHtchActv 0 "FALSE" 1 "TRUE" ;
VAL_ 45 VCBA_LRTrlrTowMirActv 0 "FALSE" 1 "TRUE" ;
VAL_ 45 VCBA_JPActv 0 "FALSE" 1 "TRUE" ;
VAL_ 45 VCBA_InvsblTrlrActv 0 "FALSE" 1 "TRUE" ;
VAL_ 45 VCBA_FrtPrspctvActv 0 "FALSE" 1 "TRUE" ;
VAL_ 45 VCBA_FrtOvrhdActv 0 "FALSE" 1 "TRUE" ;
VAL_ 45 VCBA_TrlrTowMirActv 0 "FALSE" 1 "TRUE" ;
VAL_ 45 VCBA_TrlrGdlnsActv 0 "FALSE" 1 "TRUE" ;
VAL_ 45 VCBA_TrlrAux2Actv 0 "FALSE" 1 "TRUE" ;
VAL_ 45 VCBA_TrlrAux1CmbdActv 0 "FALSE" 1 "TRUE" ;
VAL_ 45 VCBA_TrlrAux1Actv 0 "FALSE" 1 "TRUE" ;
VAL_ 45 VCBA_SdRrwdActv 0 "FALSE" 1 "TRUE" ;
VAL_ 45 VCBA_SdFrwdActv 0 "FALSE" 1 "TRUE" ;
VAL_ 45 VCBA_RrPrspctvActv 0 "FALSE" 1 "TRUE" ;
VAL_ 45 VCBA_ZmdBowlActv 0 "FALSE" 1 "TRUE" ;
VAL_ 45 SrrndVsnRcrdrDelFileReqSts 0 "Unknown" 1 "File_1 Deleted" 2 "File_2 Deleted" 3 "File_3 Deleted" 4 "File_4 Deleted" 5 "File_5 Deleted" 6 "No Selection" 7 "Delete Failed" ;
VAL_ 45 SrrndVsnRcrdrVwprtSts 0 "Unknown" 1 "Playback Mosaic" 2 "Playback Zoom1" 3 "Playback Zoom2" 4 "Playback Zoom3" 5 "Playback Zoom4" 6 "List Recent" 7 "List Saved" ;
VAL_ 45 SrrndVsnRcrdrVwprtReq 0 "Unknown" 1 "Playback Mosaic" 2 "Playback Zoom1" 3 "Playback Zoom2" 4 "Playback Zoom3" 5 "Playback Zoom4" 6 "List Recent" 7 "List Saved" ;
VAL_ 45 SrrndVsnRcrdrPlybkSts 0 "Unknown" 1 "Play" 2 "Pause" 3 "Rewind" 4 "Fast Forward" 5 "No Selection" ;
VAL_ 45 SrrndVsnRcrdrRcrdSts 0 "Unknown" 1 "Enabled" 2 "Disabled" ;
VAL_ 45 SrrndVsnRcrdrListPgSts 0 "Unknown" 1 "Page Up" 2 "Page Down" 3 "No Selection" ;
VAL_ 45 VGVS_TrlrActv 0 "FALSE" 1 "TRUE" ;
VAL_ 45 VGVS_DynActv 0 "FALSE" 1 "TRUE" ;
VAL_ 45 VGVS_CurbVwActv 0 "FALSE" 1 "TRUE" ;
VAL_ 45 VCBA_TrnspHdActv 0 "FALSE" 1 "TRUE" ;
VAL_ 45 SrrndVsnRcrdrRcrdgActv 0 "FALSE" 1 "TRUE" ;
VAL_ 45 SVRCBA_PgUpActv 0 "FALSE" 1 "TRUE" ;
VAL_ 45 SVRCBA_PgDnActv 0 "FALSE" 1 "TRUE" ;
VAL_ 1300 RmtRflshDispActvnReq 0 "FALSE" 1 "TRUE" ;
VAL_ 1300 RmtRflshCmpgnAval 0 "FALSE" 1 "TRUE" ;
VAL_ 1300 RdcBrkgToAvoidOvrhtgIndOn 0 "FALSE" 1 "TRUE" ;
VAL_ 1300 HiVltgSysDsbld 0 "FALSE" 1 "TRUE" ;
VAL_ 1300 FuelFiltChgNowIndOn 0 "FALSE" 1 "TRUE" ;
VAL_ 1300 ElecAllWhlDrvIndOn 0 "FALSE" 1 "TRUE" ;
VAL_ 1300 DM8Denied 0 "FALSE" 1 "TRUE" ;
VAL_ 1300 DM7Denied 0 "FALSE" 1 "TRUE" ;
VAL_ 1300 TrnspModeInactiveIndOn 0 "FALSE" 1 "TRUE" ;
VAL_ 1300 TrnspModeActvIndOn 0 "FALSE" 1 "TRUE" ;
VAL_ 1300 BrkTempStsIndReq 0 "No Action" 1 "Normal" 2 "Warm" 3 "Hot" 4 "Overheated" ;
VAL_ 1301 VwgVwprtSts 0 "Unknown" 1 "Front Perspective" 2 "Front Junction" 3 "Front Overhead" 4 "Side Forward" 5 "Rear Perspective" 6 "Rear Junction" 7 "Rear Overhead" 8 "Side Rearward" 9 "Bowl" 10 "Zoomed Bowl" 11 "Japan" 12 "Rear Hitch" 13 "Bed Hitch" 14 "Trailer Aux1" 15 "Trailer Towing Mirror" 16 "L R Trailer Towing Mirror" 17 "Trailer Aux1 Combined" 18 "Trailer Aux2" 19 "Invisible Trailer" 20 "Cargo Bed" 21 "Curb Overhead" 22 "Curb" 23 "No Request" 24 "Transparent Hood" ;
VAL_ 1301 VwgVwprtReq 0 "Unknown" 1 "Front Perspective" 2 "Front Junction" 3 "Front Overhead" 4 "Side Forward" 5 "Rear Perspective" 6 "Rear Junction" 7 "Rear Overhead" 8 "Side Rearward" 9 "Bowl" 10 "Zoomed Bowl" 11 "Japan" 12 "Rear Hitch" 13 "Bed Hitch" 14 "Trailer Aux1" 15 "Trailer Towing Mirror" 16 "L R Trailer Towing Mirror" 17 "Trailer Aux1 Combined" 18 "Trailer Aux2" 19 "Invisible Trailer" 20 "Cargo Bed" 21 "Curb Overhead" 22 "Curb" 23 "No Request" 24 "Transparent Hood" ;
VAL_ 1301 StBltShfIntlkCstCurrSetVal 0 "SETTING_UNKNOWN" 1 "OFF" 2 "ON" 3 "RESERVED_3" 4 "RESERVED_4" 5 "RESERVED_5" 6 "RESERVED_6" 7 "RESERVED_7" ;
VAL_ 1301 TnDrvStBltShfIntlkCstSetAval 0 "FALSE" 1 "TRUE" ;
VAL_ 1301 TnDrvStBltShfIntlkCstCurrSetVal 0 "SETTING_UNKNOWN" 1 "OFF" 2 "ON" 3 "RESERVED_3" 4 "RESERVED_4" 5 "RESERVED_5" 6 "RESERVED_6" 7 "RESERVED_7" ;
VAL_ 1301 LvlgSysEntEgrsMdCstCurrSetVal 0 "SETTING_UNKNOWN" 1 "OFF" 2 "ON" 3 "RESERVED_3" 4 "RESERVED_4" 5 "RESERVED_5" 6 "RESERVED_6" 7 "RESERVED_7" ;
VAL_ 1301 LvlgSysAlgnMdCstCurrSetVal 0 "SETTING_UNKNOWN" 1 "OFF" 2 "ON" 3 "RESERVED_3" 4 "RESERVED_4" 5 "RESERVED_5" 6 "RESERVED_6" 7 "RESERVED_7" ;
VAL_ 1301 StBltShfIntlkCstSetAval 0 "FALSE" 1 "TRUE" ;
VAL_ 1301 RideHghtSeltn2Name 0 "No Action" 1 "Auto" 2 "Raised 2" 3 "Raised" 4 "Normal" 5 "Entry/Exit" 6 "Cargo Loading" 7 "Lowered" ;
VAL_ 1301 RideHghtSeltn1Name 0 "No Action" 1 "Auto" 2 "Raised 2" 3 "Raised" 4 "Normal" 5 "Entry/Exit" 6 "Cargo Loading" 7 "Lowered" ;
VAL_ 1301 LvlgSysServMdCstCurrSetVal 0 "SETTING_UNKNOWN" 1 "OFF" 2 "ON" 3 "RESERVED_3" 4 "RESERVED_4" 5 "RESERVED_5" 6 "RESERVED_6" 7 "RESERVED_7" ;
VAL_ 1301 LvlgSysAlgnMdCstSetAval 0 "FALSE" 1 "TRUE" ;
VAL_ 1301 RideHghtSeltn4Name 0 "No Action" 1 "Auto" 2 "Raised 2" 3 "Raised" 4 "Normal" 5 "Entry/Exit" 6 "Cargo Loading" 7 "Lowered" ;
VAL_ 1301 RideHghtSeltn3Name 0 "No Action" 1 "Auto" 2 "Raised 2" 3 "Raised" 4 "Normal" 5 "Entry/Exit" 6 "Cargo Loading" 7 "Lowered" ;
VAL_ 1289 StBltShfIntlkCstAvlFlg3 0 "FALSE" 1 "TRUE" ;
VAL_ 1289 StBltShfIntlkCstAvlFlg2 0 "FALSE" 1 "TRUE" ;
VAL_ 1289 StBltShfIntlkCstAvlFlg1 0 "FALSE" 1 "TRUE" ;
VAL_ 1289 TnDrvStBltShfIntlkCstAvlFlg7 0 "FALSE" 1 "TRUE" ;
VAL_ 1289 TnDrvStBltShfIntlkCstAvlFlg6 0 "FALSE" 1 "TRUE" ;
VAL_ 1289 TnDrvStBltShfIntlkCstAvlFlg5 0 "FALSE" 1 "TRUE" ;
VAL_ 1298 HybModeDisp 0 "No Action" 1 "Battery Power" 2 "Engine Power" 3 "Hybrid Power" 4 "Charging with Engine Off" 5 "Charging with Engine On" 6 "Neutral Engine On" 7 "Neutral Engine Off" 8 "Engine Charging" 9 "Engine Power Rear with Battery Front" 10 "Engine Power Rear with Front Wheel Regen" 11 "Undetermined" 12 "Default and Accessory" 13 "Engine Idle" 14 "Reserved 1" 15 "Reserved 2" 16 "Reserved 3" ;
VAL_ 1298 RrClsrLckSts 0 "Unknown" 1 "Unlocked" 2 "Locked" ;
VAL_ 1298 RdHgtActvnIndReq 0 "No Indication" 1 "Raising" 2 "Lowering" 3 "Location Raising" 4 "Location Lowering" 5 "Raising Without Remember" ;
VAL_ 1298 HybModeDispVehCfg 0 "No Action" 1 "Not in Motion" 2 "FWD" 3 "RWD" 4 "4WD" ;
VAL_ 1298 WhlSlpSt 0 "No Slip Detected" 1 "Negative Slip Detected" 2 "Positive Slip Detected" 3 "Slip Detection Fault" ;
VAL_ 1298 SBZALCAVisIndStatRt 0 "FLASHING" 1 "SOLID" 2 "OFF" ;
VAL_ 1298 SBZALCAVisIndStatLt 0 "FLASHING" 1 "SOLID" 2 "OFF" ;
VAL_ 1298 FrFgLmpIO 0 "FALSE" 1 "TRUE" ;
VAL_ 1298 ShftrUnlckdBrktoShfIndOn 0 "FALSE" 1 "TRUE" ;
VAL_ 1298 ShftrLckdBcklPsngrStBltIndOn 0 "FALSE" 1 "TRUE" ;
VAL_ 1298 ShftrLckdBcklDrvrStBltIndOn 0 "FALSE" 1 "TRUE" ;
VAL_ 1298 FuelSysNEmsRltMlfActv 0 "FALSE" 1 "TRUE" ;
VAL_ 1298 DCCnvStblznErrIndOn 0 "FALSE" 1 "TRUE" ;
VAL_ 1298 NtVsnVidBrghtnsSts 0 "No Action" 1 "Min" 2 "Default-2" 3 "Default-1" 4 "Default" 5 "Default+1" 6 "Default+2" 7 "Max" ;
VAL_ 1298 AnmlWrnIndReq 0 "Off" 1 "Animal Advisory" 2 "Animal Alert" ;
VAL_ 1298 RrFgLmpIO 0 "FALSE" 1 "TRUE" ;
VAL_ 1298 IdlRecmndToClEngIO 0 "FALSE" 1 "TRUE" ;
VAL_ 1298 ACCSpdLimSgnUnt 0 "km/h" 1 "mph" ;
VAL_ 1106 StBltShfIntlkCstAvlFlg7 0 "FALSE" 1 "TRUE" ;
VAL_ 1106 StBltShfIntlkCstAvlFlg6 0 "FALSE" 1 "TRUE" ;
VAL_ 1106 StBltShfIntlkCstAvlFlg5 0 "FALSE" 1 "TRUE" ;
VAL_ 1106 StBltShfIntlkCstAvlFlg4 0 "FALSE" 1 "TRUE" ;
VAL_ 1106 ElecMtrARotrTemp_Inv 0 "FALSE" 1 "TRUE" ;
VAL_ 1106 ElecMtrASttrTemp_Inv 0 "FALSE" 1 "TRUE" ;
VAL_ 1106 LvlgSysAlgnMdCstAvlFlg5 0 "FALSE" 1 "TRUE" ;
VAL_ 1106 LvlgSysAlgnMdCstAvlFlg4 0 "FALSE" 1 "TRUE" ;
VAL_ 1106 LvlgSysAlgnMdCstAvlFlg3 0 "FALSE" 1 "TRUE" ;
VAL_ 1106 LvlgSysAlgnMdCstAvlFlg2 0 "FALSE" 1 "TRUE" ;
VAL_ 1106 LvlgSysAlgnMdCstAvlFlg1 0 "FALSE" 1 "TRUE" ;
VAL_ 1386 SecAxlTransStatAchvd_Inv 0 "FALSE" 1 "TRUE" ;
VAL_ 1386 NtVsnVidCntrstSts 0 "No Action" 1 "Min" 2 "Default-2" 3 "Default-1" 4 "Default" 5 "Default+1" 6 "Default+2" 7 "Max" ;
VAL_ 1386 NtVsnFncSts 0 "Normal" 1 "Limited" 2 "Unavailable" 3 "Invalid" ;
VAL_ 1386 HzrdReqActv 0 "FALSE" 1 "TRUE" ;
VAL_ 1386 AllWhlDrvRcmndIndOn 0 "FALSE" 1 "TRUE" ;
VAL_ 1386 ElecShfLckdBcklPsngrStBltIndOn 0 "FALSE" 1 "TRUE" ;
VAL_ 1386 ElecShfLckdBcklDrvrStBltIndOn 0 "FALSE" 1 "TRUE" ;
VAL_ 1386 TrlrBrkgSysProfSts 0 "Default Profile" 1 "Profile 1" 2 "Profile 2" 3 "Profile 3" 4 "Profile 4" 5 "Profile 5" ;
VAL_ 1386 TrlrBrkCnctdIndOn 0 "FALSE" 1 "TRUE" ;
VAL_ 1386 SecAxlTransStatAchvd 0 "Unknown" 1 "Neutral" 2 "Mode 1" ;
VAL_ 1386 RmtPRNDLDispFltIndOn 0 "FALSE" 1 "TRUE" ;
VAL_ 1386 NoKeyFndTryAgnIndOn 0 "FALSE" 1 "TRUE" ;
VAL_ 1386 NoKeyDtdElecShfDndIndOn 0 "FALSE" 1 "TRUE" ;
VAL_ 1386 KeyMisgCkForKeyIndOn 0 "FALSE" 1 "TRUE" ;
VAL_ 1386 PrtctdIdlUnvIndOn 0 "FALSE" 1 "TRUE" ;
VAL_ 1386 PrtctdIdlIndOn 0 "FALSE" 1 "TRUE" ;
VAL_ 1386 NoKeyDtdMechShfDndIndOn 0 "FALSE" 1 "TRUE" ;
VAL_ 1386 ElecShfUnlckdBrkToShfIndOn 0 "FALSE" 1 "TRUE" ;
VAL_ 1386 SpdLmtrSpdLimSgnUnt 0 "km/h" 1 "mph" ;
VAL_ 1386 KMORAI_IndOn 0 "FALSE" 1 "TRUE" ;
VAL_ 1386 EngRcmndDwnsftIndOn 0 "FALSE" 1 "TRUE" ;
VAL_ 1386 ElecShfVehInPrkNeutGrMisusdIO 0 "FALSE" 1 "TRUE" ;
VAL_ 1386 ElecShfShfgToPrkNeutGrMisusdIO 0 "FALSE" 1 "TRUE" ;
VAL_ 1386 ElecShfSelNeutAgnForCarWshMdIO 0 "FALSE" 1 "TRUE" ;
VAL_ 1386 ElecShfPrssNeutAgnForNeutIndOn 0 "FALSE" 1 "TRUE" ;
VAL_ 1386 ElecShfCarWshModeOnDoNTowIndOn 0 "FALSE" 1 "TRUE" ;
VAL_ 1386 SGI2P_AirSpnsnRdHghtActlStsAuth 0 "Faulted" 1 "Entry/Exit" 2 "Lowered 3(Stability)" 3 "Lowered 2 (Sport)" 4 "Lowered 1 (Aero)" 5 "Showroom" 6 "Normal" 7 "Raised 1" 8 "Raised 2" 9 "Raised 3" ;
VAL_ 1386 InvsblTrlrAux2CamConctSts 0 "Unknown" 1 "Not Connected" 2 "Connected" ;
VAL_ 1386 InvsblTrlrAux1CamConctSts 0 "Unknown" 1 "Not Connected" 2 "Connected" ;
VAL_ 1386 ESCSpdLtdIndReq 0 "No Indication" 1 "Countdown" 2 "Limited" ;
VAL_ 1387 RideHghtSeltn7Name 0 "No Action" 1 "Auto" 2 "Raised 2" 3 "Raised" 4 "Normal" 5 "Entry/Exit" 6 "Cargo Loading" 7 "Lowered" ;
VAL_ 1387 RideHghtSeltn6Name 0 "No Action" 1 "Auto" 2 "Raised 2" 3 "Raised" 4 "Normal" 5 "Entry/Exit" 6 "Cargo Loading" 7 "Lowered" ;
VAL_ 1387 RideHghtSeltn5Name 0 "No Action" 1 "Auto" 2 "Raised 2" 3 "Raised" 4 "Normal" 5 "Entry/Exit" 6 "Cargo Loading" 7 "Lowered" ;
VAL_ 1387 LvlgSysServMdCstSetSelable 0 "FALSE" 1 "TRUE" ;
VAL_ 1387 LvlgSysServMdCstSetAval 0 "FALSE" 1 "TRUE" ;
VAL_ 1387 LvlgSysEntEgrsMdCstSetAval 0 "FALSE" 1 "TRUE" ;
VAL_ 1387 LvlgSysAlgnMdCstSetSelable 0 "FALSE" 1 "TRUE" ;
VAL_ 1387 RideHghtSeltn8Name 0 "No Action" 1 "Auto" 2 "Raised 2" 3 "Raised" 4 "Normal" 5 "Entry/Exit" 6 "Cargo Loading" 7 "Lowered" ;
VAL_ 1387 RideHghtSeltn4Unv 0 "FALSE" 1 "TRUE" ;
VAL_ 1387 RideHghtSeltn4Pndg 0 "FALSE" 1 "TRUE" ;
VAL_ 1387 RideHghtSeltn3Unv 0 "FALSE" 1 "TRUE" ;
VAL_ 1387 RideHghtSeltn3Pndg 0 "FALSE" 1 "TRUE" ;
VAL_ 1387 RideHghtSeltn2Unv 0 "FALSE" 1 "TRUE" ;
VAL_ 1387 RideHghtSeltn2Pndg 0 "FALSE" 1 "TRUE" ;
VAL_ 1387 RideHghtSeltn1Unv 0 "FALSE" 1 "TRUE" ;
VAL_ 1387 RideHghtSeltn1Pndg 0 "FALSE" 1 "TRUE" ;
VAL_ 1387 RideHghtSeltn8Unv 0 "FALSE" 1 "TRUE" ;
VAL_ 1387 RideHghtSeltn8Pndg 0 "FALSE" 1 "TRUE" ;
VAL_ 1387 RideHghtSeltn7Unv 0 "FALSE" 1 "TRUE" ;
VAL_ 1387 RideHghtSeltn7Pndg 0 "FALSE" 1 "TRUE" ;
VAL_ 1387 RideHghtSeltn6Unv 0 "FALSE" 1 "TRUE" ;
VAL_ 1387 RideHghtSeltn6Pndg 0 "FALSE" 1 "TRUE" ;
VAL_ 1387 RideHghtSeltn5Unv 0 "FALSE" 1 "TRUE" ;
VAL_ 1387 RideHghtSeltn5Pndg 0 "FALSE" 1 "TRUE" ;
VAL_ 1387 IHVSLR_HtdCushBckLvl2 0 "FALSE" 1 "TRUE" ;
VAL_ 1387 IHVSLR_HtdCushBckLvl1 0 "FALSE" 1 "TRUE" ;
VAL_ 1387 IHVSLR_HtdCushBckAuto 0 "FALSE" 1 "TRUE" ;
VAL_ 1387 IHVSLR_HtdBckMd 0 "FALSE" 1 "TRUE" ;
VAL_ 1387 IHVSLR_HtdBckLvl3 0 "FALSE" 1 "TRUE" ;
VAL_ 1387 IHVSLR_HtdBckLvl2 0 "FALSE" 1 "TRUE" ;
VAL_ 1387 IHVSLR_HtdBckLvl1 0 "FALSE" 1 "TRUE" ;
VAL_ 1387 IHVSLR_HtdBckAuto 0 "FALSE" 1 "TRUE" ;
VAL_ 1387 DispSmrtTowVidOn 0 "FALSE" 1 "TRUE" ;
VAL_ 1387 IHVSLR_VntMd 0 "FALSE" 1 "TRUE" ;
VAL_ 1387 IHVSLR_VntLvl3 0 "FALSE" 1 "TRUE" ;
VAL_ 1387 IHVSLR_VntLvl2 0 "FALSE" 1 "TRUE" ;
VAL_ 1387 IHVSLR_VntLvl1 0 "FALSE" 1 "TRUE" ;
VAL_ 1387 IHVSLR_VntAuto 0 "FALSE" 1 "TRUE" ;
VAL_ 1387 IHVSLR_HtdCushBckMd 0 "FALSE" 1 "TRUE" ;
VAL_ 1387 IHVSLR_HtdCushBckLvl3 0 "FALSE" 1 "TRUE" ;
VAL_ 1401 LvlgSysEntEgrsMdCstAvlFlg6 0 "FALSE" 1 "TRUE" ;
VAL_ 1401 LvlgSysEntEgrsMdCstAvlFlg5 0 "FALSE" 1 "TRUE" ;
VAL_ 1401 LvlgSysEntEgrsMdCstAvlFlg4 0 "FALSE" 1 "TRUE" ;
VAL_ 1401 LvlgSysEntEgrsMdCstAvlFlg3 0 "FALSE" 1 "TRUE" ;
VAL_ 1401 LvlgSysEntEgrsMdCstAvlFlg2 0 "FALSE" 1 "TRUE" ;
VAL_ 1401 LvlgSysEntEgrsMdCstAvlFlg1 0 "FALSE" 1 "TRUE" ;
VAL_ 1401 LvlgSysAlgnMdCstAvlFlg7 0 "FALSE" 1 "TRUE" ;
VAL_ 1401 LvlgSysAlgnMdCstAvlFlg6 0 "FALSE" 1 "TRUE" ;
VAL_ 1401 LvlgSysServMdCstAvlFlg7 0 "FALSE" 1 "TRUE" ;
VAL_ 1401 LvlgSysServMdCstAvlFlg6 0 "FALSE" 1 "TRUE" ;
VAL_ 1401 LvlgSysServMdCstAvlFlg5 0 "FALSE" 1 "TRUE" ;
VAL_ 1401 LvlgSysServMdCstAvlFlg4 0 "FALSE" 1 "TRUE" ;
VAL_ 1401 LvlgSysServMdCstAvlFlg3 0 "FALSE" 1 "TRUE" ;
VAL_ 1401 LvlgSysServMdCstAvlFlg2 0 "FALSE" 1 "TRUE" ;
VAL_ 1401 LvlgSysServMdCstAvlFlg1 0 "FALSE" 1 "TRUE" ;
VAL_ 1401 LvlgSysEntEgrsMdCstAvlFlg7 0 "FALSE" 1 "TRUE" ;
VAL_ 1401 VehMassEstSts 0 "Undetermined" 1 "Degraded" 2 "Normal" ;
VAL_ 1401 TmngBltChgIndOn 0 "FALSE" 1 "TRUE" ;
VAL_ 1401 FuelConsmpHvyIndReq 0 "No Indication" 1 "Range" 2 "Low Fuel and Range" ;
VAL_ 1043 IHVSRR_HtdCushBckLvl2 0 "FALSE" 1 "TRUE" ;
VAL_ 1043 IHVSRR_HtdCushBckLvl1 0 "FALSE" 1 "TRUE" ;
VAL_ 1043 IHVSRR_HtdCushBckAuto 0 "FALSE" 1 "TRUE" ;
VAL_ 1043 IHVSRR_HtdBckMd 0 "FALSE" 1 "TRUE" ;
VAL_ 1043 IHVSRR_HtdBckLvl3 0 "FALSE" 1 "TRUE" ;
VAL_ 1043 IHVSRR_HtdBckLvl2 0 "FALSE" 1 "TRUE" ;
VAL_ 1043 IHVSRR_HtdBckLvl1 0 "FALSE" 1 "TRUE" ;
VAL_ 1043 IHVSRR_HtdBckAuto 0 "FALSE" 1 "TRUE" ;
VAL_ 1043 IHVSRR_VntMd 0 "FALSE" 1 "TRUE" ;
VAL_ 1043 IHVSRR_VntLvl3 0 "FALSE" 1 "TRUE" ;
VAL_ 1043 IHVSRR_VntLvl2 0 "FALSE" 1 "TRUE" ;
VAL_ 1043 IHVSRR_VntLvl1 0 "FALSE" 1 "TRUE" ;
VAL_ 1043 IHVSRR_VntAuto 0 "FALSE" 1 "TRUE" ;
VAL_ 1043 IHVSRR_HtdCushBckMd 0 "FALSE" 1 "TRUE" ;
VAL_ 1043 IHVSRR_HtdCushBckLvl3 0 "FALSE" 1 "TRUE" ;
VAL_ 1414 MemStorCmpltdIndReq 0 "No Indication" 1 "Memory Button 1" 2 "Memory Button 2" 3 "Memory Button 3" 4 "Memory Button Exit" ;
VAL_ 1414 MemRclHldUntilCmpltIndReq 0 "No Indication" 1 "Memory Button 1" 2 "Memory Button 2" 3 "Memory Button 3" 4 "Memory Button Exit" ;
VAL_ 1414 TrlrArtclnAngCalSts 0 "Unknown" 1 "Available" 2 "Degraded" 3 "Unavailable" ;
VAL_ 1414 PrkAsstActIndCmnd 0 "FALSE" 1 "TRUE" ;
VAL_ 1414 InrTlgtOpnIndOn 0 "FALSE" 1 "TRUE" ;
VAL_ 1414 PPVehRadioMutReq 0 "Unknown" 1 "Mute Requested" 2 "Mute Not Requested" ;
VAL_ 1414 RrStrgFlrIndOn 0 "FALSE" 1 "TRUE" ;
VAL_ 1414 MemStorTmdOutIndOn 0 "FALSE" 1 "TRUE" ;
VAL_ 1414 MemStorPrssSetFrstIndOn 0 "FALSE" 1 "TRUE" ;
VAL_ 1414 MemSeeAutoRclSetsIndOn 0 "FALSE" 1 "TRUE" ;
VAL_ 1414 OffRdMdDrvlnVisDispVal 0 "Setting_Unknown" 1 "Custom_Mode_1" 2 "Custom_Mode_2" 3 "Custom_Mode_3" 4 "Custom_Mode_4" 5 "Custom_Mode_5" 6 "Custom_Mode_6" 7 "Custom_Mode_7" ;
VAL_ 1414 OffRdMdBrkPedVisDispVal 0 "Setting_Unknown" 1 "Custom_Mode_1" 2 "Custom_Mode_2" 3 "Custom_Mode_3" 4 "Custom_Mode_4" 5 "Custom_Mode_5" 6 "Custom_Mode_6" 7 "Custom_Mode_7" ;
VAL_ 1414 OffRdMdActvAerodynsVisDispVal 0 "Setting_Unknown" 1 "Custom_Mode_1" 2 "Custom_Mode_2" 3 "Custom_Mode_3" 4 "Custom_Mode_4" 5 "Custom_Mode_5" 6 "Custom_Mode_6" 7 "Custom_Mode_7" ;
VAL_ 1414 OffRdMdSpnsnVisDispVal 0 "Setting_Unknown" 1 "Custom_Mode_1" 2 "Custom_Mode_2" 3 "Custom_Mode_3" 4 "Custom_Mode_4" 5 "Custom_Mode_5" 6 "Custom_Mode_6" 7 "Custom_Mode_7" ;
VAL_ 1414 OffRdMdPwrtrnVisDispVal 0 "Setting_Unknown" 1 "Custom_Mode_1" 2 "Custom_Mode_2" 3 "Custom_Mode_3" 4 "Custom_Mode_4" 5 "Custom_Mode_5" 6 "Custom_Mode_6" 7 "Custom_Mode_7" ;
VAL_ 1414 OffRdMdESCVisDispVal 0 "Setting_Unknown" 1 "Custom_Mode_1" 2 "Custom_Mode_2" 3 "Custom_Mode_3" 4 "Custom_Mode_4" 5 "Custom_Mode_5" 6 "Custom_Mode_6" 7 "Custom_Mode_7" ;
VAL_ 1414 OffRdMdRideHghtVisDispVal 0 "Setting_Unknown" 1 "Custom_Mode_1" 2 "Custom_Mode_2" 3 "Custom_Mode_3" 4 "Custom_Mode_4" 5 "Custom_Mode_5" 6 "Custom_Mode_6" 7 "Custom_Mode_7" ;
VAL_ 1414 OffRdMdStrgVisDispVal 0 "Setting_Unknown" 1 "Custom_Mode_1" 2 "Custom_Mode_2" 3 "Custom_Mode_3" 4 "Custom_Mode_4" 5 "Custom_Mode_5" 6 "Custom_Mode_6" 7 "Custom_Mode_7" ;
VAL_ 1414 PTOEngRunTmrCstAvlFlg11 0 "FALSE" 1 "TRUE" ;
VAL_ 1414 PTOEngRunTmrCstAvlFlg10 0 "FALSE" 1 "TRUE" ;
VAL_ 1414 BrkSysTwoFtdDrvDtdIndOn 0 "FALSE" 1 "TRUE" ;
VAL_ 1414 RrCrsTrfcAutoBrkgOffIndOn 0 "FALSE" 1 "TRUE" ;
VAL_ 1414 ACCTrlrGapSetIndOn 0 "FALSE" 1 "TRUE" ;
VAL_ 1414 OffRdMdSndVisDispVal 0 "Setting_Unknown" 1 "Custom_Mode_1" 2 "Custom_Mode_2" 3 "Custom_Mode_3" 4 "Custom_Mode_4" 5 "Custom_Mode_5" 6 "Custom_Mode_6" 7 "Custom_Mode_7" ;
VAL_ 1061 TowHaulMdPwrtrnVisDispVal 0 "Setting_Unknown" 1 "Custom_Mode_1" 2 "Custom_Mode_2" 3 "Custom_Mode_3" 4 "Custom_Mode_4" 5 "Custom_Mode_5" 6 "Custom_Mode_6" 7 "Custom_Mode_7" ;
VAL_ 1061 TowHaulMdESCVisDispVal 0 "Setting_Unknown" 1 "Custom_Mode_1" 2 "Custom_Mode_2" 3 "Custom_Mode_3" 4 "Custom_Mode_4" 5 "Custom_Mode_5" 6 "Custom_Mode_6" 7 "Custom_Mode_7" ;
VAL_ 1061 TowHaulMdBrkPedVisDispVal 0 "Setting_Unknown" 1 "Custom_Mode_1" 2 "Custom_Mode_2" 3 "Custom_Mode_3" 4 "Custom_Mode_4" 5 "Custom_Mode_5" 6 "Custom_Mode_6" 7 "Custom_Mode_7" ;
VAL_ 1061 TowHaulMdActvAerodynsVisDispVal 0 "Setting_Unknown" 1 "Custom_Mode_1" 2 "Custom_Mode_2" 3 "Custom_Mode_3" 4 "Custom_Mode_4" 5 "Custom_Mode_5" 6 "Custom_Mode_6" 7 "Custom_Mode_7" ;
VAL_ 1061 TowHaulMdStrgVisDispVal 0 "Setting_Unknown" 1 "Custom_Mode_1" 2 "Custom_Mode_2" 3 "Custom_Mode_3" 4 "Custom_Mode_4" 5 "Custom_Mode_5" 6 "Custom_Mode_6" 7 "Custom_Mode_7" ;
VAL_ 1061 TowHaulMdSpnsnVisDispVal 0 "Setting_Unknown" 1 "Custom_Mode_1" 2 "Custom_Mode_2" 3 "Custom_Mode_3" 4 "Custom_Mode_4" 5 "Custom_Mode_5" 6 "Custom_Mode_6" 7 "Custom_Mode_7" ;
VAL_ 1061 TowHaulMdSndVisDispVal 0 "Setting_Unknown" 1 "Custom_Mode_1" 2 "Custom_Mode_2" 3 "Custom_Mode_3" 4 "Custom_Mode_4" 5 "Custom_Mode_5" 6 "Custom_Mode_6" 7 "Custom_Mode_7" ;
VAL_ 1061 TowHaulMdDrvlnVisDispVal 0 "Setting_Unknown" 1 "Custom_Mode_1" 2 "Custom_Mode_2" 3 "Custom_Mode_3" 4 "Custom_Mode_4" 5 "Custom_Mode_5" 6 "Custom_Mode_6" 7 "Custom_Mode_7" ;
VAL_ 1061 RrAxlLckIO 0 "FALSE" 1 "TRUE" ;
VAL_ 1061 FrntAxlLckIO 0 "FALSE" 1 "TRUE" ;
VAL_ 1061 AxlLckUnavailIndReq 0 "No Action" 1 "Rear Axle Not Locked" 2 "Not in 4WD Low" 3 "Speed Too High" 4 "Not During Hill Decent" 5 "Generic Unavailable" ;
VAL_ 1061 TowHaulMdRideHghtVisDispVal 0 "Setting_Unknown" 1 "Custom_Mode_1" 2 "Custom_Mode_2" 3 "Custom_Mode_3" 4 "Custom_Mode_4" 5 "Custom_Mode_5" 6 "Custom_Mode_6" 7 "Custom_Mode_7" ;
VAL_ 1061 TirePrsLRInr_Inv 0 "FALSE" 1 "TRUE" ;
VAL_ 1061 AutoTrnspHdActvnCstAvlFlg1 0 "FALSE" 1 "TRUE" ;
VAL_ 1061 TirePrsStatLRInr 0 "Unknown" 1 "Nominal" 2 "Low - Service Now" 3 "Low" 4 "Low - Extended Mobility" 5 "High" ;
VAL_ 1061 AutoTrnspHdActvnCstCurrSetVal 0 "Setting Unknown" 1 "Active" 2 "Inactive" ;
VAL_ 1426 TirePrsRRInr_Inv 0 "FALSE" 1 "TRUE" ;
VAL_ 1426 AutoTrnspHdActvnCstAvlFlg5 0 "FALSE" 1 "TRUE" ;
VAL_ 1426 AutoTrnspHdActvnCstAvlFlg4 0 "FALSE" 1 "TRUE" ;
VAL_ 1426 AutoTrnspHdActvnCstAvlFlg3 0 "FALSE" 1 "TRUE" ;
VAL_ 1426 AutoTrnspHdActvnCstAvlFlg2 0 "FALSE" 1 "TRUE" ;
VAL_ 1426 TirePrsStatRRInr 0 "Unknown" 1 "Nominal" 2 "Low - Service Now" 3 "Low" 4 "Low - Extended Mobility" 5 "High" ;
VAL_ 1426 PTOEngRunTmrCstAvlFlg6 0 "FALSE" 1 "TRUE" ;
VAL_ 1426 PTOEngRunTmrCstAvlFlg5 0 "FALSE" 1 "TRUE" ;
VAL_ 1426 PTOEngRunTmrCstAvlFlg4 0 "FALSE" 1 "TRUE" ;
VAL_ 1426 PTOEngRunTmrCstAvlFlg3 0 "FALSE" 1 "TRUE" ;
VAL_ 1426 AxlLcksServIO 0 "FALSE" 1 "TRUE" ;
VAL_ 1426 AutoTrnspHdActvnCstSetAval 0 "FALSE" 1 "TRUE" ;
VAL_ 1426 AutoTrnspHdActvnCstAvlFlg7 0 "FALSE" 1 "TRUE" ;
VAL_ 1426 AutoTrnspHdActvnCstAvlFlg6 0 "FALSE" 1 "TRUE" ;
VAL_ 1426 PTOSet1SpdCstAvlFlg1 0 "FALSE" 1 "TRUE" ;
VAL_ 1426 PTOModeCstAvlFlg2 0 "FALSE" 1 "TRUE" ;
VAL_ 1426 PTOModeCstAvlFlg1 0 "FALSE" 1 "TRUE" ;
VAL_ 1426 PTOEngSpdTypCstAvlFlg2 0 "FALSE" 1 "TRUE" ;
VAL_ 1426 PTOEngSpdTypCstAvlFlg1 0 "FALSE" 1 "TRUE" ;
VAL_ 1426 PTOEngRunTmrCstAvlFlg9 0 "FALSE" 1 "TRUE" ;
VAL_ 1426 PTOEngRunTmrCstAvlFlg8 0 "FALSE" 1 "TRUE" ;
VAL_ 1426 PTOEngRunTmrCstAvlFlg7 0 "FALSE" 1 "TRUE" ;
VAL_ 1426 PTOSet1SpdCstAvlFlg3 0 "FALSE" 1 "TRUE" ;
VAL_ 1426 PTOSet1SpdCstAvlFlg2 0 "FALSE" 1 "TRUE" ;
VAL_ 1426 PTOSet1SpdCstAvlFlg15 0 "FALSE" 1 "TRUE" ;
VAL_ 1426 PTOSet1SpdCstAvlFlg14 0 "FALSE" 1 "TRUE" ;
VAL_ 1426 PTOSet1SpdCstAvlFlg13 0 "FALSE" 1 "TRUE" ;
VAL_ 1426 PTOSet1SpdCstAvlFlg12 0 "FALSE" 1 "TRUE" ;
VAL_ 1426 PTOSet1SpdCstAvlFlg11 0 "FALSE" 1 "TRUE" ;
VAL_ 1426 PTOSet1SpdCstAvlFlg10 0 "FALSE" 1 "TRUE" ;
VAL_ 1426 PTOSet2SpdCstAvlFlg10 0 "FALSE" 1 "TRUE" ;
VAL_ 1426 PTOSet2SpdCstAvlFlg1 0 "FALSE" 1 "TRUE" ;
VAL_ 1426 PTOSet1SpdCstAvlFlg9 0 "FALSE" 1 "TRUE" ;
VAL_ 1426 PTOSet1SpdCstAvlFlg8 0 "FALSE" 1 "TRUE" ;
VAL_ 1426 PTOSet1SpdCstAvlFlg7 0 "FALSE" 1 "TRUE" ;
VAL_ 1426 PTOSet1SpdCstAvlFlg6 0 "FALSE" 1 "TRUE" ;
VAL_ 1426 PTOSet1SpdCstAvlFlg5 0 "FALSE" 1 "TRUE" ;
VAL_ 1426 PTOSet1SpdCstAvlFlg4 0 "FALSE" 1 "TRUE" ;
VAL_ 1449 PTOPrssAndRelBrkPedIndOn 0 "FALSE" 1 "TRUE" ;
VAL_ 1449 PTOModeCstSetAval 0 "FALSE" 1 "TRUE" ;
VAL_ 1449 PTOMblModeTransInGrIndOn 0 "FALSE" 1 "TRUE" ;
VAL_ 1449 PTOEngSpdTypCstSetAval 0 "FALSE" 1 "TRUE" ;
VAL_ 1449 PTOEngRunTmrCstSetAval 0 "FALSE" 1 "TRUE" ;
VAL_ 1449 PTOModeCstCurrSetVal 0 "Setting Unknown" 1 "Standard" 2 "Remote" ;
VAL_ 1466 PTOSet2SpdCstCurrSetVal 0 "Setting Unknown" 1 "RPM 1900" 2 "RPM 2000" 3 "RPM 2100" 4 "RPM 2200" 5 "RPM 2300" 6 "RPM 2400" 7 "RPM 2500" 8 "RPM 2600" 9 "RPM 2700" 10 "RPM 2800" 11 "RPM 2900" 12 "RPM 3000" 13 "RPM 3100" 14 "RPM 3200" 15 "RPM 3300" ;
VAL_ 1466 PTOSet1SpdCstCurrSetVal 0 "Setting Unknown" 1 "RPM 1100" 2 "RPM 1200" 3 "RPM 1300" 4 "RPM 1400" 5 "RPM 1500" 6 "RPM 1600" 7 "RPM 1700" 8 "RPM 1800" 9 "RPM 1900" 10 "RPM 2000" 11 "RPM 2100" 12 "RPM 2200" 13 "RPM 2300" 14 "RPM 2400" 15 "RPM 2500" ;
